VERSION "$Format:%h$"

NS_ :

BS_:

BU_: APB APP APS BCCEN BDY DAS DBG EAS EPAS EPAS2 EPAS3S EPB EPBM ESP GTW GTWU IBST IC MCU OCS PARK PARK3 RADAR RCM RT3000 SCCM SDM SEC TAS TAS2 TAS2DBG TOOL TPMS VCSEATD VCSEATP
VAL_TABLE_ APP_ussSequenceEnum 12 "APP_USS_SEQUENCE_FMS_FAST" 2 "APP_USS_SEQUENCE_UPA" 0 "APP_USS_SEQUENCE_FMS_SLOW" ;
VAL_TABLE_ BC_firstRollRecallIndex 1 "BC_FIRST_ROW_RECALL_PASSENGER" 0 "BC_FIRST_ROW_RECALL_DRIVER" ;
VAL_TABLE_ BC_indicatorLStatus 3 "default" 2 "Failed" 1 "On" 0 "Off" ;
VAL_TABLE_ BC_indicatorRStatus 3 "default" 2 "Failed" 1 "On" 0 "Off" ;
VAL_TABLE_ CAN_error 9 "CAN_ERROR_TWO_SLAVES" 8 "CAN_ERROR_TWO_MASTERS" 7 "CAN_ERROR_RESET_CMD" 6 "CAN_ERROR_OVERRUN" 5 "CAN_ERROR_TX" 4 "CAN_ERROR_RX" 3 "CAN_ERROR_NODEBUG" 2 "CAN_ERROR_DATA" 1 "CAN_ERROR_CHECKSUM" 0 "CAN_ERROR_LENGTH" ;
VAL_TABLE_ CHG_inputRelayState 3 "CHG_INPUT_RELAY_SNA" 2 "CHG_INPUT_RELAY_OPEN" 1 "CHG_INPUT_RELAY_L1_CLOSED" 0 "CHG_INPUT_RELAY_L2_CLOSED" ;
VAL_TABLE_ CHG_phaseConfig 4 "PHASE_CONFIG_SNA" 3 "TWO_PHASE_DELTA_THREE_CHGPH" 2 "TWO_PHASE_DELTA_TWO_CHGPH" 1 "THREE_PHASE" 0 "SINGLE_PHASE" ;
VAL_TABLE_ CH_NM_wakeUpReason 3 "CH_WAKEUP_REASON_RESET" 2 "CH_WAKEUP_REASON_SWITCH_INPUT" 1 "CH_WAKEUP_REASON_ECU_SPECIFIC" 0 "CH_WAKEUP_REASON_NONE" ;
VAL_TABLE_ ChassisType 3 "CHASSIS_MODEL3" 2 "CHASSIS_MODELX" 1 "CHASSIS_MODELS" 0 "CHASSIS_UNKNOWN" ;
VAL_TABLE_ DAS_DepartureWarning 3 "SNA" 2 "RIGHT_WARNING" 1 "LEFT_WARNING" 0 "NONE" ;
VAL_TABLE_ DAS_LaneDepartureWarningStatus 3 "DEGRADED" 2 "FAILED" 1 "INACTIVE" 0 "ACTIVE" ;
VAL_TABLE_ DAS_LaneTypeColor 15 "SNA" 14 "INVALID_YELLOW" 13 "BOTTS_DOTS_YELLOW" 12 "DOUBLE_LANE_YELLOW" 11 "ROAD_EDGE_YELLOW" 10 "UNDECIDED_YELLOW" 9 "SOLID_YELLOW" 8 "DASHED_YELLOW" 6 "INVALID" 5 "BOTTS_DOTS" 4 "DOUBLE_LANE" 3 "ROAD_EDGE" 2 "UNDECIDED" 1 "SOLID" 0 "DASHED" ;
VAL_TABLE_ DAS_NM_keepAwakeReason 2 "DAS_KEEPAWAKE_REASON_TELEMETRY" 1 "DAS_KEEPAWAKE_REASON_PRECONDITIONING" 0 "DAS_KEEPAWAKE_REASON_NONE_SNA" ;
VAL_TABLE_ DAS_SignType 255 "E_INVALID_SIGN" 254 "NO_SIGN_DETECTED" 221 "STANDARD_ELECTR_END_OF_NO_PASSING" 220 "STANDARD_ELECTR_NO_PASSING_START" 201 "REGULAR_END_OF_NO_PASSING" 200 "REGULAR_NO_PASSING_START" 176 "REGULAR_END_OF_PLAYGROUND_AREA" 175 "REGULAR_PLAYGROUND_AREA_BEGIN" 174 "STANDARD_REGULAR_END_OF_EXPRESSWAY" 173 "STANDARD_REGULAR_EXPRESSWAY_BEGIN" 172 "STANDARD_REGULAR_END_OF_MOTORWAY" 171 "STANDARD_REGULAR_MOTORWAY_BEGIN" 129 "STANDARD_ELECTRONIC_145" 128 "STANDARD_ELECTRONIC_135" 127 "STANDARD_ELECTRONIC_125" 126 "STANDARD_ELECTRONIC_115" 125 "STANDARD_ELECTRONIC_105" 124 "STANDARD_ELECTRONIC_95" 123 "STANDARD_ELECTRONIC_85" 122 "STANDARD_ELECTRONIC_75" 121 "STANDARD_ELECTRONIC_65" 120 "STANDARD_ELECTRONIC_55" 119 "STANDARD_ELECTRONIC_45" 118 "STANDARD_ELECTRONIC_35" 117 "STANDARD_ELECTRONIC_25" 116 "STANDARD_ELECTRONIC_15" 115 "STANDARD_ELECTRONIC_5" 114 "STANDARD_REGULAR_145" 113 "STANDARD_REGULAR_135" 112 "STANDARD_REGULAR_125" 111 "STANDARD_REGULAR_115" 110 "STANDARD_REGULAR_105" 109 "STANDARD_REGULAR_95" 108 "STANDARD_REGULAR_85" 107 "STANDARD_REGULAR_75" 106 "STANDARD_REGULAR_65" 105 "STANDARD_REGULAR_55" 104 "STANDARD_REGULAR_45" 103 "STANDARD_REGULAR_35" 102 "STANDARD_REGULAR_25" 101 "STANDARD_REGULAR_15" 100 "STANDARD_REGULAR_5" 65 "ELECTRIC_GEN_END_ALL_RESTRICTION" 64 "REGULAR_GEN_END_ALL_RESTRICT" 50 "ELECTRONIC_END_OF_NUM_RESTRICT" 41 "STANDARD_ELECTRONIC_140" 40 "STANDARD_ELECTRONIC_130" 39 "STANDARD_ELECTRONIC_120" 38 "STANDARD_ELECTRONIC_110" 37 "STANDARD_ELECTRONIC_100" 36 "STANDARD_ELECTRONIC_90" 35 "STANDARD_ELECTRONIC_80" 34 "STANDARD_ELECTRONIC_70" 33 "STANDARD_ELECTRONIC_60" 32 "STANDARD_ELECTRONIC_50" 31 "STANDARD_ELECTRONIC_40" 30 "STANDARD_ELECTRONIC_30" 29 "STANDARD_ELECTRONIC_20" 28 "STANDARD_ELECTRONIC_10" 20 "STANDARD_END_OF_NUM_RESTRICTION" 13 "STANDARD_REGULAR_140" 12 "STANDARD_REGULAR_130" 11 "STANDARD_REGULAR_120" 10 "STANDARD_REGULAR_110" 9 "STANDARD_REGULAR_100" 8 "STANDARD_REGULAR_90" 7 "STANDARD_REGULAR_80" 6 "STANDARD_REGULAR_70" 5 "STANDARD_REGULAR_60" 4 "STANDARD_REGULAR_50" 3 "STANDARD_REGULAR_40" 2 "STANDARD_REGULAR_30" 1 "STANDARD_REGULAR_20" 0 "STANDARD_REGULAR_10" ;
VAL_TABLE_ DAS_SteeringAngleRequest 16384 "ZERO_ANGLE" ;
VAL_TABLE_ DAS_aebEvent 3 "AEB_SNA" 2 "AEB_FAULT" 1 "AEB_ACTIVE" 0 "AEB_NOT_ACTIVE" ;
VAL_TABLE_ DAS_csa_internal_state 4 "CSA_INTERNAL_STATE_ENABLE_HOLD" 3 "CSA_INTERNAL_STATE_ENABLE_ACCELEROMETER" 2 "CSA_INTERNAL_STATE_ENABLE_PREDICTED" 1 "CSA_INTERNAL_STATE_AVAILABLE" 0 "CSA_INTERNAL_STATE_UNAVAILABLE" ;
VAL_TABLE_ DAS_eyeqAlert 3 "a003_eyeq_watchdog_reset" 2 "a002_eyeq_communication_timeout" 1 "a001_eyeq_boot_failure" ;
VAL_TABLE_ DAS_fork 3 "FORK_UNAVAILABLE" 2 "FORK_SELECTED" 1 "FORK_AVAILABLE" 0 "FORK_NONE" ;
VAL_TABLE_ DAS_hazardLightRequest 3 "DAS_REQUEST_HAZARDS_SNA" 2 "DAS_REQUEST_HAZARDS_UNUSED" 1 "DAS_REQUEST_HAZARDS_ON" 0 "DAS_REQUEST_HAZARDS_OFF" ;
VAL_TABLE_ DAS_headlightRequest 3 "DAS_HEADLIGHT_REQUEST_INVALID" 1 "DAS_HEADLIGHT_REQUEST_ON" 0 "DAS_HEADLIGHT_REQUEST_OFF" ;
VAL_TABLE_ DAS_highLowBeamDecision 3 "DAS_HIGH_BEAM_SNA" 2 "DAS_HIGH_BEAM_ON" 1 "DAS_HIGH_BEAM_OFF" 0 "DAS_HIGH_BEAM_UNDECIDED" ;
VAL_TABLE_ DAS_highLowBeamOffReason 5 "HIGH_BEAM_OFF_REASON_SNA" 4 "HIGH_BEAM_OFF_REASON_HEAD_LIGHT" 3 "HIGH_BEAM_OFF_REASON_AMBIENT_LIGHT" 2 "HIGH_BEAM_OFF_REASON_MOVING_RADAR_TARGET" 1 "HIGH_BEAM_OFF_REASON_MOVING_VISION_TARGET" 0 "HIGH_BEAM_ON" ;
VAL_TABLE_ DAS_infoIndex 255 "DAS_INFO_END" 24 "DAS_INFO_EYEQ_FFS" 23 "DAS_INFO_EYEQ_APP" 20 "DAS_INFO_UDS_PROTOCOL_BOOTCRC" 19 "DAS_INFO_VERSION_DEPRECATED" 18 "DAS_INFO_BOOTLOADER_GITHASH" 17 "DAS_INFO_APP_GITHASH" 16 "DAS_INFO_EYEQ_BOOT" 15 "DAS_INFO_BOOTLOADER_CRC" 14 "DAS_INFO_BOOTLOADER_SVN" 13 "DAS_INFO_APP_CRC" 11 "DAS_INFO_PCBAID_ASSYID_USAGEID" 10 "DAS_INFO_BUILD_HWID_COMPONENTID" 9 "DAS_INFO_DEPRECATED_9" 8 "DAS_INFO_DEPRECATED_8" 7 "DAS_INFO_DEPRECATED_7" 6 "DAS_INFO_DEPRECATED_6" 5 "DAS_INFO_DEPRECATED_5" 4 "DAS_INFO_DEPRECATED_4" 3 "DAS_INFO_DEPRECATED_3" 2 "DAS_INFO_DEPRECATED_2" 1 "DAS_INFO_DEPRECATED_1" 0 "DAS_INFO_DEPRECATED_0" ;
VAL_TABLE_ DAS_locMode 3 "DAS_LOC_DRIVERLESS" 2 "DAS_LOC_RESTRICTED" 1 "DAS_LOC_NORMAL" 0 "DAS_LOC_OFF" ;
VAL_TABLE_ DAS_locRequest 4 "DAS_RQ_PARK" 3 "DAS_RQ_HOLD" 2 "DAS_RQ_BACKWARD" 1 "DAS_RQ_FORWARD" 0 "DAS_RQ_IDLE" ;
VAL_TABLE_ DAS_locState 7 "DAS_LOC_FAULT_SNA" 6 "DAS_LOC_AEB_ACTIVE" 2 "DAS_LOC_CANCEL_SILENT" 1 "DAS_LOC_CANCEL_GENERIC" 0 "DAS_LOC_HEALTHY" ;
VAL_TABLE_ DAS_steeringLKAOperatingStatus 3 "Not_available" 2 "Not_used" 1 "Operating" 0 "Inhibited" ;
VAL_TABLE_ DAS_sw019_020_taskID 33 "MAX_TASK_ID" 32 "TASKS_ISOTERM_A72" 31 "TASKS_ISOTERM_SMS" 30 "TASKS_APP_1HZ" 29 "TASKS_APP_1KHZ" 28 "TASKS_SMS_SERIAL" 27 "TASKS_CAN_AP_RX" 26 "TASKS_CAN_AP_TX" 25 "TASKS_TMU" 24 "TASKS_WDG_TASK" 23 "TASKS_MBX_RELAY" 22 "TASKS_MBX_SCS_RX_HIGH" 21 "TASKS_MBX_SCS_RX_LOW" 20 "TASKS_MBX_SCS_TX_HIGH" 19 "TASKS_MBX_SCS_TX_LOW" 18 "TASKS_MBX_AP_RX_HIGH" 17 "TASKS_MBX_AP_RX_LOW" 16 "TASKS_MBX_AP_TX_HIGH" 15 "TASKS_MBX_AP_TX_LOW" 14 "TASKS_VEH_CAN" 13 "TASKS_RADAR_CAN" 12 "TASKS_CH_CAN" 11 "TASKS_PARTY_CAN" 10 "TASK_DEBUG_SMS_SERIAL_RX" 9 "TASK_DEBUG_SERIAL_TX" 8 "TASKS_SMS_SMS_UART_RX" 7 "TASKS_SMS_SMS_UART_TX" 6 "TASK_SMS_SMS_UART_TX" 5 "TASKS_VEHICLE" 4 "TASKS_MOBILEYE" 3 "TASKS_UDS" 2 "TASKS_CAN" 1 "TASKS_INIT" 0 "TASKS_RESERVED" ;
VAL_TABLE_ DAS_sw021_tempSensorId 4 "DDR_TEMP_SENSOR" 3 "CAMERA_TEMP_SENSOR" 2 "EYE_Q_TEMP_SENSOR_1" 1 "EYE_Q_TEMP_SENSOR_0" 0 "EXTERNAL_TEMP_SENSOR" ;
VAL_TABLE_ DAS_sw022_operation 4 "Erase All" 3 "Delete" 2 "Read" 1 "Write" 0 "Initialize" ;
VAL_TABLE_ DAS_sw024_heaterState 2 "SHORT" 1 "OPEN" 0 "NORMAL" ;
VAL_TABLE_ DAS_sw037_issue 1 "Invalid parameters" 0 "Failed to read" ;
VAL_TABLE_ DAS_sw043_mesp_health_main_state 172 "EYEQ_MESP_MAIN_STATE_TAC2" 170 "EYEQ_MESP_MAIN_STATE_DV" 146 "EYEQ_MESP_MAIN_STATE_VISION_INIT_PENDING" 133 "EYEQ_MESP_MAIN_STATE_TAC2_INIT_PENDING" 130 "EYEQ_MESP_MAIN_STATE_SPC_INIT_PENDING" 129 "EYEQ_MESP_MAIN_STATE_SPTAC_INIT_PENDING" 34 "EYEQ_MESP_MAIN_STATE_SPC" 33 "EYEQ_MESP_MAIN_STATE_SPTAC" 2 "EYEQ_MESP_MAIN_STATE_VISION" ;
VAL_TABLE_ DAS_sw043_mobileye_status 24 "MOBILEYE_STATUS_UNDEFINED" 23 "MOBILEYE_STATUS_TEARDOWN_FLASH_ACCESS_MODE" 22 "MOBILEYE_STATUS_FLASH_READ_MODE" 21 "MOBILEYE_STATUS_SETUP_FLASH_ACCESS_MODE" 20 "MOBILEYE_STATUS_RUNNING_SPTAC_MODE" 19 "MOBILEYE_STATUS_SPTAC_INIT_SENT" 18 "MOBILEYE_STATUS_WAITING_FOR_SPTAC_INIT" 17 "MOBILEYE_STATUS_BURN_EDR_MODE" 16 "MOBILEYE_STATUS_SPC_INIT_SENT" 15 "MOBILEYE_STATUS_WAITING_FOR_SPC_INIT" 14 "MOBILEYE_STATUS_ERROR" 13 "MOBILEYE_STATUS_LATCHING_FAILURE" 12 "MOBILEYE_STATUS_UPDATING" 11 "MOBILEYE_STATUS_RUNNING_DV_MODE" 10 "MOBILEYE_STATUS_WAITING_FOR_DV" 9 "MOBILEYE_STATUS_RUNNING_TAC_MODE" 8 "MOBILEYE_STATUS_RUNNING_SPC_MODE" 7 "MOBILEYE_STATUS_RUNNING_VISION_MODE" 6 "MOBILEYE_STATUS_TAC_INIT_SENT" 5 "MOBILEYE_STATUS_WAITING_FOR_TAC_INIT" 4 "MOBILEYE_STATUS_VISION_INIT_SENT" 3 "MOBILEYE_STATUS_WAITING_FOR_VISION_INIT" 2 "MOBILEYE_STATUS_WAITING_FOR_BOOT" 1 "MOBILEYE_STATUS_POWER_OFF" 0 "MOBILEYE_STATUS_POWER_CYCLE" ;
VAL_TABLE_ DAS_turnIndicatorRequest 3 "DAS_TURN_INDICATOR_CANCEL" 2 "DAS_TURN_INDICATOR_RIGHT" 1 "DAS_TURN_INDICATOR_LEFT" 0 "DAS_TURN_INDICATOR_NONE" ;
VAL_TABLE_ DAS_turnIndicatorRequestReason 12 "DAS_CANCEL_SUMMMON" 11 "DAS_ACTIVE_SUMMMON" 10 "DAS_CANCEL_INTERSECTION" 9 "DAS_ACTIVE_INTERSECTION" 8 "DAS_ACTIVE_COMMANDED_LANE_CHANGE" 7 "DAS_CANCEL_MERGE" 6 "DAS_ACTIVE_MERGE" 5 "DAS_CANCEL_FORK" 4 "DAS_CANCEL_LANE_CHANGE" 3 "DAS_ACTIVE_FORK" 2 "DAS_ACTIVE_SPEED_LANE_CHANGE" 1 "DAS_ACTIVE_NAV_LANE_CHANGE" 0 "DAS_NONE" ;
VAL_TABLE_ DAS_wiperSpeed 15 "DAS_WIPER_SPEED_INVALID" 14 "DAS_WIPER_SPEED_14" 13 "DAS_WIPER_SPEED_13" 12 "DAS_WIPER_SPEED_12" 11 "DAS_WIPER_SPEED_11" 10 "DAS_WIPER_SPEED_10" 9 "DAS_WIPER_SPEED_9" 8 "DAS_WIPER_SPEED_8" 7 "DAS_WIPER_SPEED_7" 6 "DAS_WIPER_SPEED_6" 5 "DAS_WIPER_SPEED_5" 4 "DAS_WIPER_SPEED_4" 3 "DAS_WIPER_SPEED_3" 2 "DAS_WIPER_SPEED_2" 1 "DAS_WIPER_SPEED_1" 0 "DAS_WIPER_SPEED_OFF" ;
VAL_TABLE_ DI_aebState 7 "AEB_CAN_STATE_SNA" 4 "AEB_CAN_STATE_FAULT" 3 "AEB_CAN_STATE_STANDSTILL" 2 "AEB_CAN_STATE_ENABLED" 1 "AEB_CAN_STATE_STANDBY" 0 "AEB_CAN_STATE_UNAVAILABLE" ;
VAL_TABLE_ DI_crsState 7 "DI_CRS_FAULT" 3 "DI_CRS_SLOWDOWN" 2 "DI_CRS_ACTIVE" 1 "DI_CRS_STANDBY" 0 "DI_CRS_UNAVAILABLE" ;
VAL_TABLE_ DI_immobilizerState 6 "DI_IMM_STATE_FAULT" 5 "DI_IMM_STATE_RESET" 4 "DI_IMM_STATE_IDLE" 3 "DI_IMM_STATE_DISARMED" 2 "DI_IMM_STATE_AUTHENTICATING" 1 "DI_IMM_STATE_REQUEST" 0 "DI_IMM_STATE_INIT_SNA" ;
VAL_TABLE_ DI_locState 7 "DI_LOC_FAULT" 6 "DI_LOC_ABORTING" 5 "DI_LOC_PAUSED" 4 "DI_LOC_STANDSTILL" 3 "DI_LOC_OVERRIDE" 2 "DI_LOC_ACTIVE" 1 "DI_LOC_STANDBY" 0 "DI_LOC_UNAVAILABLE" ;
VAL_TABLE_ DI_onePedalDrivingState 8 "DI_OPD_NUM_STATES" 7 "DI_OPD_MOTOR_BLEND_IN" 6 "DI_OPD_NO_MOTOR" 5 "DI_OPD_MOTOR_BLEND_OUT_ACTIVE" 4 "DI_OPD_MOTOR_BLEND_OUT_PENDING" 3 "DI_OPD_NOMINAL" 2 "DI_OPD_STANDBY" 1 "DI_OPD_QUICK_BRAKE_RAMP" 0 "DI_OPD_UNAVAILABLE" ;
VAL_TABLE_ DI_parkBrakeState 15 "DI_PBRK_SNA" 7 "DI_PBRK_RELEASING" 6 "DI_PBRK_PANIC_SKID" 5 "DI_PBRK_PANIC_EPB" 4 "DI_PBRK_FAULTED" 3 "DI_PBRK_APPLIED" 2 "DI_PBRK_REQUESTED" 1 "DI_PBRK_RELEASED" 0 "DI_PBRK_UNAVAILABLE" ;
VAL_TABLE_ DI_pmmStatus 3 "DI_PMM_SNA" 1 "DI_PMM_ACTIVE" 0 "DI_PMM_INACTIVE" ;
VAL_TABLE_ DI_state 4 "DI_STATE_ENABLE" 3 "DI_STATE_ABORT" 2 "DI_STATE_FAULT" 1 "DI_STATE_STANDBY" 0 "DI_STATE_UNAVAILABLE" ;
VAL_TABLE_ DI_systemState 4 "DI_SYS_ENABLE" 3 "DI_SYS_ABORT" 2 "DI_SYS_FAULT" 1 "DI_SYS_STANDBY" 0 "DI_SYS_UNAVAILABLE" ;
VAL_TABLE_ DI_tractionControlMode 5 "TC_DYNO_MODE" 4 "TC_ROLLS_MODE" 3 "TC_DEV_MODE_2" 2 "TC_DEV_MODE_1" 1 "TC_SLIP_START" 0 "TC_NORMAL" ;
VAL_TABLE_ DI_vdcCommandABS 4 "MODIFY_BY_ABS_NO_GMA_NO_EBD" 3 "MODIFY_BY_ABS_NO_GMA" 2 "MODIFY_BY_ABS_ALL" 1 "FEED_THROUGH" 0 "NO_COMMAND" ;
VAL_TABLE_ DI_vdcCommandType 3 "VDC_SLIP_COMMAND" 2 "VDC_TORQUE_COMMAND" 1 "BTC_TORQUE_COMMAND" 0 "NO_TORQUE_COMMAND" ;
VAL_TABLE_ DTC_VALUES 3 "UNABLE_TO_TEST_DTC" 2 "FAILED_DTC" 1 "PASSED_DTC" 0 "NOT_TESTED_DTC" ;
VAL_TABLE_ EFUSE_airCompressorStatus 7 "EFUSE_AIR_COMPRESSOR_STATUS_SNA" 5 "EFUSE_AIR_COMPRESSOR_STATUS_RETRY_AVAILABLE" 4 "EFUSE_AIR_COMPRESSOR_STATUS_FAULT" 3 "EFUSE_AIR_COMPRESSOR_STATUS_TURNING_ON" 2 "EFUSE_AIR_COMPRESSOR_STATUS_TURNING_OFF" 1 "EFUSE_AIR_COMPRESSOR_STATUS_ON" 0 "EFUSE_AIR_COMPRESSOR_STATUS_OFF" ;
VAL_TABLE_ EFUSE_loadshedLevel 3 "EFUSE_LOADSHED_LEVEL_3" 2 "EFUSE_LOADSHED_LEVEL_2" 1 "EFUSE_LOADSHED_LEVEL_1" 0 "EFUSE_LOADSHED_LEVEL_NONE_SNA" ;
VAL_TABLE_ EPBM_alerts 128 "EPBM_a128_unused" 127 "EPBM_a127_unused" 126 "EPBM_a126_unused" 125 "EPBM_a125_unused" 124 "EPBM_a124_unused" 123 "EPBM_a123_unused" 122 "EPBM_a122_unused" 121 "EPBM_a121_unused" 120 "EPBM_a120_unused" 119 "EPBM_a119_unused" 118 "EPBM_a118_unused" 117 "EPBM_a117_usedFallbackValues" 116 "EPBM_a116_rightPVoltageHigh" 115 "EPBM_a115_rightNVoltageLow" 114 "EPBM_a114_unparkNotAllowed" 113 "EPBM_a113_calFaultRight" 112 "EPBM_a112_calFaultLeft" 111 "EPBM_a111_calWarningRight" 110 "EPBM_a110_calWarningLeft" 109 "EPBM_a109_unused" 108 "EPBM_a108_unused" 107 "EPBM_a107_currentWarning" 106 "EPBM_a106_voltageWarning" 105 "EPBM_a105_epbWentToSleep" 104 "EPBM_a104_epbStillAsleep" 103 "EPBM_a103_targetNotReachedR" 102 "EPBM_a102_targetNotReachedL" 101 "EPBM_a101_calibrationFault" 100 "EPBM_a100_calibrationWarning" 99 "EPBM_a099_unused" 98 "EPBM_a098_pmMia" 97 "EPBM_a097_parkMia" 96 "EPBM_a096_selfParkAborted" 95 "EPBM_a095_invalidConfig" 94 "EPBM_a094_unused" 93 "EPBM_a093_dasMIA" 92 "EPBM_a092_noCurrentCalR" 91 "EPBM_a091_spuriousEncIntR" 90 "EPBM_a090_rightUnderRelease" 89 "EPBM_a089_rightOverRelease" 88 "EPBM_a088_rightUnderApply" 87 "EPBM_a087_rightOverApply" 86 "EPBM_a086_rightSubstateErr" 85 "EPBM_a085_rightPvUv" 84 "EPBM_a084_rightPvOv" 83 "EPBM_a083_rightNvUv" 82 "EPBM_a082_rightNvOv" 81 "EPBM_a081_rightNHalfBridge" 80 "EPBM_a080_rightPHalfBridge" 79 "EPBM_a079_rightDriveDuration" 78 "EPBM_a078_rightEnaStuckLow" 77 "EPBM_a077_rightEnaStuckHigh" 76 "EPBM_a076_rightPOpen" 75 "EPBM_a075_rightNOpen" 74 "EPBM_a074_rightPShort" 73 "EPBM_a073_rightNShort" 72 "EPBM_a072_rightShortApply" 71 "EPBM_a071_rightEndStop" 70 "EPBM_a070_rightUc" 69 "EPBM_a069_rightOc" 68 "EPBM_a068_rightEncoderSna" 67 "EPBM_a067_rightEncIrrational" 66 "EPBM_a066_rightIdleOc" 65 "EPBM_a065_rightEncIntrpt" 64 "EPBM_a064_unused" 63 "EPBM_a063_unused" 62 "EPBM_a062_diGearInvld" 61 "EPBM_a061_maxCycles2" 60 "EPBM_a060_maxCycles1" 59 "EPBM_a059_battMismatch" 58 "EPBM_a058_5vLost" 57 "EPBM_a057_12vUv" 56 "EPBM_a056_12vOv" 55 "EPBM_a055_stackOverflow" 54 "EPBM_a054_unused" 53 "EPBM_a053_unused" 52 "EPBM_a052_leftPVoltageHigh" 51 "EPBM_a051_leftNVoltageLow" 50 "EPBM_a050_mcuMIA" 49 "EPBM_a049_espMIA" 48 "EPBM_a048_chgMIA" 47 "EPBM_a047_epbMIA" 46 "EPBM_a046_sccmMIA" 45 "EPBM_a045_gtwMIA" 44 "EPBM_a044_diMIA" 43 "EPBM_a043_absMIA" 42 "EPBM_a042_spiRead" 41 "EPBM_a041_spiOpen" 40 "EPBM_a040_memoryError" 39 "EPBM_a039_watchdogReset" 38 "EPBM_a038_eeprom" 37 "EPBM_a037_firmware" 36 "EPBM_a036_canOverrun" 35 "EPBM_a035_canErr" 34 "EPBM_a034_canData" 33 "EPBM_a033_canHardware" 32 "EPBM_a032_reqStateErr" 31 "EPBM_a031_stateErr" 30 "EPBM_a030_interProcSpi" 29 "EPBM_a029_canDisabled" 28 "EPBM_a028_noCurrentCalL" 27 "EPBM_a027_spuriousEncIntL" 26 "EPBM_a026_leftUnderRelease" 25 "EPBM_a025_leftOverRelease" 24 "EPBM_a024_leftUnderApply" 23 "EPBM_a023_leftOverApply" 22 "EPBM_a022_leftSubstateErr" 21 "EPBM_a021_leftPvUv" 20 "EPBM_a020_leftPvOv" 19 "EPBM_a019_leftNvUv" 18 "EPBM_a018_leftNvOv" 17 "EPBM_a017_leftNHalfBridge" 16 "EPBM_a016_leftPHalfBridge" 15 "EPBM_a015_leftDriveDuration" 14 "EPBM_a014_leftEnaStuckLow" 13 "EPBM_a013_leftEnaStuckHigh" 12 "EPBM_a012_leftPOpen" 11 "EPBM_a011_leftNOpen" 10 "EPBM_a010_leftPShort" 9 "EPBM_a009_leftNShort" 8 "EPBM_a008_leftShortApply" 7 "EPBM_a007_leftEndStop" 6 "EPBM_a006_leftUc" 5 "EPBM_a005_leftOc" 4 "EPBM_a004_leftEncoderSna" 3 "EPBM_a003_leftEncIrrational" 2 "EPBM_a002_leftIdleOc" 1 "EPBM_a001_leftEncIntrpt" ;
VAL_TABLE_ EPBM_clampCurrentMonitor 3 "CURRENT_TARGET_NOT_REACHED" 2 "CURRENT_TARGET_REACHED" 0 "CURRENT_MONITOR_IDLE" ;
VAL_TABLE_ EPBM_substate 4 "EPBM_SUBSTATE_CTRL_FAULT" 3 "EPBM_SUBSTATE_FAULT" 2 "EPBM_SUBSTATE_RELEASING" 1 "EPBM_SUBSTATE_APPLYING" 0 "EPBM_SUBSTATE_STATIONARY" ;
VAL_TABLE_ EPB_CAN_error 8 "DENIED" 7 "BUSY" 6 "NODEBUG" 5 "INVALID" 4 "SEQUENCE" 3 "CHECKSUM" 2 "LENGTH_LONG" 1 "LENGTH_SHORT" 0 "NO_ERROR" ;
VAL_TABLE_ EPB_EEP_datatype 5 "EEP_CHASSIS_TYPE_DATATYPE" 4 "EEP_EPAS_TYPE_DATATYPE" 3 "EEP_STATISTICS_DATATYPE" 2 "EEP_BRAKE_HW_TYPE_DATATYPE" 1 "EEP_STATE_DATATYPE" 0 "EEP_NONE_DATATYPE" ;
VAL_TABLE_ EPB_alerts 8204 "EPB_u012_mcuParkUnavailable" 8203 "EPB_u011_parkSlope" 8202 "EPB_u010_serviceModeEnabled" 8201 "EPB_u009_towModeEnabled" 8200 "EPB_u008_turnOnCarToPark" 8199 "EPB_u007_dynNotApplied" 8198 "EPB_u006_epbNotReleased" 8197 "EPB_u005_epbProblem" 8196 "EPB_u004_pressFootBrake" 8195 "EPB_u003_dynamicBrakeApplied" 8194 "EPB_u002_carMayRoll" 8193 "EPB_u001_calibrationRequired" 192 "EPB_a192_unused" 191 "EPB_a191_unused" 190 "EPB_a190_unused" 189 "EPB_a189_unused" 188 "EPB_a188_unused" 187 "EPB_a187_unused" 186 "EPB_a186_unused" 185 "EPB_a185_unused" 184 "EPB_a184_unused" 183 "EPB_a183_unused" 182 "EPB_a182_unused" 181 "EPB_a181_unused" 180 "EPB_a180_unused" 179 "EPB_a179_unused" 178 "EPB_a178_unused" 177 "EPB_a177_unused" 176 "EPB_a176_unused" 175 "EPB_a175_unused" 174 "EPB_a174_unused" 173 "EPB_a173_unused" 172 "EPB_a172_unused" 171 "EPB_a171_unused" 170 "EPB_a170_unused" 169 "EPB_a169_unused" 168 "EPB_a168_unused" 167 "EPB_a167_unused" 166 "EPB_a166_unused" 165 "EPB_a165_unused" 164 "EPB_a164_unused" 163 "EPB_a163_unused" 162 "EPB_a162_unused" 161 "EPB_a161_unused" 160 "EPB_a160_unused" 159 "EPB_a159_unused" 158 "EPB_a158_unused" 157 "EPB_a157_unused" 156 "EPB_a156_unused" 155 "EPB_a155_unused" 154 "EPB_a154_unused" 153 "EPB_a153_unused" 152 "EPB_a152_unused" 151 "EPB_a151_unused" 150 "EPB_a150_unused" 149 "EPB_a149_unused" 148 "EPB_a148_unused" 147 "EPB_a147_unused" 146 "EPB_a146_unused" 145 "EPB_a145_unused" 144 "EPB_a144_unused" 143 "EPB_a143_unused" 142 "EPB_a142_unused" 141 "EPB_a141_unused" 140 "EPB_a140_unused" 139 "EPB_a139_unused" 138 "EPB_a138_unused" 137 "EPB_a137_unused" 136 "EPB_a136_unused" 135 "EPB_a135_unused" 134 "EPB_a134_unused" 133 "EPB_a133_unused" 132 "EPB_a132_unused" 131 "EPB_a131_unused" 130 "EPB_a130_unused" 129 "EPB_a129_unparkNotAllowed" 128 "EPB_a128_followedDiToPark" 127 "EPB_a127_oocSpeedViolation" 126 "EPB_a126_ShortApplyUF" 125 "EPB_a125_gradeTooSteep" 124 "EPB_a124_releaseDistanceR" 123 "EPB_a123_releaseDistanceL" 122 "EPB_a122_freeRollMdEpbmMismatch" 121 "EPB_a121_releaseLogR" 120 "EPB_a120_releaseLogL" 119 "EPB_a119_freeRollingModeAborted" 118 "EPB_a118_freeRollingModeActive" 117 "EPB_a117_usedFallbackValues" 116 "EPB_a116_unableToCalcGrade" 115 "EPB_a115_currentWarning" 114 "EPB_a114_voltageWarning" 113 "EPB_a113_calFaultRight" 112 "EPB_a112_calFaultLeft" 111 "EPB_a111_calWarningRight" 110 "EPB_a110_calWarningLeft" 109 "EPB_a109_rightPVoltageHigh" 108 "EPB_a108_rightNVoltageLow" 107 "EPB_a107_leftPVoltageHigh" 106 "EPB_a106_leftNVoltageLow" 105 "EPB_a105_epbmWentToSleep" 104 "EPB_a104_epbmStillAsleep" 103 "EPB_a103_eepromUpdated" 102 "EPB_a102_eepromCorrupt" 101 "EPB_a101_calibrationFault" 100 "EPB_a100_calibrationWarning" 99 "EPB_a099_pmMia" 98 "EPB_a098_parkMia" 97 "EPB_a097_selfParkAborted" 96 "EPB_a096_epasMia" 95 "EPB_a095_invalidConfig" 94 "EPB_a094_inhibitEac" 93 "EPB_a093_dasMIA" 92 "EPB_a092_obsolete" 91 "EPB_a091_spuriousEncIntR" 90 "EPB_a090_noCurrentCalR" 89 "EPB_a089_motorShortedApplyR" 88 "EPB_a088_motorShortedReleaseR" 87 "EPB_a087_rightFirstShortApply" 86 "EPB_a086_rightSubstateErr" 85 "EPB_a085_rightPvUv" 84 "EPB_a084_rightPvOv" 83 "EPB_a083_rightNvUv" 82 "EPB_a082_rightNvOv" 81 "EPB_a081_rightNHalfBridge" 80 "EPB_a080_rightPHalfBridge" 79 "EPB_a079_rightDriveDuration" 78 "EPB_a078_rightEnaStuckLow" 77 "EPB_a077_rightEnaStuckHigh" 76 "EPB_a076_rightPOpen" 75 "EPB_a075_rightNOpen" 74 "EPB_a074_rightPShort" 73 "EPB_a073_rightNShort" 72 "EPB_a072_rightShortApply" 71 "EPB_a071_rightEndStop" 70 "EPB_a070_rightUc" 69 "EPB_a069_rightOc" 68 "EPB_a068_rightEncoderSna" 67 "EPB_a067_rightEncIrrational" 66 "EPB_a066_rightIdleOc" 65 "EPB_a065_rightEncIntrpt" 64 "EPB_a064_EPBMTimeout" 63 "EPB_a063_parkWhlSpeed" 62 "EPB_a062_diGearInvld" 61 "EPB_a061_maxCycles2" 60 "EPB_a060_maxCycles1" 59 "EPB_a059_battMismatch" 58 "EPB_a058_5vLost" 57 "EPB_a057_12vUv" 56 "EPB_a056_12vOv" 55 "EPB_a055_stackOverflow" 54 "EPB_a054_severeShortApply" 53 "EPB_a053_epbNotReleased" 52 "EPB_a052_epbProblem" 51 "EPB_a051_epbNotApplied" 50 "EPB_a050_resetRequired" 49 "EPB_a049_espMIA" 48 "EPB_a048_mcuMIA" 47 "EPB_a047_epbmMIA" 46 "EPB_a046_sccmMIA" 45 "EPB_a045_gtwMIA" 44 "EPB_a044_diMIA" 43 "EPB_a043_absMIA" 42 "EPB_a042_spiRead" 41 "EPB_a041_spiOpen" 40 "EPB_a040_memoryError" 39 "EPB_a039_watchdogReset" 38 "EPB_a038_eeprom" 37 "EPB_a037_firmware" 36 "EPB_a036_canOverrun" 35 "EPB_a035_canErr" 34 "EPB_a034_canData" 33 "EPB_a033_canHardware" 32 "EPB_a032_canDisabled" 31 "EPB_a031_chgMIA" 30 "EPB_a030_interProcSpi" 29 "EPB_a029_stateErr" 28 "EPB_a028_reqStateErr" 27 "EPB_a027_spuriousEncIntL" 26 "EPB_a026_noCurrentCalL" 25 "EPB_a025_motorShortedApplyL" 24 "EPB_a024_motorShortedReleaseL" 23 "EPB_a023_leftFirstShortApply" 22 "EPB_a022_leftSubstateErr" 21 "EPB_a021_leftPvUv" 20 "EPB_a020_leftPvOv" 19 "EPB_a019_leftNvUv" 18 "EPB_a018_leftNvOv" 17 "EPB_a017_leftNHalfBridge" 16 "EPB_a016_leftPHalfBridge" 15 "EPB_a015_leftDriveDuration" 14 "EPB_a014_leftEnaStuckLow" 13 "EPB_a013_leftEnaStuckHigh" 12 "EPB_a012_leftPOpen" 11 "EPB_a011_leftNOpen" 10 "EPB_a010_leftPShort" 9 "EPB_a009_leftNShort" 8 "EPB_a008_leftShortApply" 7 "EPB_a007_leftEndStop" 6 "EPB_a006_leftUc" 5 "EPB_a005_leftOc" 4 "EPB_a004_leftEncoderSna" 3 "EPB_a003_leftEncIrrational" 2 "EPB_a002_leftIdleOc" 1 "EPB_a001_leftEncIntrpt" ;
VAL_TABLE_ EPB_calibrationState 4 "CAL_BUSY" 3 "CAL_FAULT" 2 "CAL_WARN" 1 "CAL_NORMAL" 0 "CAL_UNAVAILABLE" ;
VAL_TABLE_ EPB_chassisType 3 "EPB_CHASSIS_TYPE_NONE" 1 "EPB_CHASSIS_TYPE_X" 0 "EPB_CHASSIS_TYPE_S" ;
VAL_TABLE_ EPB_debugDataSelect 9 "EPB_DEBUG_9" 8 "EPB_DEBUG_8" 7 "EPB_DEBUG_7" 6 "EPB_DEBUG_6" 5 "EPB_DEBUG_5" 4 "EPB_DEBUG_4" 3 "EPB_DEBUG_3" 2 "EPB_DEBUG_2" 1 "EPB_DEBUG_1" 0 "EPB_DEBUG_0" ;
VAL_TABLE_ EPB_eacState 4 "EAC_LATERAL_CTRL_INHIBIT" 3 "EAC_LATERAL_CTRL_AUTOPARK" 2 "EAC_LATERAL_CTRL_CONTINUOUS" 1 "EAC_LATERAL_CTRL_MOMENTARY" 0 "EAC_LATERAL_CTRL_INIT" ;
VAL_TABLE_ EPB_freeRollingModeStatus 2 "EPB_FREE_ROLLING_MODE_ENABLED" 1 "EPB_FREE_ROLLING_MODE_AVAILABLE" 0 "EPB_FREE_ROLLING_MODE_UNAVAILABLE" ;
VAL_TABLE_ EPB_ignoreCan 3 "IGNORE_CAN_SNA" 2 "IGNORE_CAN_UPDATE" 1 "LISTEN_TO_CAN" 0 "IGNORE_CAN_BOOT" ;
VAL_TABLE_ EPB_inhibitEacReason 15 "EPB_EAC_FAULT_ELK_LKA_SEQ" 14 "EPB_EAC_FAULT_SCT_EAC_MISMATCH" 13 "EPB_EAC_FAULT_AC_MISMATCH" 12 "EPB_EAC_FAULT_LSS_MISMATCH" 11 "EPB_EAC_FAULT_DURATION_ELK" 10 "EPB_EAC_FAULT_HYSTERESIS_ELK" 9 "EPB_EAC_CONFIG_MISMATCH" 8 "EPB_EAC_FAULT_EPAS" 7 "EPB_EAC_ANGLE_BOUNDS" 6 "EPB_EAC_FAULT_HYSTERESIS_LKA" 5 "EPB_EAC_FAULT_DURATION_LKA" 4 "EPB_EAC_FAULT_DI_FAULT" 3 "EPB_EAC_FAULT_DI_MIA" 2 "EPB_EAC_FAULT_EPAS_MIA" 1 "EPB_EAC_FAULT_DAS_MIA" 0 "EPB_EAC_FAULT_NONE" ;
VAL_TABLE_ EPB_motorSel 1 "RIGHT" 0 "LEFT" ;
VAL_TABLE_ EPB_offsetApplied 2 "EPB_OFFSET_RELEASE" 1 "EPB_OFFSET_DYNAMIC" 0 "EPB_OFFSET_STATIC" ;
VAL_TABLE_ EPB_selfParkFaultReason 23 "EPB_SELFPARKFAULT_PM_MISMATCH" 22 "EPB_SELFPARKFAULT_EPAS_NOT_LEARNED" 21 "EPB_SELFPARKFAULT_CALIBRATION" 20 "EPB_SELFPARKFAULT_DI_STATE_INVALID" 19 "EPB_SELFPARKFAULT_EPB_FAULT" 18 "EPB_SELFPARKFAULT_MISMATCH" 17 "EPB_SELFPARKFAULT_OOC" 16 "EPB_SELFPARKFAULT_PM_REQUEST" 15 "EPB_SELFPARKFAULT_PM_MIA" 14 "EPB_SELFPARKFAULT_PARK_MIA" 13 "EPB_SELFPARKFAULT_EXTERNAL" 12 "EPB_SELFPARKFAULT_SPEED" 11 "EPB_SELFPARKFAULT_EPBM_REQUEST" 10 "EPB_SELFPARKFAULT_EAC_NOT_ALLOWED" 9 "EPB_SELFPARKFAULT_CH_CAN_FAULT" 8 "EPB_SELFPARKFAULT_ESP_FAULT" 7 "EPB_SELFPARKFAULT_DAS_FAULT" 6 "EPB_SELFPARKFAULT_DI_APC_FAULT" 5 "EPB_SELFPARKFAULT_DI_FAULT" 4 "EPB_SELFPARKFAULT_EPBM_MIA" 3 "EPB_SELFPARKFAULT_ESP_MIA" 2 "EPB_SELFPARKFAULT_DAS_MIA" 1 "EPB_SELFPARKFAULT_DI_MIA" 0 "EPB_SELFPARKFAULT_NONE" ;
VAL_TABLE_ EPB_selfParkState 5 "SELFPARK_FAULT" 4 "SELFPARK_COMPLETE" 3 "SELFPARK_ACTIVE" 2 "SELFPARK_ARMED" 1 "SELFPARK_IDLE" 0 "SELFPARK_INIT" ;
VAL_TABLE_ EPB_state 7 "EPB_STATE_SNA" 6 "EPB_STATE_SELFPARK" 5 "EPB_STATE_SERVICE" 4 "EPB_STATE_START" 3 "EPB_STATE_HANDBRAKE" 2 "EPB_STATE_PARK" 1 "EPB_STATE_DYNAMIC" 0 "EPB_STATE_OPEN" ;
VAL_TABLE_ EPB_statsDataSelect 9 "EPB_STATS_9" 8 "EPB_STATS_8" 7 "EPB_STATS_7" 6 "EPB_STATS_6" 5 "EPB_STATS_5" 4 "EPB_STATS_4" 3 "EPB_STATS_3" 2 "EPB_STATS_2" 1 "EPB_STATS_1" 0 "EPB_STATS_0" ;
VAL_TABLE_ EPB_statsSelect 5 "EPB_MAX_DATA" 4 "EPB_DYNAMIC_DATA" 3 "EPB_STATIC3_DATA" 2 "EPB_STATIC2_DATA" 1 "EPB_STATIC1_DATA" 0 "EPB_STATIC0_DATA" ;
VAL_TABLE_ EPB_substate 4 "EPB_SUBSTATE_CLR_FAULT" 3 "EPB_SUBSTATE_FAULT" 2 "EPB_SUBSTATE_RELEASING" 1 "EPB_SUBSTATE_APPLYING" 0 "EPB_SUBSTATE_STATIONARY" ;
VAL_TABLE_ EPB_syncState 3 "EPB_SYNCSTATE_READY" 2 "EPB_SYNCSTATE_SYNCING" 1 "EPB_SYNCSTATE_LOSTSYNC" 0 "EPB_SYNCSTATE_INIT" ;
VAL_TABLE_ EPB_telltale 7 "EPB_TELLTALE_SNA" 3 "LAMP_RED_FLASH_AMBER_ON" 2 "LAMP_AMBER_ON" 1 "LAMP_RED_ON" 0 "LAMP_OFF" ;
VAL_TABLE_ ESP_WheelRotation 3 "WR_NOT_DEFINABLE" 2 "WR_STANDSTILL" 1 "WR_BACKWARD" 0 "WR_FORWARD" ;
VAL_TABLE_ ESP_vdcActuatorState 3 "VDC_COMMAND_INVALID" 2 "VDC_ACTUATOR_AVAILABLE" 1 "VDC_ACTUATOR_DEGRADED" 0 "VDC_ACTUATOR_UNAVAILABLE" ;
VAL_TABLE_ ESP_wheelSaturation 2 "OTHER_LIMIT" 1 "BSC_SLIP_LIMIT" 0 "NOT_SATURATED" ;
VAL_TABLE_ GTW_airSuspensionInstalled 5 "TESLA_ADAPTIVE" 4 "TESLA_PLUS" 3 "TESLA_STANDARD" 2 "PLUS" 1 "STANDARD" 0 "NONE" ;
VAL_TABLE_ GTW_autopilot 4 "BASIC" 3 "SELF_DRIVING" 2 "ENHANCED" 1 "HIGHWAY" 0 "NONE" ;
VAL_TABLE_ GTW_autopilotCameraType 2 "RCCB_CAMERAS" 1 "RCCC_CAMERAS" 0 "UNKNOWN" ;
VAL_TABLE_ GTW_bodyControlsType 1 "TESLA" 0 "PEKTRON" ;
VAL_TABLE_ GTW_brakeHwType 2 "BREMBO_P44_MANDO_43MOC" 1 "BREMBO_P40_MANDO_43MOC" 0 "BREMBO_P40_BREMBO_P28_BREMBO_EPB" ;
VAL_TABLE_ GTW_chassisType 2 "MODEL_3_CHASSIS" 1 "MODEL_X_CHASSIS" 0 "MODEL_S_CHASSIS" ;
VAL_TABLE_ GTW_dasHw 4 "TESLA_AP3" 3 "PARKER_PASCAL_2_5" 2 "PARKER_PASCAL" 1 "MONOCAM" 0 "NONE" ;
VAL_TABLE_ GTW_diagDriveState 4 "DIAG_DRIVE_KEYPAIRING" 3 "DIAG_DRIVE_ENGINEERING" 2 "DIAG_DRIVE_SERVICE" 1 "DIAG_DRIVE_FACTORY" 0 "DIAG_DRIVE_OFF_SNA" ;
VAL_TABLE_ GTW_efuseType 1 "TESLA_REV1" 0 "NONE" ;
VAL_TABLE_ GTW_epasType 4 "MANDO_VGR66_GEN3" 3 "MANDO_VGR66" 2 "MANDO_FGR64" 1 "BOSCH_L405" 0 "BOSCH_L538" ;
VAL_TABLE_ GTW_forwardRadarHw 2 "CONTI_ARS410" 1 "BOSCH_MRR14" 0 "NONE" ;
VAL_TABLE_ GTW_fourWheelDrive 3 "SNA" 2 "UNUSED" 1 "4WD" 0 "2WD" ;
VAL_TABLE_ GTW_parkAssistInstalled 3 "VALEO_5" 2 "BOSCH_5" 1 "BOSCH_4_5" 0 "NONE" ;
VAL_TABLE_ GTW_parkSensorGeometryType 2 "MODELX" 1 "MODELS_2" 0 "MODELS" ;
VAL_TABLE_ GTW_pedalCalRxEnable 1 "ENABLED" 0 "DISABLED" ;
VAL_TABLE_ GTW_pedalCalTargetCurve 6 "SNA" 5 "PEDAL_CURVE_5" 4 "PEDAL_CURVE_4" 3 "PEDAL_CURVE_3" 2 "PEDAL_CURVE_2" 1 "PEDAL_CURVE_1" 0 "PEDAL_CURVE_0" ;
VAL_TABLE_ GTW_performanceConfig 7 "P7" 6 "P6" 5 "P5" 4 "P4" 3 "P3" 2 "P2" 1 "P1" 0 "CONFIG_SNA" ;
VAL_TABLE_ GTW_radarPosition 2 "MODELX" 1 "MODELS_2" 0 "MODELS" ;
VAL_TABLE_ GTW_rearDriveUnitType 1 "SMALL_REAR" 0 "LARGE_REAR" ;
VAL_TABLE_ GTW_restraintControlsType 1 "BOSCH_RCM" 0 "SDM" ;
VAL_TABLE_ GTW_updateInProgress 3 "UPDATE_IN_PROGRESS_SNA" 2 "UPDATE_IN_PROGRESS_NOT_USED" 1 "UPDATE_IN_PROGRESS" 0 "UPDATE_NOT_IN_PROGRESS" ;
VAL_TABLE_ GTW_wheelType 31 "CONFIG_SNA" 26 "TEMPEST_19_SONICSILVER" 25 "TWINTURBINE_21_CARBON" 24 "TWINTURBINE_21_SILVER" 23 "SLIPSTREAM_19_CARBON" 22 "SLIPSTREAM_20_SLVRBLK" 21 "SLIPSTREAM_20_CARBON" 20 "ARACHNID_21_GREY" 19 "ARACHNID_21_BLACK" 18 "ARACHNID_21_SILVER" 17 "TURBINE_22_BLACK" 16 "AERO_TURBINE_20_SLVRBLK" 15 "CYCLONE_19_GREY" 14 "TURBINE_22_SILVER" 13 "AERO_TURBINE_20_SILVER" 12 "HELIX_20_SILVER" 11 "AERO_TURBINE_19_BLACK" 10 "AERO_TURBINE_19_METAL" 9 "TURBINE_19_CHARCOAL" 8 "TURBINE_19" 7 "SUPER_21_SILVER" 6 "SUPER_21_GRAY" 5 "CHARCOAL_21_EURO" 4 "AERO_19" 3 "SILVER_21_EURO" 2 "CHARCOAL_21" 1 "SILVER_21" 0 "BASE_19" ;
VAL_TABLE_ IBST_brakeInputStroke 1023 "INPUT_STROKE_SNA" 1022 "INPUT_STROKE_NOT_VALID" ;
VAL_TABLE_ IC_LEDBrightnessRank 3 "LED_RANK_PA9" 2 "LED_RANK_PA8" 1 "LED_RANK_PA7" 0 "UNKNOWN" ;
VAL_TABLE_ IC_alerts 16 "IC_a016_unused" 15 "IC_a015_unused" 14 "IC_a014_unused" 13 "IC_a013_OVERTEMP_OFF" 12 "IC_a012_CAN_TX_ERRCNT" 11 "IC_a011_CAN_RX_ERRCNT" 10 "IC_a010_SPI_READ" 9 "IC_a009_SPI_OPEN" 8 "IC_a008_MEMORY_ERROR" 7 "IC_a007_WATCHDOG_RESET" 6 "IC_a006_FPGA_ERROR" 5 "IC_a005_FIRMWARE" 4 "IC_a004_CAN_OVERRUN" 3 "IC_a003_CAN_ERR" 2 "IC_a002_CAN_TX" 1 "IC_a001_CAN_RX" 0 "IC_DO_NOT_USE" ;
VAL_TABLE_ IC_componentHardwareRevision 252 "CONFIGURABLE_HWID_PLACEHOLDER" ;
VAL_TABLE_ IC_state 3 "IC_STATE_SOFTWARE_FAULT" 2 "IC_STATE_IDLE" 1 "IC_STATE_CLEAR_TEGRA_RESET" 0 "IC_STATE_WAIT_FOR_TEGRA_PWRGOOD" ;
VAL_TABLE_ LVPowerState 3 "LV_FAULT" 2 "LV_GOING_DOWN" 1 "LV_ON" 0 "LV_OFF" ;
VAL_TABLE_ LogConditions 0 "parkOocValid CH_DAS_pmmLoggingRequest 1" ;
VAL_TABLE_ MCU_clusterInstantOn 0 "ALLOW_CLUSTER_OFF_SNA" ;
VAL_TABLE_ MCU_enableCreepTorqueCH 1 "CREEP_MODE_ON" 0 "CREEP_MODE_OFF" ;
VAL_TABLE_ MCU_factoryMode 1 "FACTORY_MODE" 0 "NORMAL_MODE" ;
VAL_TABLE_ MCU_gatewaySleepReq 7 "SNA" 3 "LOW_POWER_SLEEP" 2 "SLEEP_NOW" 1 "OK_TO_START" 0 "DONT_SLEEP" ;
VAL_TABLE_ MCU_requestBusWake 3 "SNA" 2 "BUS_MAY_SLEEP_NOW" 1 "BUS_AWAKE_NOW" ;
VAL_TABLE_ MCU_setRcpFront 255 "SNA" ;
VAL_TABLE_ MCU_setRcpRear 255 "SNA" ;
VAL_TABLE_ MCU_trailerMode 1 "TRAILER_MODE_ON" 0 "TRAILER_MODE_OFF" ;
VAL_TABLE_ MCU_zeroSpeedConfirmed 3 "SNA" 2 "UNUSED" 1 "CONFIRMED" 0 "CANCELED" ;
VAL_TABLE_ PARK_version 255 "SNA" ;
VAL_TABLE_ PM_ebrCmdState 8 "EBR_CMD_INVALID" 6 "EBR_CMD_VALID" 0 "EBR_CMD_SNA" ;
VAL_TABLE_ PM_vdcCmdState 8 "VDC_CMD_INVALID" 6 "VDC_CMD_VALID" 0 "VDC_CMD_SNA" ;
VAL_TABLE_ P_VtSig_WakeupRsn_SCCM 255 "SNA" 73 "STW_SW" 72 "TX_LVR_P" 71 "STW_LVR" 0 "NETWORK" ;
VAL_TABLE_ SEAT_heaterRequestLevel 3 "HEATER_REQUEST_LEVEL3" 2 "HEATER_REQUEST_LEVEL2" 1 "HEATER_REQUEST_LEVEL1" 0 "HEATER_REQUEST_OFF" ;
VAL_TABLE_ SEAT_occupantClassification 7 "SEAT_OCCUPANT_CLASSIFICATON_SNA" 5 "SEAT_OCCUPANT_CLASSIFICATON_NOT_CONFIGURED" 4 "SEAT_OCCUPANT_CLASSIFICATON_INIT" 3 "SEAT_OCCUPANT_CLASSIFICATON_LARGE" 2 "SEAT_OCCUPANT_CLASSIFICATON_SMALL" 1 "SEAT_OCCUPANT_CLASSIFICATON_INHIBIT" 0 "SEAT_OCCUPANT_CLASSIFICATON_EMPTY" ;
VAL_TABLE_ SEAT_occupantClassificationQF 1 "SEAT_OCCUPANT_CLASSIFICATON_NOT_FAULTED" 0 "SEAT_OCCUPANT_CLASSIFICATON_FAULTED" ;
VAL_TABLE_ SEAT_ocsSensorStatus2Index 3 "OCS_SENSOR_STATUS2_INDEX_COUNT" 2 "OCS_SENSOR_STATUS2_INDEX_CALIB2" 1 "OCS_SENSOR_STATUS2_INDEX_CALIB1" 0 "OCS_SENSOR_STATUS2_INDEX_CALIB0" ;
VAL_TABLE_ SEAT_ocsSensorStatusIndex 6 "OCS_SENSOR_STATUS_INDEX_COUNT" 5 "OCS_SENSOR_STATUS_INDEX_DSS1" 4 "OCS_SENSOR_STATUS_INDEX_DSS0" 3 "OCS_SENSOR_STATUS_INDEX_TOS2" 2 "OCS_SENSOR_STATUS_INDEX_TOS1" 1 "OCS_SENSOR_STATUS_INDEX_TEMP" 0 "OCS_SENSOR_STATUS_INDEX_TOS0" ;
VAL_TABLE_ SEAT_seatState 5 "SEAT_STATE_UNDEFINED" 4 "SEAT_STATE_CALIBRATING" 3 "SEAT_STATE_RECALLING" 2 "SEAT_STATE_MOVING_DOWN" 1 "SEAT_STATE_MOVING_UP" 0 "SEAT_STATE_STOPPED" ;
VAL_TABLE_ SEAT_seatStatusIndex 5 "SEAT_STATUS_INDEX_POSITION" 4 "SEAT_STATUS_INDEX_LUMBAR" 3 "SEAT_STATUS_INDEX_TILT" 2 "SEAT_STATUS_INDEX_LIFT" 1 "SEAT_STATUS_INDEX_BACK" 0 "SEAT_STATUS_INDEX_TRACK" ;
VAL_TABLE_ SEAT_seatTrackPosition 7 "SEAT_TRACK_POSITION_SNA" 3 "SEAT_TRACK_POSITION_FAULTED" 2 "SEAT_TRACK_POSITION_NOT_CONFIGURED" 1 "SEAT_TRACK_POSITION_REARWARD" 0 "SEAT_TRACK_POSITION_FORWARD" ;
VAL_TABLE_ SNA_S11 -1024 "SNA" ;
VAL_TABLE_ SNA_S12 -2048 "SNA" ;
VAL_TABLE_ SNA_S13 -4096 "SNA" ;
VAL_TABLE_ SNA_S15 -16384 "SNA" ;
VAL_TABLE_ SNA_S16 -32768 "SNA" ;
VAL_TABLE_ SNA_S8 -128 "SNA" ;
VAL_TABLE_ SNA_S9 -256 "SNA" ;
VAL_TABLE_ SNA_U10 1023 "SNA" ;
VAL_TABLE_ SNA_U11 2047 "SNA" ;
VAL_TABLE_ SNA_U12 4095 "SNA" ;
VAL_TABLE_ SNA_U13 8191 "SNA" ;
VAL_TABLE_ SNA_U14 16383 "SNA" ;
VAL_TABLE_ SNA_U16 65535 "SNA" ;
VAL_TABLE_ SNA_U2 3 "SNA" ;
VAL_TABLE_ SNA_U3 7 "SNA" ;
VAL_TABLE_ SNA_U4 15 "SNA" ;
VAL_TABLE_ SNA_U5 31 "SNA" ;
VAL_TABLE_ SNA_U6 63 "SNA" ;
VAL_TABLE_ SNA_U7 127 "SNA" ;
VAL_TABLE_ SNA_U8 255 "SNA" ;
VAL_TABLE_ SNA_U9 511 "SNA" ;
VAL_TABLE_ SNA_u8 255 "SNA" ;
VAL_TABLE_ SOPT_States 7 "SOPT_SNA" 6 "SOPT_TEST_FAILED" 5 "SOPT_TEST_SKIPPED" 4 "SOPT_TEST_PASSED" 3 "SOPT_CURRENT_TEST" 2 "SOPT_ASC_TEST" 1 "SOPT_PSTG_BRING_UP" 0 "SOPT_INIT" ;
VAL_TABLE_ SPOT_dtcPresent 3 "SNA" 2 "UNUSED" 1 "TRUE" 0 "FALSE" ;
VAL_TABLE_ SPOT_frontLeftService 3 "SNA" 2 "TEMPORARY_FAILURE" 1 "PERMANENT_FAILURE" 0 "NO_FAILURE" ;
VAL_TABLE_ SPOT_frontRightService 3 "SNA" 2 "TEMPORARY_FAILURE" 1 "PERMANENT_FAILURE" 0 "NO_FAILURE" ;
VAL_TABLE_ SPOT_rearLeftService 3 "SNA" 2 "TEMPORARY_FAILURE" 1 "PERMANENT_FAILURE" 0 "NO_FAILURE" ;
VAL_TABLE_ SPOT_rearRightService 3 "SNA" 2 "TEMPORARY_FAILURE" 1 "PERMANENT_FAILURE" 0 "NO_FAILURE" ;
VAL_TABLE_ SPOT_serviceRequest 3 "SNA" 2 "UNUSED" 1 "FAILURE" 0 "NO_FAILURE" ;
VAL_TABLE_ SPOT_status 3 "SNA" 2 "UNUSED" 1 "ENABLE" 0 "DISABLE" ;
VAL_TABLE_ SPOT_warningLeft 7 "SNA" 2 "WARNING_LEVEL_2" 1 "WARNING_LEVEL_1" 0 "NO_WARNING" ;
VAL_TABLE_ SPOT_warningRight 7 "SNA" 2 "WARNING_LEVEL_2" 1 "WARNING_LEVEL_1" 0 "NO_WARNING" ;
VAL_TABLE_ STW_BUTTON_PRESSED 1 "PRESSED" 0 "NOT_PRESSED" ;
VAL_TABLE_ StW_AnglHP_Spd 16383 "SNA" ;
VAL_TABLE_ SuspensionCorner 3 "REAR_RIGHT" 2 "REAR_LEFT" 1 "FRONT_RIGHT" 0 "FRONT_LEFT" ;
VAL_TABLE_ SuspensionDirection 1 "COMPRESSION" 0 "REBOUND" ;
VAL_TABLE_ TAS2_AlertMatrixIndex 5 "TAS2_AlertMatrix5" 4 "TAS2_AlertMatrix4" 3 "TAS2_AlertMatrix3" 2 "TAS2_AlertMatrix2" 1 "TAS2_AlertMatrix1" 0 "TAS2_AlertMatrix0" ;
VAL_TABLE_ TAS2_FDUTorqueCorruptionScale 15 "SNA" ;
VAL_TABLE_ TAS2_alerts 317 "TAS2_a317_offsetsRotationalRates" 316 "TAS2_a316_offsetsAccels" 315 "TAS2_a315_pcbaHighTemp" 314 "TAS2_a314_dampingReduced" 313 "TAS2_a313_dampingCntrlDisabled" 312 "TAS2_a312_rotationalRatesMIA" 311 "TAS2_a311_accelsMIA" 310 "TAS2_a310_controlFrozenData" 309 "TAS2_a309_controlFrozen" 308 "TAS2_a308_endstopBoundaryRbnd" 307 "TAS2_a307_endstopBoundaryComp" 306 "TAS2_a306_endstopProtectFrozen" 305 "TAS2_a305_newEndstopPosition" 304 "TAS2_a304_massEstimateFrozenData" 303 "TAS2_a303_massEstimateFrozen" 301 "TAS2_a301_offsetEstimateData2" 300 "TAS2_a300_offsetEstimateData1" 299 "TAS2_a299_offsetEstimateTooLarge" 298 "TAS2_a298_vinNotLearned" 297 "TAS2_a297_vinMismatch" 296 "TAS2_a296_chassisTypeMismatch" 295 "TAS2_a295_targetHeightNotMet" 294 "TAS2_a294_rearAxleTooLow" 293 "TAS2_a293_frontAxleTooLow" 292 "TAS2_a292_rearAxleTooHigh" 291 "TAS2_a291_frontAxleTooHigh" 290 "TAS2_a290_twistSustainedAtSpeed" 289 "TAS2_a289_driveCycleStats4" 288 "TAS2_a288_driveCycleStats3" 287 "TAS2_a287_driveCycleStats2" 286 "TAS2_a286_driveCycleStats1" 230 "TAS2_a230_geofenceNotification" 229 "TAS2_a229_PWMfastDetectRR" 228 "TAS2_a228_PWMfastDetectRL" 227 "TAS2_a227_PWMfastDetectFR" 226 "TAS2_a226_PWMfastDetectFL" 225 "TAS2_a225_galleryPressureTooHigh" 224 "TAS2_a224_openAirline" 223 "TAS2_a223_blockedAirline" 222 "TAS2_a222_compressorPrefillFault" 221 "TAS2_a221_valveLeakDetected" 220 "TAS2_a220_exhaustGalleryFault" 218 "TAS2_a218_limpHomeMode40" 217 "TAS2_a217_limpHomeMode30" 216 "TAS2_a216_limpHomeMode20" 215 "TAS2_a215_limpHomeMode10" 214 "TAS2_a214_redWarningLamp" 213 "TAS2_a213_yellowWarningLamp" 211 "TAS2_a211_noRideHeightCalib" 210 "TAS2_a210_outOfRangeCalibration" 201 "TAS2_a201_lowHVBattery" 200 "TAS2_a200_jackModeActive" 176 "TAS2_a176_staticLeakDetectRR" 175 "TAS2_a175_staticLeakDetectRL" 174 "TAS2_a174_staticLeakDetectFR" 173 "TAS2_a173_staticLeakDetectFL" 172 "TAS2_a172_damperValveRbndRR" 171 "TAS2_a171_damperValveCompRR" 170 "TAS2_a170_damperValveRbndRL" 169 "TAS2_a169_damperValveCompRL" 168 "TAS2_a168_damperValveRbndFR" 167 "TAS2_a167_damperValveCompFR" 166 "TAS2_a166_damperValveRbndFL" 165 "TAS2_a165_damperValveCompFL" 163 "TAS2_a163_reservoirFillDisabled" 162 "TAS2_a162_compressorValveOpenGND" 161 "TAS2_a161_valveBlockOpenGND" 160 "TAS2_a160_otherCircuitCompressor" 159 "TAS2_a159_otherCircuitBoost" 158 "TAS2_a158_otherCircuitExhaust" 157 "TAS2_a157_otherCircuitReservoir" 156 "TAS2_a156_otherCircuitRR" 155 "TAS2_a155_otherCircuitRL" 154 "TAS2_a154_otherCircuitFR" 153 "TAS2_a153_otherCircuitFL" 152 "TAS2_a152_boardFaultCompressor" 151 "TAS2_a151_boardFaultBoost" 150 "TAS2_a150_boardFaultExhaust" 149 "TAS2_a149_boardFaultReservoir" 148 "TAS2_a148_boardFaultRR" 147 "TAS2_a147_boardFaultRL" 146 "TAS2_a146_boardFaultFR" 145 "TAS2_a145_boardFaultFL" 144 "TAS2_a144_shortCircuitCompressor" 143 "TAS2_a143_shortCircuitBoost" 142 "TAS2_a142_shortCircuitExhaust" 141 "TAS2_a141_shortCircuitReservoir" 140 "TAS2_a140_shortCircuitRR" 139 "TAS2_a139_shortCircuitRL" 138 "TAS2_a138_shortCircuitFR" 137 "TAS2_a137_shortCircuitFL" 136 "TAS2_a136_openCircuitCompressor" 135 "TAS2_a135_openCircuitBoost" 134 "TAS2_a134_openCircuitExhaust" 133 "TAS2_a133_openCircuitReservoir" 132 "TAS2_a132_openCircuitRR" 131 "TAS2_a131_openCircuitRL" 130 "TAS2_a130_openCircuitFR" 129 "TAS2_a129_openCircuitFL" 128 "TAS2_a128_maxDutyCompressor" 127 "TAS2_a127_maxDutyBoost" 126 "TAS2_a126_maxDutyExhaust" 125 "TAS2_a125_maxDutyReservoir" 124 "TAS2_a124_maxDutyRR" 123 "TAS2_a123_maxDutyRL" 122 "TAS2_a122_maxDutyFR" 121 "TAS2_a121_maxDutyFL" 107 "TAS2_a107_HighStackUsage" 106 "TAS2_a106_HighCPULoad" 103 "TAS2_a103_GTW_MIA" 102 "TAS2_a102_DI_MIA" 101 "TAS2_a101_ESP_MIA" 100 "TAS2_a100_SCCM_MIA" 99 "TAS2_a099_EFUSE_MIA" 98 "TAS2_a098_MCU_MIA" 97 "TAS2_a097_RCM_MIA" 96 "TAS2_a096_IMU_MIA" 95 "TAS2_a095_DIS_MIA" 94 "TAS2_a094_DAS_MIA" 93 "TAS2_a093_OTPError" 87 "TAS2_a087_overVoltage12VSwtchd" 86 "TAS2_a086_underVoltage12VSwtchd" 85 "TAS2_a085_overVoltage5VAnalog" 84 "TAS2_a084_underVoltage5VAnalog" 83 "TAS2_a083_shortCircuit5VAnalog" 82 "TAS2_a082_overVoltage5VHeight" 81 "TAS2_a081_underVoltage5VHeight" 80 "TAS2_a080_shortCircuit5VHeight" 78 "TAS2_a078_pressureSigVTooHigh" 77 "TAS2_a077_pressureSigVTooLow" 73 "TAS2_a073_underVoltage5VOnBoard" 72 "TAS2_a072_shortCircuit5VOnBoard" 71 "TAS2_a071_overVoltage12V" 70 "TAS2_a070_underVoltage12V" 62 "TAS2_a062_XCPWasConnected" 61 "TAS2_a061_XCPConnected" 46 "TAS2_a046_Task1000msError" 45 "TAS2_a045_Task100msError" 44 "TAS2_a044_Task10msError" 43 "TAS2_a043_Task1msError" 41 "TAS2_a041_PWMopenRR" 40 "TAS2_a040_PWMopenRL" 39 "TAS2_a039_PWMopenFR" 38 "TAS2_a038_PWMopenFL" 37 "TAS2_a037_PWMshortRR" 36 "TAS2_a036_PWMshortRL" 35 "TAS2_a035_PWMshortFR" 34 "TAS2_a034_PWMshortFL" 33 "TAS2_a033_PWMerrorRR" 32 "TAS2_a032_PWMerrorRL" 31 "TAS2_a031_PWMerrorFR" 30 "TAS2_a030_PWMerrorFL" 25 "TAS2_a025_CrashEvent" 22 "TAS2_a022_TaskInitError" 21 "TAS2_a021_TaskSchedulerError" 15 "TAS2_a015_NVMMAlert" 12 "TAS2_a012_CPUReset" 3 "TAS2_a003_SWAssertion" 2 "TAS2_a002_PowerLossReset" 1 "TAS2_a001_WatchdogReset" 0 "TAS2_ALERT_DO_NOT_USE_ZERO" ;
VAL_TABLE_ TAS2_current_FL_C 255 "SNA" ;
VAL_TABLE_ TAS2_current_FL_R 255 "SNA" ;
VAL_TABLE_ TAS2_current_FR_C 255 "SNA" ;
VAL_TABLE_ TAS2_current_FR_R 255 "SNA" ;
VAL_TABLE_ TAS2_current_RL_C 255 "SNA" ;
VAL_TABLE_ TAS2_current_RL_R 255 "SNA" ;
VAL_TABLE_ TAS2_current_RR_C 255 "SNA" ;
VAL_TABLE_ TAS2_current_RR_R 255 "SNA" ;
VAL_TABLE_ TAS2_roadCondition 255 "SNA" ;
VAL_TABLE_ TAS_NM_keepAwakeReason 15 "TAS_KEEPAWAKE_REASON_MULTIPLE" 1 "TAS_KEEPAWAKE_REASON_LEVELING_IN_PROGRESS" 0 "TAS_KEEPAWAKE_REASON_NONE_SNA" ;
VAL_TABLE_ TAS_adaptiveActivityFL_C 31 "SNA" ;
VAL_TABLE_ TAS_adaptiveActivityFL_R 31 "SNA" ;
VAL_TABLE_ TAS_adaptiveActivityFR_C 31 "SNA" ;
VAL_TABLE_ TAS_adaptiveActivityFR_R 31 "SNA" ;
VAL_TABLE_ TAS_adaptiveActivityRL_C 31 "SNA" ;
VAL_TABLE_ TAS_adaptiveActivityRL_R 31 "SNA" ;
VAL_TABLE_ TAS_adaptiveActivityRR_C 31 "SNA" ;
VAL_TABLE_ TAS_adaptiveActivityRR_R 31 "SNA" ;
VAL_TABLE_ TAS_adaptiveRideMode 3 "TAS_ADAPTIVE_RIDE_MODE_SNA" 2 "TAS_ADAPTIVE_RIDE_MODE_SPORT" 1 "TAS_ADAPTIVE_RIDE_MODE_AUTO" 0 "TAS_ADAPTIVE_RIDE_MODE_COMFORT" ;
VAL_TABLE_ TAS_alerts 295 "TAS_a295_targetHeightNotMet" 294 "TAS_a294_rearAxleTooLow" 293 "TAS_a293_frontAxleTooLow" 292 "TAS_a292_rearAxleTooHigh" 291 "TAS_a291_frontAxleTooHigh" 290 "TAS_a290_twistSustainedAtSpeed" 289 "TAS_a289_driveCycleStats4" 288 "TAS_a288_driveCycleStats3" 287 "TAS_a287_driveCycleStats2" 286 "TAS_a286_driveCycleStats1" 230 "TAS_a230_geofenceNotification" 229 "TAS_a229_PWMfastDetectRR" 228 "TAS_a228_PWMfastDetectRL" 227 "TAS_a227_PWMfastDetectFR" 226 "TAS_a226_PWMfastDetectFL" 225 "TAS_a225_galleryPressureTooHigh" 224 "TAS_a224_openAirline" 223 "TAS_a223_blockedAirline" 222 "TAS_a222_compressorPrefillFault" 221 "TAS_a221_valveLeakDetected" 220 "TAS_a220_exhaustGalleryFault" 218 "TAS_a218_limpHomeMode40" 217 "TAS_a217_limpHomeMode30" 216 "TAS_a216_limpHomeMode20" 215 "TAS_a215_limpHomeMode10" 214 "TAS_a214_redWarningLamp" 213 "TAS_a213_yellowWarningLamp" 211 "TAS_a211_noRideHeightCalib" 210 "TAS_a210_outOfRangeCalibration" 201 "TAS_a201_lowHVBattery" 200 "TAS_a200_jackModeActive" 176 "TAS_a176_staticLeakDetectRR" 175 "TAS_a175_staticLeakDetectRL" 174 "TAS_a174_staticLeakDetectFR" 173 "TAS_a173_staticLeakDetectFL" 163 "TAS_a163_reservoirFillDisabled" 162 "TAS_a162_compressorValveOpenGND" 161 "TAS_a161_valveBlockOpenGND" 160 "TAS_a160_otherCircuitCompressor" 159 "TAS_a159_otherCircuitBoost" 158 "TAS_a158_otherCircuitExhaust" 157 "TAS_a157_otherCircuitReservoir" 156 "TAS_a156_otherCircuitRR" 155 "TAS_a155_otherCircuitRL" 154 "TAS_a154_otherCircuitFR" 153 "TAS_a153_otherCircuitFL" 152 "TAS_a152_boardFaultCompressor" 151 "TAS_a151_boardFaultBoost" 150 "TAS_a150_boardFaultExhaust" 149 "TAS_a149_boardFaultReservoir" 148 "TAS_a148_boardFaultRR" 147 "TAS_a147_boardFaultRL" 146 "TAS_a146_boardFaultFR" 145 "TAS_a145_boardFaultFL" 144 "TAS_a144_shortCircuitCompressor" 143 "TAS_a143_shortCircuitBoost" 142 "TAS_a142_shortCircuitExhaust" 141 "TAS_a141_shortCircuitReservoir" 140 "TAS_a140_shortCircuitRR" 139 "TAS_a139_shortCircuitRL" 138 "TAS_a138_shortCircuitFR" 137 "TAS_a137_shortCircuitFL" 136 "TAS_a136_openCircuitCompressor" 135 "TAS_a135_openCircuitBoost" 134 "TAS_a134_openCircuitExhaust" 133 "TAS_a133_openCircuitReservoir" 132 "TAS_a132_openCircuitRR" 131 "TAS_a131_openCircuitRL" 130 "TAS_a130_openCircuitFR" 129 "TAS_a129_openCircuitFL" 128 "TAS_a128_maxDutyCompressor" 127 "TAS_a127_maxDutyBoost" 126 "TAS_a126_maxDutyExhaust" 125 "TAS_a125_maxDutyReservoir" 124 "TAS_a124_maxDutyRR" 123 "TAS_a123_maxDutyRL" 122 "TAS_a122_maxDutyFR" 121 "TAS_a121_maxDutyFL" 107 "TAS_a107_HighStackUsage" 106 "TAS_a106_HighCPULoad" 105 "TAS_a105_ECUDebugMode" 103 "TAS_a103_GTW_MIA" 102 "TAS_a102_DI_MIA" 101 "TAS_a101_ESP_MIA" 100 "TAS_a100_SCCM_MIA" 99 "TAS_a099_EFUSE_MIA" 98 "TAS_a098_MCU_MIA" 93 "TAS_a093_OTPError" 78 "TAS_a078_pressureSigVTooHigh" 77 "TAS_a077_pressureSigVTooLow" 76 "TAS_a076_overVoltage5VOffBoard" 75 "TAS_a075_underVoltage5VOffBoard" 74 "TAS_a074_shortCircuit5VOffBoard" 73 "TAS_a073_underVoltage5VOnBoard" 72 "TAS_a072_shortCircuit5VOnBoard" 71 "TAS_a071_overVoltage12V" 70 "TAS_a070_underVoltage12V" 62 "TAS_a062_XCPWasConnected" 61 "TAS_a061_XCPConnected" 46 "TAS_a046_Task1000msError" 45 "TAS_a045_Task100msError" 44 "TAS_a044_Task10msError" 43 "TAS_a043_Task1msError" 41 "TAS_a041_PWMopenRR" 40 "TAS_a040_PWMopenRL" 39 "TAS_a039_PWMopenFR" 38 "TAS_a038_PWMopenFL" 37 "TAS_a037_PWMshortRR" 36 "TAS_a036_PWMshortRL" 35 "TAS_a035_PWMshortFR" 34 "TAS_a034_PWMshortFL" 33 "TAS_a033_PWMerrorRR" 32 "TAS_a032_PWMerrorRL" 31 "TAS_a031_PWMerrorFR" 30 "TAS_a030_PWMerrorFL" 25 "TAS_a025_CrashEvent" 22 "TAS_a022_TaskInitError" 21 "TAS_a021_TaskSchedulerError" 15 "TAS_a015_NVMMAlert" 12 "TAS_a012_CPUReset" 3 "TAS_a003_SWAssertion" 2 "TAS_a002_PowerLossReset" 1 "TAS_a001_WatchdogReset" 0 "TAS_ALERT_DO_NOT_USE_ZERO" ;
VAL_TABLE_ TAS_axle 10 "TAS_axleRear" 5 "TAS_axleFront" ;
VAL_TABLE_ TAS_bodyAccelFL 255 "SNA" ;
VAL_TABLE_ TAS_bodyAccelFR 255 "SNA" ;
VAL_TABLE_ TAS_bodyAccelRL 255 "SNA" ;
VAL_TABLE_ TAS_bodyAccelRR 255 "SNA" ;
VAL_TABLE_ TAS_compTempModel 255 "SNA" ;
VAL_TABLE_ TAS_compTempSensor 255 "SNA" ;
VAL_TABLE_ TAS_componentPressureFL 255 "SNA" ;
VAL_TABLE_ TAS_componentPressureFR 255 "SNA" ;
VAL_TABLE_ TAS_componentPressureRL 255 "SNA" ;
VAL_TABLE_ TAS_componentPressureRR 255 "SNA" ;
VAL_TABLE_ TAS_damperValveFaults 10 "LOW_SIDE_STATUS_IMPLAUSIBLE" 9 "CURRENT_MISMATCH" 8 "CURRENT_IMPLAUSIBLE" 7 "HIGH_RESISTANCE" 6 "LOW_RESISTANCE" 5 "CROSS_CONNECTION_SHORT" 4 "OPEN_CIRCUIT" 3 "VOLTAGE_ON_CIRCUIT" 2 "SHORT_TO_GND" 1 "SHORT_TO_VBAT" 0 "NONE_UNUSED" ;
VAL_TABLE_ TAS_dampingState 1 "TAS_DAMPING_STATE_ACTIVE" 0 "TAS_DAMPING_STATE_STANDBY" ;
VAL_TABLE_ TAS_estimateType 1 "STEADY_STATE" 0 "DYNAMIC" ;
VAL_TABLE_ TAS_fastFilteredHeightFL 255 "SNA" ;
VAL_TABLE_ TAS_fastFilteredHeightFR 255 "SNA" ;
VAL_TABLE_ TAS_fastFilteredHeightRL 255 "SNA" ;
VAL_TABLE_ TAS_fastFilteredHeightRR 255 "SNA" ;
VAL_TABLE_ TAS_filterMode 7 "MODE_STOPPING" 6 "MODE_DRIVE" 5 "MODE_LOADING" 4 "MODE_READY" 3 "MODE_TEST" 2 "MODE_CALIBRATE" 1 "MODE_INIT" 0 "MODE_NONE" ;
VAL_TABLE_ TAS_launchModeState 4 "TAS_LAUNCH_MODE_STATE_RAISE_SUSPENSION" 3 "TAS_LAUNCH_MODE_STATE_READY" 2 "TAS_LAUNCH_MODE_STATE_LOWER_SUSPENSION" 1 "TAS_LAUNCH_MODE_STATE_IDLE" 0 "TAS_LAUNCH_MODE_STATE_BLOCKED" ;
VAL_TABLE_ TAS_level 4 "TAS_VERY_LOW" 3 "TAS_LOW" 2 "TAS_STANDARD" 1 "TAS_HIGH" 0 "TAS_VERY_HIGH" ;
VAL_TABLE_ TAS_levelingItem 7 "TAS_LEVELING_ITEM_ALL" 6 "TAS_LEVELING_ITEM_REAR_AXLE" 5 "TAS_LEVELING_ITEM_FRONT_AXLE" 4 "TAS_LEVELING_ITEM_RR" 3 "TAS_LEVELING_ITEM_RL" 2 "TAS_LEVELING_ITEM_FR" 1 "TAS_LEVELING_ITEM_FL" 0 "TAS_LEVELING_ITEM_NONE" ;
VAL_TABLE_ TAS_levelingState 12 "LEVELING_STATE_EMPTY_RESERVOIR" 11 "LEVELING_STATE_LOWER_SPRING" 10 "LEVELING_STATE_FILL_SPRING_RESERVOIR_FROM_COMPRESSOR" 9 "LEVELING_STATE_FILL_SPRING_FROM_RESERVOIR" 8 "LEVELING_STATE_FILL_SPRING_FROM_BOOST" 7 "LEVELING_STATE_FILL_SPRING_FROM_COMPRESSOR" 6 "LEVELING_STATE_FILL_RESERVOIR_FROM_COMPRESSOR" 5 "LEVELING_STATE_COMPRESSOR_PREFILL_GALLERY" 4 "LEVELING_STATE_COMPRESSOR_RAMPUP" 3 "LEVELING_STATE_EXHAUST_GALLERY" 2 "LEVELING_STATE_MANUAL_SPRING_CONTROL" 1 "LEVELING_STATE_READ_P_RESERVOIR" 0 "LEVELING_STATE_IDLE" ;
VAL_TABLE_ TAS_limpHomeMode 4 "LIMP_HOME_MODE_40" 3 "LIMP_HOME_MODE_30" 2 "LIMP_HOME_MODE_20" 1 "LIMP_HOME_MODE_10" 0 "LIMP_HOME_MODE_0" ;
VAL_TABLE_ TAS_modeFilteredHeightFL 255 "SNA" ;
VAL_TABLE_ TAS_modeFilteredHeightFR 255 "SNA" ;
VAL_TABLE_ TAS_modeFilteredHeightRL 255 "SNA" ;
VAL_TABLE_ TAS_modeFilteredHeightRR 255 "SNA" ;
VAL_TABLE_ TAS_pressureGallery 255 "SNA" ;
VAL_TABLE_ TAS_pressureReservoir 255 "SNA" ;
VAL_TABLE_ TAS_rawHeightFL 255 "SNA" ;
VAL_TABLE_ TAS_rawHeightFR 255 "SNA" ;
VAL_TABLE_ TAS_rawHeightRL 255 "SNA" ;
VAL_TABLE_ TAS_rawHeightRR 255 "SNA" ;
VAL_TABLE_ TAS_runMode 6 "RUN_MODE_LOW_POWER" 5 "RUN_MODE_NORMAL" 4 "RUN_MODE_DAN" 3 "RUN_MODE_ASSEMBLY" 2 "RUN_MODE_SERVICE" 1 "RUN_MODE_SYSTEM_CHECK" 0 "RUN_MODE_INIT" ;
VAL_TABLE_ TAS_specialAction 3 "TAS_ACTION_ACTIVE" 2 "TAS_ACTION_ARMED" 1 "TAS_ACTION_STANDBY" 0 "TAS_ACTION_DISABLED" ;
VAL_TABLE_ TAS_uiHeightFL 63 "SNA" ;
VAL_TABLE_ TAS_uiHeightFR 63 "SNA" ;
VAL_TABLE_ TAS_uiHeightRL 63 "SNA" ;
VAL_TABLE_ TAS_uiHeightRR 63 "SNA" ;
VAL_TABLE_ TAS_valveFaultTypes 7 "VALVE_OTHER_CIRCUIT" 6 "VALVE_SENSOR_ERROR" 5 "VALVE_HS_DRIVE_STUCK_OFF" 4 "VALVE_HS_DRIVE_STUCK_ON" 3 "VALVE_SHORT_CIRCUIT_12V" 2 "VALVE_SHORT_CIRCUIT_GND" 1 "VALVE_OPEN_CIRCUIT" 0 "VALVE_OVER_DUTY_CYCLE_LIMIT" ;
VAL_TABLE_ TPMS_status 3 "PASSED" 2 "STOPPED" 1 "ONGOING" 0 "FAILED" ;
VAL_TABLE_ UI_adaptiveRideRequest 3 "ADAPTIVE_RIDE_REQUEST_ADVANCED" 2 "ADAPTIVE_RIDE_REQUEST_SPORT" 1 "ADAPTIVE_RIDE_REQUEST_AUTO" 0 "ADAPTIVE_RIDE_REQUEST_COMFORT" ;
VAL_TABLE_ UI_autopilotPowerStateRequest 2 "AUTOPILOT_SUSPEND" 1 "AUTOPILOT_SENTRY" 0 "AUTOPILOT_NOMINAL" ;
VAL_TABLE_ UI_driverRecallIndex 5 "UI_DRIVER_RECALL_5" 4 "UI_DRIVER_RECALL_4" 3 "UI_DRIVER_RECALL_3" 2 "UI_DRIVER_RECALL_2" 1 "UI_DRIVER_RECALL_1" 0 "UI_DRIVER_RECALL_SNA" ;
VAL_TABLE_ UI_geofenceLevelingRequest 5 "GEOFENCE_LEVELING_REQUEST_SNA" 4 "GEOFENCE_LEVELING_REQUEST_VERY_HIGH_PERSIST" 3 "GEOFENCE_LEVELING_REQUEST_HIGH_PERSIST" 2 "GEOFENCE_LEVELING_REQUEST_VERY_HIGH_TEMPORARY" 1 "GEOFENCE_LEVELING_REQUEST_HIGH_TEMPORARY" 0 "GEOFENCE_LEVELING_REQUEST_NONE" ;
VAL_TABLE_ UI_jackModeToggleRequest 1 "JACK_MODE_TOGGLE_REQUEST_ACTIVE" 0 "JACK_MODE_TOGGLE_REQUEST_NONE" ;
VAL_TABLE_ UI_linkState 2 "LINK_STATE_WIFI" 1 "LINK_STATE_CELL" 0 "LINK_STATE_NONE" ;
VAL_TABLE_ UI_suspensionLevelRequest 7 "LEVEL_REQUEST_VERY_HIGH_LEVEL_PERSIST" 6 "LEVEL_REQUEST_HIGH_LEVEL_PERSIST" 5 "LEVEL_REQUEST_VERY_HIGH_LEVEL_TEMPORARY" 4 "LEVEL_REQUEST_HIGH_LEVEL_TEMPORARY" 3 "LEVEL_REQUEST_STANDARD_LEVEL" 2 "LEVEL_REQUEST_LOW_LEVEL" 1 "LEVEL_REQUEST_VERY_LOW_LEVEL" 0 "LEVEL_REQUEST_NONE" ;
VAL_TABLE_ UI_suspensionLoweringRequest 3 "SUSPENSION_LOWERING_REQUEST_SNA" 2 "SUSPENSION_LOWERING_REQUEST_AUTO" 1 "SUSPENSION_LOWERING_REQUEST_ALWAYS" 0 "SUSPENSION_LOWERING_REQUEST_NEVER" ;
VAL_TABLE_ VCSEAT1_absSeatTrackPosition 255 "ABS_SEAT_TRACK_POSITION_SNA" 254 "ABS_SEAT_TRACK_POSITION_NOT_CONFIGURED" ;
VAL_TABLE_ VCSEAT1_buckleStatus 3 "VCSEAT_BELT_BUCKLE_STATUS_SNA" 2 "VCSEAT_BELT_BUCKLE_STATUS_FAULTED" 1 "VCSEAT_BELT_BUCKLE_STATUS_LATCHED" 0 "VCSEAT_BELT_BUCKLE_STATUS_UNLATCHED" ;
VAL_TABLE_ VCSEAT1_nmKeepAwakeReason 15 "VCSEAT1_KEEPAWAKE_REASON_MULTIPLE" 14 "VCSEAT1_KEEPAWAKE_REASON_OTHER" 9 "VCSEAT1_KEEPAWAKE_REASON_INTRUSION_SENSOR_TRIGGERED" 8 "VCSEAT1_KEEPAWAKE_REASON_UDS_ACTIVE" 7 "VCSEAT1_KEEPAWAKE_REASON_SEAT" 6 "VCSEAT1_KEEPAWAKE_REASON_HANDLE_PULLED" 5 "VCSEAT1_KEEPAWAKE_REASON_EPB_SUMMON_ACTIVE" 4 "VCSEAT1_KEEPAWAKE_REASON_CLOSURE_LATCH" 3 "VCSEAT1_KEEPAWAKE_REASON_BRAKE_SWITCH" 2 "VCSEAT1_KEEPAWAKE_REASON_EPB_NOT_SECURE" 1 "VCSEAT1_KEEPAWAKE_REASON_EPB_STATE_NOT_SAVED" 0 "VCSEAT1_KEEPAWAKE_REASON_NONE_SNA" ;
VAL_TABLE_ VCSEAT1_nmWakeUpReason 15 "VCSEAT1_WAKEUP_REASON_UNKNOWN" 8 "VCSEAT1_WAKEUP_REASON_LIN_RX" 7 "VCSEAT1_WAKEUP_REASON_BRAKE_SWITCH" 6 "VCSEAT1_WAKEUP_REASON_EXTERIOR_HANDLE" 5 "VCSEAT1_WAKEUP_REASON_INTERIOR_HANDLE" 4 "VCSEAT1_WAKEUP_REASON_DOOR_LATCH" 3 "VCSEAT1_WAKEUP_REASON_RESET" 2 "VCSEAT1_WAKEUP_REASON_SWITCH_INPUT" 1 "VCSEAT1_WAKEUP_REASON_ECU_SPECIFIC" 0 "VCSEAT1_WAKEUP_REASON_NONE" ;
VAL_TABLE_ VCSEAT1_occupancyStatus 7 "VCSEAT_OCCUPANCY_SNA" 3 "VCSEAT_NOT_CONFIGURED" 2 "VCSEAT_OCCUPANCY_FAULTED" 1 "VCSEAT_OCCUPIED" 0 "VCSEAT_UNOCCUPIED" ;
VAL_TABLE_ VCSEAT1_seatStatus2Index 3 "VCSEAT1_SEAT_STATUS_2_INDEX_COUNT" 2 "VCSEAT1_OCCUPANCY" 1 "VCSEAT1_SEAT_VOLTAGES" 0 "VCSEAT1_SEAT_HEAT_FRONT" ;
VAL_TABLE_ VCSEAT1_statusIndex 1 "MUX1" 0 "MUX0" ;
VAL_TABLE_ VCSEAT1_switchStatusIndex 2 "VCSEAT1_SWITCH_STATUS_INDEX_INVALID" 1 "VCSEAT1_SWITCH_STATUS_INDEX_1" 0 "VCSEAT1_SWITCH_STATUS_INDEX_0" ;
VAL_TABLE_ VCSEATD_AlertMatrixIndex 7 "VCSEATD_AlertMatrix7" 6 "VCSEATD_AlertMatrix6" 4 "VCSEATD_AlertMatrix4" 3 "VCSEATD_AlertMatrix3" 1 "VCSEATD_AlertMatrix1" 0 "VCSEATD_AlertMatrix0" ;
VAL_TABLE_ VCSEATD_a415_occupancyTimeMins 65535 "SNA" ;
VAL_TABLE_ VCSEATD_alerts 445 "VCSEATD_a445_drv8703SpiFaultDBG" 444 "VCSEATD_a444_drv8703Fault" 415 "VCSEATD_a415_ocsRebaseEgressDBG" 414 "VCSEATD_a414_ocsMissedIngressDBG" 413 "VCSEATD_a413_ocsSBRFaulted" 412 "VCSEATD_a412_ocsRebaselineDBG" 411 "VCSEATD_a411_ocsDataTimeout" 410 "VCSEATD_a410_ocsSlowDrift" 409 "VCSEATD_a409_ocsHeatPadNoConnect" 408 "VCSEATD_a408_ocsSensorDroop" 407 "VCSEATD_a407_ocsManufactureInvld" 406 "VCSEATD_a406_ocsCalibMismatch" 405 "VCSEATD_a405_ocsSensorDisconnect" 404 "VCSEATD_a404_ocsBackDisconnect" 403 "VCSEATD_a403_ocsSensorHigh" 402 "VCSEATD_a402_ocsSensorLow" 401 "VCSEATD_a401_ocsDiagContext" 400 "VCSEATD_a400_ocsCushionMismatch" 399 "VCSEATD_a399_ocsTHMIA" 398 "VCSEATD_a398_ocsTOSMIA" 397 "VCSEATD_a397_ocsTHInvalCalib" 396 "VCSEATD_a396_ocsSpareInvalCalib" 394 "VCSEATD_a394_ocsCushionInvlCalib" 393 "VCSEATD_a393_ocsTHNoCalib" 392 "VCSEATD_a392_ocsSpareNoCalib" 390 "VCSEATD_a390_ocsCushionNoCalib" 389 "VCSEATD_a389_ocsTHInvalid" 388 "VCSEATD_a388_ocsSpareShort" 387 "VCSEATD_a387_ocsSpareLow" 386 "VCSEATD_a386_ocsSpareHigh" 382 "VCSEATD_a382_ocsCushionShort" 381 "VCSEATD_a381_ocsCushionLow" 380 "VCSEATD_a380_ocsCushionHigh" 291 "VCSEATD_a291_buckleFaultedFront" 290 "VCSEATD_a290_occupancyFaultFront" 270 "VCSEATD_a270_seatLiftHCEncStlDbg" 269 "VCSEATD_a269_seatTiltHCEncStlDbg" 268 "VCSEATD_a268_seatBackHCEncStlDbg" 267 "VCSEATD_a267_seatTrackHCEncStl" 266 "VCSEATD_a266_seatLiftStallDebug" 265 "VCSEATD_a265_seatTiltStallDebug" 264 "VCSEATD_a264_seatBackStallDebug" 263 "VCSEATD_a263_seatTrackStallDebug" 254 "VCSEATD_a254_seatUncalLift" 253 "VCSEATD_a253_seatUncalTilt" 252 "VCSEATD_a252_seatUncalBack" 251 "VCSEATD_a251_seatUncalTrack" 242 "VCSEATD_a242_seatHeatTmpFront" 241 "VCSEATD_a241_seatHeatMIAFront" 240 "VCSEATD_a240_seatHeatShortFront" 239 "VCSEATD_a239_seatHeatIFront" 238 "VCSEATD_a238_lumbarValveMIA" 237 "VCSEATD_a237_lumbarOverPresB" 236 "VCSEATD_a236_lumbarOverPresA" 235 "VCSEATD_a235_seatCurrUnderLift" 234 "VCSEATD_a234_seatCurrUnderTilt" 233 "VCSEATD_a233_seatCurrUnderBack" 232 "VCSEATD_a232_seatCurrUnderTrack" 231 "VCSEATD_a231_seatEncOverLift" 230 "VCSEATD_a230_seatEncOverTilt" 229 "VCSEATD_a229_seatEncOverBack" 228 "VCSEATD_a228_seatEncOverTrack" 227 "VCSEATD_a227_seatEncStallLift" 226 "VCSEATD_a226_seatEncStallTilt" 225 "VCSEATD_a225_seatEncStallBack" 224 "VCSEATD_a224_seatEncStallTrack" 223 "VCSEATD_a223_seatCurrStallLift" 222 "VCSEATD_a222_seatCurrStallTilt" 221 "VCSEATD_a221_seatCurrStallBack" 220 "VCSEATD_a220_seatCurrStallTrack" 219 "VCSEATD_a219_motorCurrentDropout" 218 "VCSEATD_a218_motorDriverFault" 201 "VCSEATD_a201_motorDutyEncDisabl" 200 "VCSEATD_a200_motorPhantomEncoder" 64 "VCSEATD_a064_busSleepReqTimeout" 63 "VCSEATD_a063_SwitchFault" 62 "VCSEATD_a062_XCPWasConnected" 61 "VCSEATD_a061_XCPConnected" 60 "VCSEATD_a060_engineeringBuild" 59 "VCSEATD_a059_inputResistanceHigh" 58 "VCSEATD_a058_inputRHighSyncDebug" 46 "VCSEATD_a046_Task1000msError" 45 "VCSEATD_a045_Task100msError" 44 "VCSEATD_a044_Task10msError" 43 "VCSEATD_a043_Task1msError" 42 "VCSEATD_a042_HighStackUsage" 41 "VCSEATD_a041_HighCPULoad" 31 "VCSEATD_a031_UDSActive" 30 "VCSEATD_a030_ECULogUploadRequest" 22 "VCSEATD_a022_TaskInitError" 21 "VCSEATD_a021_TaskSchedulerError" 15 "VCSEATD_a015_NVMMAlert" 13 "VCSEATD_a013_AlertManagerFault" 12 "VCSEATD_a012_CPUReset" 10 "VCSEATD_a010_ExtSupplyVoltError" 5 "VCSEATD_a005_CANTXError" 3 "VCSEATD_a003_SWAssertion" 2 "VCSEATD_a002_PowerLossReset" 1 "VCSEATD_a001_WatchdogReset" 0 "VCSEATD_ALERT_DO_NOT_USE_ZERO" ;
VAL_TABLE_ VCSEATP_AlertMatrixIndex 7 "VCSEATP_AlertMatrix7" 6 "VCSEATP_AlertMatrix6" 4 "VCSEATP_AlertMatrix4" 3 "VCSEATP_AlertMatrix3" 1 "VCSEATP_AlertMatrix1" 0 "VCSEATP_AlertMatrix0" ;
VAL_TABLE_ VCSEATP_a415_occupancyTimeMins 65535 "SNA" ;
VAL_TABLE_ VCSEATP_alerts 445 "VCSEATP_a445_drv8703SpiFaultDBG" 444 "VCSEATP_a444_drv8703Fault" 415 "VCSEATP_a415_ocsRebaseEgressDBG" 414 "VCSEATP_a414_ocsMissedIngressDBG" 413 "VCSEATP_a413_ocsSBRFaulted" 412 "VCSEATP_a412_ocsRebaselineDBG" 411 "VCSEATP_a411_ocsDataTimeout" 410 "VCSEATP_a410_ocsSlowDrift" 409 "VCSEATP_a409_ocsHeatPadNoConnect" 408 "VCSEATP_a408_ocsSensorDroop" 407 "VCSEATP_a407_ocsManufactureInvld" 406 "VCSEATP_a406_ocsCalibMismatch" 405 "VCSEATP_a405_ocsSensorDisconnect" 404 "VCSEATP_a404_ocsBackDisconnect" 403 "VCSEATP_a403_ocsSensorHigh" 402 "VCSEATP_a402_ocsSensorLow" 401 "VCSEATP_a401_ocsDiagContext" 400 "VCSEATP_a400_ocsCushionMismatch" 399 "VCSEATP_a399_ocsTHMIA" 398 "VCSEATP_a398_ocsTOSMIA" 397 "VCSEATP_a397_ocsTHInvalCalib" 396 "VCSEATP_a396_ocsSpareInvalCalib" 394 "VCSEATP_a394_ocsCushionInvlCalib" 393 "VCSEATP_a393_ocsTHNoCalib" 392 "VCSEATP_a392_ocsSpareNoCalib" 390 "VCSEATP_a390_ocsCushionNoCalib" 389 "VCSEATP_a389_ocsTHInvalid" 388 "VCSEATP_a388_ocsSpareShort" 387 "VCSEATP_a387_ocsSpareLow" 386 "VCSEATP_a386_ocsSpareHigh" 382 "VCSEATP_a382_ocsCushionShort" 381 "VCSEATP_a381_ocsCushionLow" 380 "VCSEATP_a380_ocsCushionHigh" 291 "VCSEATP_a291_buckleFaultedFront" 290 "VCSEATP_a290_occupancyFaultFront" 270 "VCSEATP_a270_seatLiftHCEncStlDbg" 269 "VCSEATP_a269_seatTiltHCEncStlDbg" 268 "VCSEATP_a268_seatBackHCEncStlDbg" 267 "VCSEATP_a267_seatTrackHCEncStl" 266 "VCSEATP_a266_seatLiftStallDebug" 265 "VCSEATP_a265_seatTiltStallDebug" 264 "VCSEATP_a264_seatBackStallDebug" 263 "VCSEATP_a263_seatTrackStallDebug" 254 "VCSEATP_a254_seatUncalLift" 253 "VCSEATP_a253_seatUncalTilt" 252 "VCSEATP_a252_seatUncalBack" 251 "VCSEATP_a251_seatUncalTrack" 242 "VCSEATP_a242_seatHeatTmpFront" 241 "VCSEATP_a241_seatHeatMIAFront" 240 "VCSEATP_a240_seatHeatShortFront" 239 "VCSEATP_a239_seatHeatIFront" 238 "VCSEATP_a238_lumbarValveMIA" 237 "VCSEATP_a237_lumbarOverPresB" 236 "VCSEATP_a236_lumbarOverPresA" 235 "VCSEATP_a235_seatCurrUnderLift" 234 "VCSEATP_a234_seatCurrUnderTilt" 233 "VCSEATP_a233_seatCurrUnderBack" 232 "VCSEATP_a232_seatCurrUnderTrack" 231 "VCSEATP_a231_seatEncOverLift" 230 "VCSEATP_a230_seatEncOverTilt" 229 "VCSEATP_a229_seatEncOverBack" 228 "VCSEATP_a228_seatEncOverTrack" 227 "VCSEATP_a227_seatEncStallLift" 226 "VCSEATP_a226_seatEncStallTilt" 225 "VCSEATP_a225_seatEncStallBack" 224 "VCSEATP_a224_seatEncStallTrack" 223 "VCSEATP_a223_seatCurrStallLift" 222 "VCSEATP_a222_seatCurrStallTilt" 221 "VCSEATP_a221_seatCurrStallBack" 220 "VCSEATP_a220_seatCurrStallTrack" 219 "VCSEATP_a219_motorCurrentDropout" 218 "VCSEATP_a218_motorDriverFault" 201 "VCSEATP_a201_motorDutyEncDisabl" 200 "VCSEATP_a200_motorPhantomEncoder" 64 "VCSEATP_a064_busSleepReqTimeout" 63 "VCSEATP_a063_SwitchFault" 62 "VCSEATP_a062_XCPWasConnected" 61 "VCSEATP_a061_XCPConnected" 60 "VCSEATP_a060_engineeringBuild" 59 "VCSEATP_a059_inputResistanceHigh" 58 "VCSEATP_a058_inputRHighSyncDebug" 46 "VCSEATP_a046_Task1000msError" 45 "VCSEATP_a045_Task100msError" 44 "VCSEATP_a044_Task10msError" 43 "VCSEATP_a043_Task1msError" 42 "VCSEATP_a042_HighStackUsage" 41 "VCSEATP_a041_HighCPULoad" 31 "VCSEATP_a031_UDSActive" 30 "VCSEATP_a030_ECULogUploadRequest" 22 "VCSEATP_a022_TaskInitError" 21 "VCSEATP_a021_TaskSchedulerError" 15 "VCSEATP_a015_NVMMAlert" 13 "VCSEATP_a013_AlertManagerFault" 12 "VCSEATP_a012_CPUReset" 10 "VCSEATP_a010_ExtSupplyVoltError" 5 "VCSEATP_a005_CANTXError" 3 "VCSEATP_a003_SWAssertion" 2 "VCSEATP_a002_PowerLossReset" 1 "VCSEATP_a001_WatchdogReset" 0 "VCSEATP_ALERT_DO_NOT_USE_ZERO" ;
VAL_TABLE_ WheelPulse 255 "Fail_Present" ;
VAL_TABLE_ alertState 1 "ALERT_SET" 0 "ALERT_CLEARED" ;
VAL_TABLE_ bcInfoIndex 255 "BC_INFO_END" 33 "BC_INFO_SUBCOMPONENT6" 32 "BC_INFO_SUBCOMPONENT5" 31 "BC_INFO_SUBCOMPONENT4" 24 "BC_INFO_SUBCOMPONENT3" 23 "BC_INFO_SUBCOMPONENT2" 20 "BC_INFO_UDS_PROTOCOL_BOOTCRC" 19 "BC_INFO_VERSION_DEPRECATED" 18 "BC_INFO_BOOTLOADER_GITHASH" 17 "BC_INFO_APP_GITHASH" 16 "BC_INFO_SUBCOMPONENT1" 15 "BC_INFO_BOOTLOADER_CRC" 14 "BC_INFO_BOOTLOADER_SVN" 13 "BC_INFO_APP_CRC" 11 "BC_INFO_PCBAID_ASSYID_USAGEID" 10 "BC_INFO_BUILD_HWID_COMPONENTID" 9 "BC_INFO_DEPRECATED_9" 8 "BC_INFO_DEPRECATED_8" 7 "BC_INFO_DEPRECATED_7" 6 "BC_INFO_DEPRECATED_6" 5 "BC_INFO_DEPRECATED_5" 4 "BC_INFO_DEPRECATED_4" 3 "BC_INFO_DEPRECATED_3" 2 "BC_INFO_DEPRECATED_2" 1 "BC_INFO_DEPRECATED_1" 0 "BC_INFO_DEPRECATED_0" ;
VAL_TABLE_ brakeLamp 1 "LAMP_ON" 0 "LAMP_OFF" ;
VAL_TABLE_ buildType 4 "INFO_MFG_BUILD" 3 "INFO_TRACEABLE_CI_BUILD" 2 "INFO_LOCAL_BUILD" 1 "INFO_PLATFORM_BUILD" 0 "INFO_UNKNOWN_BUILD" ;
VAL_TABLE_ crashDetectedType 3 "CRASH_DETECTED_TYPE_SEVERE" 2 "CRASH_DETECTED_TYPE_MINOR_2" 1 "CRASH_DETECTED_TYPE_MINOR_1" 0 "CRASH_DETECTED_TYPE_NONE" ;
VAL_TABLE_ crashState 3 "CRASH_STATE_SEVERE" 2 "CRASH_STATE_MINOR_2" 1 "CRASH_STATE_MINOR_1" 0 "CRASH_STATE_IDLE" ;
VAL_TABLE_ debugStatesType 1 "TAS_DEBUG_STATES_LAUNCH_MODE" 0 "TAS_DEBUG_STATES_NONE" ;
VAL_TABLE_ firmwareType 2 "BOOTLOADER_UPDATER" 1 "BOOTLOADER" 0 "APPLICATION" ;
VAL_TABLE_ hazardLightRequest 8 "HAZARD_REQUEST_UDS" 7 "HAZARD_REQUEST_DAS" 6 "HAZARD_REQUEST_CAR_ALARM" 5 "HAZARD_REQUEST_CRASH" 4 "HAZARD_REQUEST_MISLOCK" 3 "HAZARD_REQUEST_UNLOCK" 2 "HAZARD_REQUEST_LOCK" 1 "HAZARD_REQUEST_BUTTON" 0 "HAZARD_REQUEST_NONE" ;
VAL_TABLE_ infoAssemblyID 255 "ASSEMBLY_SNA" 1 "ASSEMBLY1" ;
VAL_TABLE_ infoIndex 255 "INFO_END" 20 "INFO_UDS_PROTOCOL_BOOTCRC" 19 "INFO_VERSION_DEPRECATED" 18 "INFO_BOOTLOADER_GITHASH" 17 "INFO_APP_GITHASH" 16 "INFO_SUBCOMPONENT" 15 "INFO_BOOTLOADER_CRC" 14 "INFO_BOOTLOADER_SVN" 13 "INFO_APP_CRC" 11 "INFO_PCBAID_ASSYID_USAGEID" 10 "INFO_BUILD_HWID_COMPONENTID" 9 "INFO_DEPRECATED_9" 8 "INFO_DEPRECATED_8" 7 "INFO_DEPRECATED_7" 6 "INFO_DEPRECATED_6" 5 "INFO_DEPRECATED_5" 4 "INFO_DEPRECATED_4" 3 "INFO_DEPRECATED_3" 2 "INFO_DEPRECATED_2" 1 "INFO_DEPRECATED_1" 0 "INFO_DEPRECATED_0" ;
VAL_TABLE_ infoVersion 255 "VERSION_SNA" 254 "VERSION_LOCAL_BUILD" ;
VAL_TABLE_ inputPowerSyncFaultReason 1 "INPUT_POWER_SYNC_FAULT_REASON_DELTA_THRESHOLD" 0 "INPUT_POWER_SYNC_FAULT_REASON_THRESHOLD" ;
VAL_TABLE_ levelPWMFaultTypes 6 "PWM_OPEN_CIRCUIT" 5 "PWM_SHORT_CIRCUIT" 4 "PWM_OVER_MAX_DELTA_DUTY" 3 "PWM_UNDER_MIN_PERIOD" 2 "PWM_OVER_MAX_PERIOD" 1 "PWM_UNDER_MIN_DUTY" 0 "PWM_OVER_MAX_DUTY" ;
VAL_TABLE_ lightStatus 3 "LIGHT_SNA" 2 "LIGHT_FAULT" 1 "LIGHT_ON" 0 "LIGHT_OFF" ;
VAL_TABLE_ lightingRequest 1 "LIGHT_REQUEST" 0 "LIGHT_NO_REQUEST" ;
VAL_TABLE_ memorySeatsInstalled 3 "TESLA_GEN1" 2 "BITRON_GEN2" 1 "BITRON_GEN1" 0 "SEAT_NONE" ;
VAL_TABLE_ recallStatus 3 "RECALL_INTERRUPTED" 2 "RECALL_COMPLETE" 1 "RECALL_IN_PROGRESS" 0 "RECALL_SNA" ;
VAL_TABLE_ switchStatus 3 "SWITCH_SNA" 2 "SWITCH_FAULT" 1 "SWITCH_ON" 0 "SWITCH_OFF" ;
VAL_TABLE_ timeSinceIgnitionOff 65535 "SNA" 65534 "INIT" ;
VAL_TABLE_ vehiclePowerState 3 "VEHICLE_POWER_STATE_DRIVE" 2 "VEHICLE_POWER_STATE_ACCESSORY" 1 "VEHICLE_POWER_STATE_CONDITIONING" 0 "VEHICLE_POWER_STATE_OFF" ;

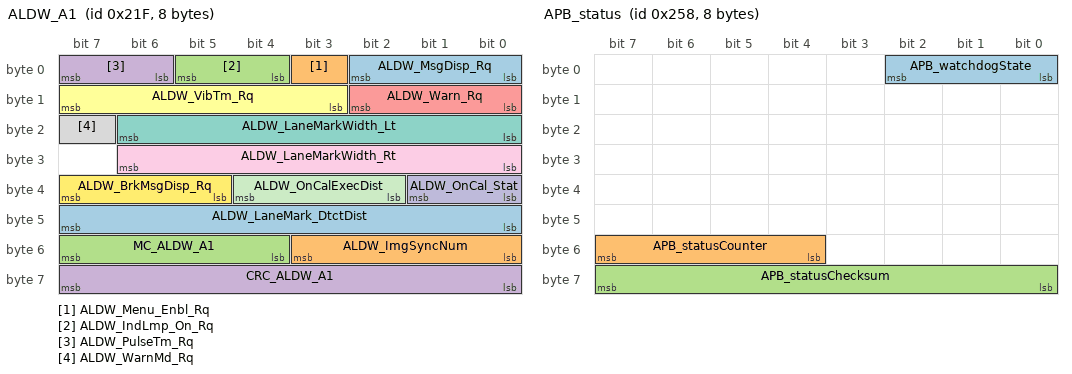
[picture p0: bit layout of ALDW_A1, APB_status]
BO_ 543 ALDW_A1: 8 GTW
 SG_ ALDW_MsgDisp_Rq : 0|3@1+ (1,0) [0|0] "" Vector__XXX
 SG_ ALDW_Menu_Enbl_Rq : 3|1@1+ (1,0) [0|0] "" Vector__XXX
 SG_ ALDW_IndLmp_On_Rq : 4|2@1+ (1,0) [0|0] "" Vector__XXX
 SG_ ALDW_PulseTm_Rq : 6|2@1+ (1,0) [0|0] "" Vector__XXX
 SG_ ALDW_Warn_Rq : 8|3@1+ (1,0) [0|0] "" Vector__XXX
 SG_ ALDW_VibTm_Rq : 11|5@1+ (4,12) [16|132] "ms" SCCM
 SG_ ALDW_LaneMarkWidth_Lt : 16|7@1+ (0.01,0) [0|1.26] "m" Vector__XXX
 SG_ ALDW_WarnMd_Rq : 23|1@1+ (1,0) [0|0] "" Vector__XXX
 SG_ ALDW_LaneMarkWidth_Rt : 24|7@1+ (0.01,0) [0|1.26] "m" Vector__XXX
 SG_ ALDW_OnCal_Stat : 32|2@1+ (1,0) [0|0] "" Vector__XXX
 SG_ ALDW_OnCalExecDist : 34|3@1+ (1,0) [0|0] "" GTW
 SG_ ALDW_BrkMsgDisp_Rq : 37|3@1+ (1,0) [0|0] "" Vector__XXX
 SG_ ALDW_LaneMark_DtctDist : 40|8@1+ (1,0) [0|254] "m" Vector__XXX
 SG_ ALDW_ImgSyncNum : 48|4@1+ (1,0) [0|14] "" Vector__XXX
 SG_ MC_ALDW_A1 : 52|4@1+ (1,0) [0|15] "" Vector__XXX
 SG_ CRC_ALDW_A1 : 56|8@1+ (1,0) [0|0] "" Vector__XXX

BO_ 1352 APB_info: 8 APB
 SG_ APB_infoIndex M : 0|8@1+ (1,0) [0|0] "" GTW,APS
 SG_ APB_buildType m0 : 8|8@1+ (1,0) [0|0] "" GTW,APS
 SG_ APB_infoApbFwGitHashBytes m1 : 8|56@1+ (1,0) [0|0] "" GTW,APS
 SG_ APB_infoApbApGitHashBytes m2 : 8|56@1+ (1,0) [0|0] "" GTW,APS

BO_ 600 APB_status: 8 APB
 SG_ APB_watchdogState : 0|3@1+ (1,0) [0|7] "" GTW,APS,APP
 SG_ APB_statusCounter : 52|4@1+ (1,0) [0|15] "" APS,APP
 SG_ APB_statusChecksum : 56|8@1+ (1,0) [0|255] "" APS,APP

BO_ 1572 APPL_SG_SCCM: 8 GTW
 SG_ APPL_SG_SCCM : 7|64@0+ (1,0) [0|0] "" SCCM

BO_ 1513 APP_alertLog: 8 APP
 SG_ APP_alertID M : 0|14@1+ (1,0) [0|0] "" GTW
 SG_ APP_alertType : 15|1@1+ (1,0) [0|0] "" GTW
 SG_ APP_alertDataW0 m0 : 16|16@1+ (1,0) [0|0] "" GTW
 SG_ APP_alertDataW1 m0 : 32|16@1+ (1,0) [0|0] "" GTW
 SG_ APP_alertDataW2 m0 : 48|16@1+ (1,0) [0|0] "" GTW
 SG_ APP_sw004_radIssue m4 : 16|1@1+ (1,0) [0|0] "" GTW
 SG_ APP_sw004_radHWFailure m4 : 17|1@1+ (1,0) [0|0] "" GTW
 SG_ APP_sw004_radSensorBlind m4 : 18|1@1+ (1,0) [0|0] "" GTW
 SG_ APP_sw004_radSGUFailure m4 : 19|1@1+ (1,0) [0|0] "" GTW
 SG_ APP_sw004_radMia m4 : 20|1@1+ (1,0) [0|0] "" GTW
 SG_ APP_sw004_radDynamicsError m4 : 21|1@1+ (1,0) [0|0] "" GTW
 SG_ APP_sw004_espMIA m4 : 23|1@1+ (1,0) [0|0] "" GTW
 SG_ APP_sw004_accState m4 : 24|4@1+ (1,0) [0|0] "" GTW
 SG_ APP_sw004_appMobileyeStatus m4 : 28|5@1+ (1,0) [0|0] "" GTW
 SG_ APP_sw004_diCruiseStateFault m4 : 33|1@1+ (1,0) [0|0] "" GTW
 SG_ APP_sw004_diMIA m4 : 34|1@1+ (1,0) [0|0] "" GTW
 SG_ APP_sw004_accelPedalInvalid m4 : 35|1@1+ (1,0) [0|0] "" GTW
 SG_ APP_sw004_stwAngleInvalid m4 : 36|1@1+ (1,0) [0|0] "" GTW
 SG_ APP_sw004_accelerationInvalid m4 : 37|1@1+ (1,0) [0|0] "" GTW
 SG_ APP_sw004_diSpeedInvalid m4 : 38|1@1+ (1,0) [0|0] "" GTW
 SG_ APP_sw004_APPFeaturesDisabled m4 : 40|1@1+ (1,0) [0|0] "" GTW
 SG_ APP_sw004_appMobileyeNotInVision m4 : 41|1@1+ (1,0) [0|0] "" GTW
 SG_ APP_sw004_CamCommonMIA m4 : 42|1@1+ (1,0) [0|0] "" GTW
 SG_ APP_sw004_CamObjectsMIA m4 : 43|1@1+ (1,0) [0|0] "" GTW
 SG_ APP_sw004_CamWatchdog m4 : 44|1@1+ (1,0) [0|0] "" GTW
 SG_ APP_sw004_RadarLowVisibility m4 : 45|1@1+ (1,0) [0|0] "" GTW
 SG_ APP_sw004_RadarMisalignment m4 : 46|1@1+ (1,0) [0|0] "" GTW
 SG_ APP_sw004_OutOfFocusImage m4 : 47|1@1+ (1,0) [0|0] "" GTW
 SG_ APP_sw004_ImpairedVD m4 : 48|1@1+ (1,0) [0|0] "" GTW
 SG_ APP_sw004_SunRay m4 : 49|1@1+ (1,0) [0|0] "" GTW
 SG_ APP_sw004_Splashes m4 : 50|1@1+ (1,0) [0|0] "" GTW
 SG_ APP_sw004_BlurredImage m4 : 51|1@1+ (1,0) [0|0] "" GTW
 SG_ APP_sw004_LowSun m4 : 52|1@1+ (1,0) [0|0] "" GTW
 SG_ APP_sw004_SmearedSpots m4 : 53|1@1+ (1,0) [0|0] "" GTW
 SG_ APP_sw004_PartialBlockage m4 : 54|1@1+ (1,0) [0|0] "" GTW
 SG_ APP_sw004_AutofixOutOfCalib m4 : 55|1@1+ (1,0) [0|0] "" GTW
 SG_ APP_sw004_AutofixOutOfCalibHorzn m4 : 56|1@1+ (1,0) [0|0] "" GTW
 SG_ APP_sw004_AutofixOutOfCalibYaw m4 : 57|1@1+ (1,0) [0|0] "" GTW
 SG_ APP_sw004_FullBlockage m4 : 58|1@1+ (1,0) [0|0] "" GTW
 SG_ APP_sw004_SmearedHalos m4 : 59|1@1+ (1,0) [0|0] "" GTW
 SG_ APP_sw004_FoggyLights m4 : 60|1@1+ (1,0) [0|0] "" GTW
 SG_ APP_sw004_SelfGlare m4 : 61|1@1+ (1,0) [0|0] "" GTW
 SG_ APP_sw004_visionNotRunning m4 : 62|1@1+ (1,0) [0|1] "" GTW
 SG_ APP_sw005_AutofixOutOfCalib m5 : 16|1@1+ (1,0) [0|0] "" GTW
 SG_ APP_sw005_AutofixOutOfCalibYaw m5 : 17|1@1+ (1,0) [0|0] "" GTW
 SG_ APP_sw005_RadarMisalignment m5 : 18|1@1+ (1,0) [0|0] "" GTW
 SG_ APP_sw005_partialBlockage m5 : 20|1@1+ (1,0) [0|0] "" GTW
 SG_ APP_sw005_fullBlockage m5 : 21|1@1+ (1,0) [0|0] "" GTW
 SG_ APP_sw005_camObjHeader m5 : 22|1@1+ (1,0) [0|0] "" GTW
 SG_ APP_sw005_camCommonMsg m5 : 23|1@1+ (1,0) [0|0] "" GTW
 SG_ APP_sw005_camFcwPcwMsg m5 : 24|1@1+ (1,0) [0|0] "" GTW
 SG_ APP_sw005_radHWFailure m5 : 25|1@1+ (1,0) [0|0] "" GTW
 SG_ APP_sw005_radSensorBlind m5 : 26|1@1+ (1,0) [0|0] "" GTW
 SG_ APP_sw005_radSGUFailure m5 : 27|1@1+ (1,0) [0|0] "" GTW
 SG_ APP_sw005_radMia m5 : 28|1@1+ (1,0) [0|0] "" GTW
 SG_ APP_sw005_brakePedal m5 : 29|1@1+ (1,0) [0|0] "" GTW
 SG_ APP_sw005_steeringAngle m5 : 30|1@1+ (1,0) [0|0] "" GTW
 SG_ APP_sw005_steeringAngleRate m5 : 31|1@1+ (1,0) [0|0] "" GTW
 SG_ APP_sw005_speed m5 : 32|1@1+ (1,0) [0|0] "" GTW
 SG_ APP_sw005_gear m5 : 33|1@1+ (1,0) [0|0] "" GTW
 SG_ APP_sw005_stabilityControl m5 : 34|1@1+ (1,0) [0|0] "" GTW
 SG_ APP_sw005_blinkers m5 : 35|1@1+ (1,0) [0|0] "" GTW
 SG_ APP_sw005_yaw m5 : 36|1@1+ (1,0) [0|0] "" GTW
 SG_ APP_sw005_longAccel m5 : 37|1@1+ (1,0) [0|0] "" GTW
 SG_ APP_sw005_accelPedal m5 : 38|1@1+ (1,0) [0|0] "" GTW
 SG_ APP_sw005_fcmSensitivity m5 : 41|1@1+ (1,0) [0|0] "" GTW
 SG_ APP_sw005_dasDisabled m5 : 42|1@1+ (1,0) [0|0] "" GTW
 SG_ APP_sw005_speedDerivative m5 : 43|1@1+ (1,0) [0|0] "" GTW
 SG_ APP_sw005_camWatchdog m5 : 44|1@1+ (1,0) [0|0] "" GTW
 SG_ APP_sw005_AutofixOutOfCalibHorzn m5 : 45|1@1+ (1,0) [0|0] "" GTW
 SG_ APP_sw005_RadarLowVisibility m5 : 46|1@1+ (1,0) [0|0] "" GTW
 SG_ APP_sw005_radCalibration m5 : 47|1@1+ (1,0) [0|0] "" GTW
 SG_ APP_sw006_RadarLowVisibility m6 : 16|1@1+ (1,0) [0|0] "" GTW
 SG_ APP_sw006_RadarMisaligned m6 : 17|1@1+ (1,0) [0|0] "" GTW
 SG_ APP_sw006_OutOfFocusImage m6 : 18|1@1+ (1,0) [0|0] "" GTW
 SG_ APP_sw006_SunRay m6 : 19|1@1+ (1,0) [0|0] "" GTW
 SG_ APP_sw006_Splashes m6 : 20|1@1+ (1,0) [0|0] "" GTW
 SG_ APP_sw006_BlurredImage m6 : 21|1@1+ (1,0) [0|0] "" GTW
 SG_ APP_sw006_LowSun m6 : 22|1@1+ (1,0) [0|0] "" GTW
 SG_ APP_sw006_SmearedSpots m6 : 23|1@1+ (1,0) [0|0] "" GTW
 SG_ APP_sw006_PartialBlockage m6 : 24|1@1+ (1,0) [0|0] "" GTW
 SG_ APP_sw006_AutofixOutOfCalib m6 : 25|1@1+ (1,0) [0|0] "" GTW
 SG_ APP_sw006_AutofixOutOfCalibHorzn m6 : 26|1@1+ (1,0) [0|0] "" GTW
 SG_ APP_sw006_AutofixOutOfCalibYaw m6 : 27|1@1+ (1,0) [0|0] "" GTW
 SG_ APP_sw006_FullBlockage m6 : 28|1@1+ (1,0) [0|0] "" GTW
 SG_ APP_sw006_SmearedHalos m6 : 29|1@1+ (1,0) [0|0] "" GTW
 SG_ APP_sw006_FoggyLights m6 : 30|1@1+ (1,0) [0|0] "" GTW
 SG_ APP_sw006_SelfGlare m6 : 31|1@1+ (1,0) [0|0] "" GTW
 SG_ APP_sw006_blinkers m6 : 32|1@1+ (1,0) [0|0] "" GTW
 SG_ APP_sw006_seatbelt m6 : 33|1@1+ (1,0) [0|0] "" GTW
 SG_ APP_sw006_accelPedal m6 : 34|1@1+ (1,0) [0|0] "" GTW
 SG_ APP_sw006_radMia m6 : 35|1@1+ (1,0) [0|0] "" GTW
 SG_ APP_sw006_radHWFailure m6 : 37|1@1+ (1,0) [0|0] "" GTW
 SG_ APP_sw006_radSensorBlind m6 : 38|1@1+ (1,0) [0|0] "" GTW
 SG_ APP_sw006_radSGUFailure m6 : 39|1@1+ (1,0) [0|0] "" GTW
 SG_ APP_sw006_brakePedal m6 : 40|1@1+ (1,0) [0|0] "" GTW
 SG_ APP_sw006_steeringAngle m6 : 41|1@1+ (1,0) [0|0] "" GTW
 SG_ APP_sw006_steeringAngleRate m6 : 42|1@1+ (1,0) [0|0] "" GTW
 SG_ APP_sw006_speed m6 : 43|1@1+ (1,0) [0|0] "" GTW
 SG_ APP_sw006_gear m6 : 44|1@1+ (1,0) [0|0] "" GTW
 SG_ APP_sw006_stabilityControl m6 : 45|1@1+ (1,0) [0|0] "" GTW
 SG_ APP_sw006_dasDisabled m6 : 47|1@1+ (1,0) [0|0] "" GTW
 SG_ APP_sw006_speedDerivative m6 : 48|1@1+ (1,0) [0|0] "" GTW
 SG_ APP_sw006_camWatchdog m6 : 49|1@1+ (1,0) [0|0] "" GTW
 SG_ APP_sw006_camObjHeader m6 : 50|1@1+ (1,0) [0|0] "" GTW
 SG_ APP_sw006_camCommonMsg m6 : 51|1@1+ (1,0) [0|0] "" GTW
 SG_ APP_sw006_camFcwPcwMsg m6 : 52|1@1+ (1,0) [0|0] "" GTW
 SG_ APP_sw006_longAccel m6 : 53|1@1+ (1,0) [0|0] "" GTW
 SG_ APP_sw006_yawRate m6 : 54|1@1+ (1,0) [0|0] "" GTW
 SG_ APP_sw006_DIaebState_SNA m6 : 55|1@1+ (1,0) [0|0] "" GTW
 SG_ APP_sw006_DIaebStateUnavailable m6 : 56|1@1+ (1,0) [0|0] "" GTW
 SG_ APP_sw006_brakeLights m6 : 57|1@1+ (1,0) [0|0] "" GTW
 SG_ APP_sw006_trailerMode m6 : 58|1@1+ (1,0) [0|0] "" GTW
 SG_ APP_sw006_timeOfDay m6 : 59|2@1+ (1,0) [0|0] "" GTW
 SG_ APP_sw006_radCalibration m6 : 61|1@1+ (1,0) [0|0] "" GTW
 SG_ APP_sw009_DIaebState_fault m9 : 16|1@1+ (1,0) [0|0] "" GTW
 SG_ APP_sw009_DI_aeb_unresponsive m9 : 17|1@1+ (1,0) [0|0] "" GTW
 SG_ APP_sw009_DI_MIA m9 : 18|1@1+ (1,0) [0|0] "" GTW
 SG_ APP_sw010_a04calibNotDone m10 : 16|1@1+ (1,0) [0|0] "" GTW
 SG_ APP_sw010_a05calibReqd m10 : 17|1@1+ (1,0) [0|0] "" GTW
 SG_ APP_sw010_a06calibNotOK m10 : 18|1@1+ (1,0) [0|0] "" GTW
 SG_ APP_sw010_a08PlantMode m10 : 19|1@1+ (1,0) [0|0] "" GTW
 SG_ APP_sw010_HorizontalMisalignment m10 : 20|16@1+ (0.00137332,-45) [-45|45.0005262] "deg" GTW
 SG_ APP_sw010_VerticalMisalignment m10 : 36|10@1+ (0.087977,-45) [-45|45.000471] "deg" GTW
 SG_ APP_sw010_unusedBits m10 : 46|2@1+ (1,0) [0|0] "" GTW
 SG_ APP_sw010_VmaPlausibility m10 : 48|16@1+ (1.52587890625005E-05,0) [0|0.99998474121097] "" GTW
 SG_ APP_sw011_scaState m11 : 16|3@1+ (1,0) [0|7] "" GTW
 SG_ APP_sw011_scaLeft m11 : 19|1@1+ (1,0) [0|1] "" GTW
 SG_ APP_sw011_scaRight m11 : 20|1@1+ (1,0) [0|1] "" GTW
 SG_ APP_sw011_scaBlinker m11 : 21|2@1+ (1,0) [0|3] "" GTW
 SG_ APP_sw011_scaThreshold m11 : 23|1@1+ (1,0) [0|1] "" GTW
 SG_ APP_sw011_scaSpeed m11 : 24|7@1+ (1,0) [0|127] "MPH" GTW
 SG_ APP_sw011_scaSonicDist m11 : 31|5@1+ (0.05,0) [0|1.5] "m" GTW
 SG_ APP_sw011_scaSteerAngle m11 : 38|10@1+ (0.1,-51.2) [-51.2|51.1] "deg" GTW
 SG_ APP_sw011_egoRightOfCenter m11 : 48|1@1+ (1,0) [0|1] "" GTW
 SG_ APP_sw011_egoMovingRight m11 : 49|1@1+ (1,0) [0|1] "" GTW
 SG_ APP_sw011_egoLeftOfCenter m11 : 50|1@1+ (1,0) [0|1] "" GTW
 SG_ APP_sw011_egoMovingLeft m11 : 51|1@1+ (1,0) [0|1] "" GTW
 SG_ APP_sw011_polyValid m11 : 52|1@1+ (1,0) [0|1] "" GTW
 SG_ APP_sw011_egoCentered m11 : 53|1@1+ (1,0) [0|1] "" GTW
 SG_ APP_sw011_scaReasonEldw m11 : 54|1@1+ (1,0) [0|1] "" GTW
 SG_ APP_sw011_laneWidth m11 : 56|8@1+ (0.025,0) [0|6.375] "m" GTW
 SG_ APP_sw012_bootTestResults m12 : 16|16@1+ (1,0) [0|65535] "" GTW
 SG_ APP_sw012_bootDDRTempStatus m12 : 32|2@1+ (1,0) [0|3] "" GTW
 SG_ APP_sw012_mespFatalErrCode m12 : 34|8@1+ (1,0) [0|255] "" GTW
 SG_ APP_sw012_mespFatalErrDetails m12 : 42|8@1+ (1,0) [0|255] "" GTW
 SG_ APP_sw012_mespDDRTempStatus m12 : 50|3@1+ (1,0) [0|7] "" GTW
 SG_ APP_sw012_freescaleTemp m12 : 56|8@1- (1,0) [-128|127] "degC" GTW
 SG_ APP_sw013_stateBeforeWatchdog m13 : 16|5@1+ (1,0) [0|0] "" GTW
 SG_ APP_sw013_numEyeqResets m13 : 21|3@1+ (1,0) [0|0] "" GTW
 SG_ APP_sw013_numCrcErrors m13 : 24|8@1+ (1,0) [0|0] "" GTW
 SG_ APP_sw013_numSeqErrors m13 : 32|8@1+ (1,0) [0|0] "" GTW
 SG_ APP_sw013_numNaksReceived m13 : 40|8@1+ (1,0) [0|0] "" GTW
 SG_ APP_sw013_highestSeqRecd m13 : 48|12@1+ (1,0) [0|0] "" GTW
 SG_ APP_sw013_numTransportErrors m13 : 60|4@1+ (1,0) [0|0] "" GTW
 SG_ APP_sw014_fileNameHash m14 : 16|16@1+ (1,0) [0|0] "" GTW
 SG_ APP_sw014_lineNumberInCode m14 : 32|16@1+ (1,0) [0|0] "" GTW
 SG_ APP_sw014_assertData m14 : 48|16@1+ (1,0) [0|0] "" GTW
 SG_ APP_sw015_RadarLowVisibility m15 : 16|2@1+ (1,0) [0|1] "" GTW
 SG_ APP_sw015_RadarMisalignment m15 : 18|2@1+ (1,0) [0|1] "" GTW
 SG_ APP_sw015_LowSun m15 : 20|2@1+ (1,0) [0|1] "" GTW
 SG_ APP_sw015_BlurredImage m15 : 22|2@1+ (1,0) [0|1] "" GTW
 SG_ APP_sw015_FullBlockage m15 : 24|2@1+ (1,0) [0|1] "" GTW
 SG_ APP_sw015_PartialBlockage m15 : 26|2@1+ (1,0) [0|1] "" GTW
 SG_ APP_sw015_AutofixOutOfCalib m15 : 28|2@1+ (1,0) [0|1] "" GTW
 SG_ APP_sw015_AutofixOutOfCalibYaw m15 : 30|2@1+ (1,0) [0|1] "" GTW
 SG_ APP_sw015_AutofixOOfCalibHorizon m15 : 32|2@1+ (1,0) [0|1] "" GTW
 SG_ APP_sw015_Splashes m15 : 34|2@1+ (1,0) [0|1] "" GTW
 SG_ APP_sw015_SmearedSpots m15 : 36|2@1+ (1,0) [0|1] "" GTW
 SG_ APP_sw015_SmearedHalos m15 : 38|2@1+ (1,0) [0|1] "" GTW
 SG_ APP_sw015_FoggyLights m15 : 40|2@1+ (1,0) [0|1] "" GTW
 SG_ APP_sw015_SunRay m15 : 42|2@1+ (1,0) [0|1] "" GTW
 SG_ APP_sw015_ImpairedVD m15 : 44|2@1+ (1,0) [0|1] "" GTW
 SG_ APP_sw015_SelfGlare m15 : 46|2@1+ (1,0) [0|1] "" GTW
 SG_ APP_sw015_OutOfFocusImage m15 : 48|2@1+ (1,0) [0|1] "" GTW
 SG_ APP_sw016_targetDist m16 : 16|9@1+ (0.2,0) [0|102.2] "m" GTW
 SG_ APP_sw016_targetRelSpeed m16 : 25|9@1+ (0.0625,-31) [-31|0.9375] "m/s" GTW
 SG_ APP_sw016_targetOverlap m16 : 34|6@1+ (0.1,0) [0|6.3] "m" GTW
 SG_ APP_sw016_hostSpeed m16 : 40|8@1+ (1,0) [0|255] "kph" GTW
 SG_ APP_sw016_hostLongAccel m16 : 48|7@1+ (0.15625,-10) [-10|10] "m/s^2" GTW
 SG_ APP_sw016_driverPressedAccelPed m16 : 55|1@1+ (1,0) [0|1] "" GTW
 SG_ APP_sw016_driverPressedBrakePed m16 : 56|1@1+ (1,0) [0|1] "" GTW
 SG_ APP_sw016_aebEnable m16 : 57|1@1+ (1,0) [0|1] "" GTW
 SG_ APP_sw016_overrideBlinker m16 : 58|1@1+ (1,0) [0|1] "" GTW
 SG_ APP_sw016_overrideBrake m16 : 59|1@1+ (1,0) [0|1] "" GTW
 SG_ APP_sw016_overrideSteer m16 : 60|1@1+ (1,0) [0|1] "" GTW
 SG_ APP_sw016_fcmModeAtEvent m16 : 61|2@1+ (1,0) [0|3] "" GTW
 SG_ APP_sw016_accActive m16 : 63|1@1+ (1,0) [0|1] "" GTW
 SG_ APP_sw017_Camera_Msg_Lanes_MIA m17 : 16|1@1+ (1,0) [0|1] "" GTW
 SG_ APP_sw017_Camera_Msg_Objects_MIA m17 : 17|1@1+ (1,0) [0|1] "" GTW
 SG_ APP_sw017_Camera_Msg_Tsr_MIA m17 : 18|1@1+ (1,0) [0|1] "" GTW
 SG_ APP_sw017_Camera_Msg_Hlb_MIA m17 : 19|1@1+ (1,0) [0|1] "" GTW
 SG_ APP_sw017_Camera_Msg_Common_MIA m17 : 20|1@1+ (1,0) [0|1] "" GTW
 SG_ APP_sw017_Camera_Msg_FCW_PCW_MIA m17 : 21|1@1+ (1,0) [0|1] "" GTW
 SG_ APP_sw017_Camera_Msg_TFL_MIA m17 : 22|1@1+ (1,0) [0|1] "" GTW
 SG_ APP_sw017_Any_Lanes_Msg_Recd m17 : 23|1@1+ (1,0) [0|1] "" GTW
 SG_ APP_sw017_Any_Objects_Msg_Recd m17 : 24|1@1+ (1,0) [0|1] "" GTW
 SG_ APP_sw017_Any_TFL_Msg_Recd m17 : 25|1@1+ (1,0) [0|1] "" GTW
 SG_ APP_sw017_numCrcErrors m17 : 26|6@1+ (1,0) [0|63] "" GTW
 SG_ APP_sw017_numSeqErrors m17 : 32|8@1+ (1,0) [0|255] "" GTW
 SG_ APP_sw017_numTransportErrors m17 : 40|8@1+ (1,0) [0|0] "" GTW
 SG_ APP_sw017_highestSeqRecd m17 : 48|12@1+ (1,0) [0|0] "" GTW
 SG_ APP_sw017_Any_Tsr_Msg_Recd m17 : 60|1@1+ (1,0) [0|1] "" GTW
 SG_ APP_sw017_Any_Hlb_Msg_Recd m17 : 61|1@1+ (1,0) [0|1] "" GTW
 SG_ APP_sw017_Any_Common_Msg_Recd m17 : 62|1@1+ (1,0) [0|1] "" GTW
 SG_ APP_sw017_Any_FCW_PCW_Msg_Recd m17 : 63|1@1+ (1,0) [0|1] "" GTW
 SG_ APP_sw018_minThreshold m18 : 16|13@1+ (1,0) [0|4500] "mV" GTW
 SG_ APP_sw018_railID m18 : 29|2@1+ (1,0) [0|3] "" GTW
 SG_ APP_sw018_powerSequnceError m18 : 31|1@1+ (1,0) [0|3] "" GTW
 SG_ APP_sw018_maxThreshold m18 : 32|15@1+ (1,0) [50|5500] "mV" GTW
 SG_ APP_sw018_railControl m18 : 47|1@1+ (1,0) [0|1] "" GTW
 SG_ APP_sw018_currentVoltage m18 : 48|16@1+ (1,0) [0|6600] "mV" GTW
 SG_ APP_sw019_taskId m19 : 16|8@1+ (1,0) [0|0] "" GTW
 SG_ APP_sw019_numFreeBytes m19 : 24|8@1+ (1,-191) [-191|64] "# of bytes" GTW
 SG_ APP_sw019_timeStamp m19 : 32|32@1+ (1,0) [0|4294967295] "ms" GTW
 SG_ APP_sw020_unusedW0 m20 : 16|16@1+ (1,0) [0|0] "" GTW
 SG_ APP_sw020_unusedW1 m20 : 32|16@1+ (1,0) [0|0] "" GTW
 SG_ APP_sw020_unusedW2 m20 : 48|16@1+ (1,0) [0|0] "" GTW
 SG_ APP_sw021_tempSensorId m21 : 16|8@1+ (1,0) [0|4] "" GTW
 SG_ APP_sw021_minThreshold m21 : 24|8@1- (1,0) [-128|127] "degC" GTW
 SG_ APP_sw021_maxThreshold m21 : 32|8@1- (1,0) [-128|127] "degC" GTW
 SG_ APP_sw021_currentTemperature m21 : 40|8@1- (1,0) [-128|127] "degC" GTW
 SG_ APP_sw021_unusedWord m21 : 48|16@1+ (1,0) [0|0] "" GTW
 SG_ APP_sw022_operation m22 : 16|4@1+ (1,0) [0|0] "" GTW
 SG_ APP_sw022_recordId m22 : 20|12@1+ (1,0) [0|0] "" GTW
 SG_ APP_sw022_errorCode m22 : 32|32@1+ (1,0) [0|0] "" GTW
 SG_ APP_sw024_Task_ID m24 : 16|4@1+ (1,0) [0|0] "" GTW
 SG_ APP_sw024_numVirtualLaneVeh m24 : 20|4@1+ (1,0) [0|0] "" GTW
 SG_ APP_sw024_currentVehicleApp m24 : 24|8@1+ (1,0) [0|0] "" GTW
 SG_ APP_sw024_taskProgramCounter m24 : 32|32@1+ (1,0) [0|0] "" GTW
 SG_ APP_sw025_state_before_override m25 : 16|4@1+ (1,0) [0|15] "" GTW
 SG_ APP_sw025_road_class m25 : 20|3@1+ (1,0) [0|0] "" GTW
 SG_ APP_sw025_road_match m25 : 23|1@1+ (1,0) [0|0] "" GTW
 SG_ APP_sw025_controlled_access m25 : 24|1@1+ (1,0) [0|0] "" GTW
 SG_ APP_sw025_leftLaneUsage m25 : 25|2@1+ (1,0) [0|3] "" GTW
 SG_ APP_sw025_rightLaneUsage m25 : 27|2@1+ (1,0) [0|3] "" GTW
 SG_ APP_sw025_vehiclesUsage m25 : 29|2@1+ (1,0) [0|3] "" GTW
 SG_ APP_sw025_hppUsage m25 : 31|2@1+ (1,0) [0|3] "" GTW
 SG_ APP_sw025_navigationUsage m25 : 33|2@1+ (1,0) [0|3] "" GTW
 SG_ APP_sw025_modelUsage m25 : 35|2@1+ (1,0) [0|3] "" GTW
 SG_ APP_sw025_bottsDotsUsage m25 : 37|2@1+ (1,0) [0|3] "" GTW
 SG_ APP_sw025_offsetSide m25 : 39|2@1+ (1,0) [0|3] "" GTW
 SG_ APP_sw025_torsionBarTorque m25 : 41|8@1+ (0.1,-12.8) [-12.8|12.7] "Nm" GTW
 SG_ APP_sw026_task_id m26 : 16|2@1+ (1,0) [0|3] "" GTW
 SG_ APP_sw026_tardiness m26 : 18|9@1+ (0.25,0) [0|127.75] "ms" GTW
 SG_ APP_sw026_execution_time m26 : 27|9@1+ (0.125,0) [0|65.411] "ms" GTW
 SG_ APP_sw026_can_mean_utilization m26 : 36|7@1+ (1,0) [0|127] "percent" GTW
 SG_ APP_sw026_uds_mean_utilization m26 : 43|7@1+ (1,0) [0|127] "percent" GTW
 SG_ APP_sw026_mob_mean_utilization m26 : 50|7@1+ (1,0) [0|127] "percent" GTW
 SG_ APP_sw026_veh_mean_utilization m26 : 57|7@1+ (1,0) [0|127] "percent" GTW
 SG_ APP_sw027_JTAG_Reset m27 : 16|1@1+ (1,0) [0|0] "" GTW
 SG_ APP_sw027_Core_Reset m27 : 17|1@1+ (1,0) [0|0] "" GTW
 SG_ APP_sw027_Unused_Bit_0 m27 : 18|1@1+ (1,0) [0|0] "" GTW
 SG_ APP_sw027_CPU_Checkstop_Error m27 : 19|1@1+ (1,0) [0|0] "" GTW
 SG_ APP_sw027_PLL_0_Failure m27 : 20|1@1+ (1,0) [0|0] "" GTW
 SG_ APP_sw027_Clock_Monitor_0_Low m27 : 21|1@1+ (1,0) [0|0] "" GTW
 SG_ APP_sw027_Clock_Monitor_0_Off m27 : 22|1@1+ (1,0) [0|0] "" GTW
 SG_ APP_sw027_LVD_4v5 m27 : 23|1@1+ (1,0) [0|0] "" GTW
 SG_ APP_sw027_Flash_Fatal_Error m27 : 24|1@1+ (1,0) [0|0] "" GTW
 SG_ APP_sw027_PLL_1_Failure m27 : 25|1@1+ (1,0) [0|0] "" GTW
 SG_ APP_sw027_Unused_Bit_1 m27 : 26|1@1+ (1,0) [0|0] "" GTW
 SG_ APP_sw027_f_PLL_1_Off m27 : 27|1@1+ (1,0) [0|0] "" GTW
 SG_ APP_sw027_Unused_Nibble m27 : 28|4@1+ (1,0) [0|0] "" GTW
 SG_ APP_sw027_LVD_1v2 m27 : 32|1@1+ (1,0) [0|0] "" GTW
 SG_ APP_sw027_Unused_Bit_2 m27 : 33|1@1+ (1,0) [0|0] "" GTW
 SG_ APP_sw027_Watchdog m27 : 34|1@1+ (1,0) [0|0] "" GTW
 SG_ APP_sw027_Unused_Bit_3 m27 : 35|1@1+ (1,0) [0|0] "" GTW
 SG_ APP_sw027_LVD_2v7_VREG m27 : 36|1@1+ (1,0) [0|0] "" GTW
 SG_ APP_sw027_LVD_2v7_Flash m27 : 37|1@1+ (1,0) [0|0] "" GTW
 SG_ APP_sw027_LVD_2v7_IO m27 : 38|1@1+ (1,0) [0|0] "" GTW
 SG_ APP_sw027_Unused_Bit_4 m27 : 39|1@1+ (1,0) [0|0] "" GTW
 SG_ APP_sw027_Unused_Byte m27 : 40|8@1+ (1,0) [0|0] "" GTW
 SG_ APP_sw027_ESR0 m27 : 48|1@1+ (1,0) [0|0] "" GTW
 SG_ APP_sw027_ESR1 m27 : 49|1@1+ (1,0) [0|0] "" GTW
 SG_ APP_sw027_SW m27 : 50|1@1+ (1,0) [0|0] "" GTW
 SG_ APP_sw027_STM0 m27 : 51|1@1+ (1,0) [0|0] "" GTW
 SG_ APP_sw027_STM1 m27 : 52|1@1+ (1,0) [0|0] "" GTW
 SG_ APP_sw027_STM2 m27 : 53|1@1+ (1,0) [0|0] "" GTW
 SG_ APP_sw027_CBS_SYSTEM m27 : 54|1@1+ (1,0) [0|0] "" GTW
 SG_ APP_sw027_CBS_DEBUG m27 : 55|1@1+ (1,0) [0|0] "" GTW
 SG_ APP_sw027_CBS_APP m27 : 56|1@1+ (1,0) [0|0] "" GTW
 SG_ APP_sw027_EVR13 m27 : 57|1@1+ (1,0) [0|0] "" GTW
 SG_ APP_sw027_EVR33 m27 : 58|1@1+ (1,0) [0|0] "" GTW
 SG_ APP_sw027_SWD m27 : 59|1@1+ (1,0) [0|0] "" GTW
 SG_ APP_sw027_STDBY_WDG m27 : 60|1@1+ (1,0) [0|0] "" GTW
 SG_ APP_sw027_PORST m27 : 61|1@1+ (1,0) [0|0] "" GTW
 SG_ APP_sw027_Unused_word m27 : 62|2@1+ (1,0) [0|0] "" GTW
 SG_ APP_sw028_rx_buffer_full m28 : 16|1@1+ (1,0) [0|0] "" GTW
 SG_ APP_sw028_rx_inv_len m28 : 17|1@1+ (1,0) [0|0] "" GTW
 SG_ APP_sw028_inv_multifrm_1st m28 : 18|1@1+ (1,0) [0|0] "" GTW
 SG_ APP_sw028_inv_multifrm_id m28 : 19|1@1+ (1,0) [0|0] "" GTW
 SG_ APP_sw028_inv_multifrm_next m28 : 20|1@1+ (1,0) [0|0] "" GTW
 SG_ APP_sw028_unusedBits m28 : 21|11@1+ (1,0) [0|0] "" GTW
 SG_ APP_sw028_highestSeqRcvd m28 : 32|16@1+ (1,0) [0|0] "" GTW
 SG_ APP_sw028_multifrm_rx_len m28 : 48|16@1+ (1,0) [0|0] "" GTW
 SG_ APP_sw029_tx_buffer_full m29 : 16|1@1+ (1,0) [0|0] "" GTW
 SG_ APP_sw029_unusedBits m29 : 17|15@1+ (1,0) [0|0] "" GTW
 SG_ APP_sw029_highestSeqRcvd m29 : 32|16@1+ (1,0) [0|0] "" GTW
 SG_ APP_sw029_unusedW1 m29 : 48|16@1+ (1,0) [0|0] "" GTW
 SG_ APP_sw030_heaterState m30 : 16|8@1+ (1,0) [0|0] "" GTW
 SG_ APP_sw030_unusedByte m30 : 24|8@1+ (1,0) [0|0] "" GTW
 SG_ APP_sw030_unusedW0 m30 : 32|16@1+ (1,0) [0|0] "" GTW
 SG_ APP_sw030_unusedW1 m30 : 48|16@1+ (1,0) [0|0] "" GTW
 SG_ APP_sw031_canBus m31 : 16|4@1+ (1,0) [0|0] "" GTW
 SG_ APP_sw031_errorType m31 : 24|8@1+ (1,0) [0|0] "" GTW
 SG_ APP_sw031_errorData1 m31 : 32|16@1+ (1,0) [0|0] "" GTW
 SG_ APP_sw031_errorData2 m31 : 48|16@1+ (1,0) [0|0] "" GTW
 SG_ APP_sw032_canBus m32 : 16|4@1+ (1,0) [0|0] "" GTW
 SG_ APP_sw032_errorType m32 : 24|8@1+ (1,0) [0|0] "" GTW
 SG_ APP_sw032_errorData1 m32 : 32|16@1+ (1,0) [0|0] "" GTW
 SG_ APP_sw032_errorData2 m32 : 48|16@1+ (1,0) [0|0] "" GTW
 SG_ APP_sw033_gtwMia m33 : 16|8@1+ (1,0) [0|0] "" GTW
 SG_ APP_sw033_unusedByte m33 : 24|8@1+ (1,0) [0|0] "" GTW
 SG_ APP_sw033_bcStatus m33 : 32|1@1+ (1,0) [0|0] "" GTW
 SG_ APP_sw033_carConfig m33 : 33|1@1+ (1,0) [0|0] "" GTW
 SG_ APP_sw033_carState m33 : 34|1@1+ (1,0) [0|0] "" GTW
 SG_ APP_sw033_chNm m33 : 35|1@1+ (1,0) [0|0] "" GTW
 SG_ APP_sw033_odo m33 : 36|1@1+ (1,0) [0|0] "" GTW
 SG_ APP_sw033_status m33 : 37|1@1+ (1,0) [0|0] "" GTW
 SG_ APP_sw033_vip m33 : 38|1@1+ (1,0) [0|0] "" GTW
 SG_ APP_sw034_sccmMia m34 : 16|8@1+ (1,0) [0|0] "" GTW
 SG_ APP_sw034_unusedByte m34 : 24|8@1+ (1,0) [0|0] "" GTW
 SG_ APP_sw034_sbwRq m34 : 32|1@1+ (1,0) [0|0] "" GTW
 SG_ APP_sw034_stwActnRq m34 : 33|1@1+ (1,0) [0|0] "" GTW
 SG_ APP_sw034_stwAnglHpStat m34 : 34|1@1+ (1,0) [0|0] "" GTW
 SG_ APP_sw035_espMia m35 : 16|8@1+ (1,0) [0|0] "" GTW
 SG_ APP_sw035_unusedByte m35 : 24|8@1+ (1,0) [0|0] "" GTW
 SG_ APP_sw035_115h m35 : 32|1@1+ (1,0) [0|0] "" GTW
 SG_ APP_sw035_125h m35 : 33|1@1+ (1,0) [0|0] "" GTW
 SG_ APP_sw035_135h m35 : 34|1@1+ (1,0) [0|0] "" GTW
 SG_ APP_sw035_145h m35 : 35|1@1+ (1,0) [0|0] "" GTW
 SG_ APP_sw035_B m35 : 36|1@1+ (1,0) [0|0] "" GTW
 SG_ APP_sw035_C m35 : 37|1@1+ (1,0) [0|0] "" GTW
 SG_ APP_sw035_wheelSpeeds m35 : 38|1@1+ (1,0) [0|0] "" GTW
 SG_ APP_sw036_bdyMia m36 : 16|8@1+ (1,0) [0|0] "" GTW
 SG_ APP_sw036_unusedByte m36 : 24|8@1+ (1,0) [0|0] "" GTW
 SG_ APP_sw036_status m36 : 32|1@1+ (1,0) [0|0] "" GTW
 SG_ APP_sw037_camera m37 : 16|8@1+ (1,0) [0|0] "" GTW
 SG_ APP_sw037_issue m37 : 24|8@1+ (1,0) [0|0] "" GTW
 SG_ APP_sw037_unusedW0 m37 : 32|16@1+ (1,0) [0|0] "" GTW
 SG_ APP_sw037_unusedW1 m37 : 48|16@1+ (1,0) [0|0] "" GTW
 SG_ APP_sw038_RadarMisalignment m38 : 17|1@1+ (1,0) [0|1] "" GTW
 SG_ APP_sw038_OutOfFocusImage m38 : 18|1@1+ (1,0) [0|1] "" GTW
 SG_ APP_sw038_AutofixOutOfCalib m38 : 19|1@1+ (1,0) [0|1] "" GTW
 SG_ APP_sw038_AutofixOutOfCalibHorzn m38 : 20|1@1+ (1,0) [0|1] "" GTW
 SG_ APP_sw038_AutofixOutOfCalibYaw m38 : 21|1@1+ (1,0) [0|1] "" GTW
 SG_ APP_sw038_FullBlockage m38 : 22|1@1+ (1,0) [0|1] "" GTW
 SG_ APP_sw038_TooManyResets m38 : 23|1@1+ (1,0) [0|1] "" GTW
 SG_ APP_sw039_sdm_rcm_Mia m39 : 16|8@1+ (1,0) [0|0] "" GTW
 SG_ APP_sw039_unusedByte m39 : 24|8@1+ (1,0) [0|0] "" GTW
 SG_ APP_sw039_status m39 : 32|1@1+ (1,0) [0|0] "" GTW
 SG_ APP_sw039_sdm1 m39 : 33|1@1+ (1,0) [0|0] "" GTW
 SG_ APP_sw040_accel_pedal_pos m40 : 16|8@1+ (0.5,0) [0|127.5] "%" GTW
 SG_ APP_sw040_ego_veh_speed m40 : 24|8@1+ (0.2,0) [0|51] "m/s" GTW
 SG_ APP_sw040_das_steering_req m40 : 32|8@1+ (1,-128) [-128|127] "deg" GTW
 SG_ APP_sw040_epas_internal_sas m40 : 40|8@1+ (1,-128) [-128|127] "deg" GTW
 SG_ APP_sw040_torsion_bar_torque m40 : 48|8@1+ (0.1,-12.8) [-12.8|12.7] "Nm" GTW
 SG_ APP_sw040_view_range m40 : 56|8@1+ (1,0) [0|255] "m" GTW
 SG_ APP_sw041_rate m41 : 16|10@1- (1,0) [-512|511] "deg/s" GTW
 SG_ APP_sw041_max_rate m41 : 26|10@1- (1,0) [-512|511] "deg/s" GTW
 SG_ APP_sw041_ego_speed m41 : 36|10@1+ (0.05,0) [0|51.15] "m/s" GTW
 SG_ APP_sw041_unusedW2 m41 : 46|18@1+ (1,0) [0|0] "" GTW
 SG_ APP_sw042_health_state m42 : 16|3@1+ (1,0) [0|0] "" GTW
 SG_ APP_sw042_abort_reason m42 : 19|5@1+ (1,0) [0|31] "" GTW
 SG_ APP_sw042_view_range m42 : 24|8@1+ (1,0) [0|0] "" GTW
 SG_ APP_sw042_state_before_abort m42 : 32|4@1+ (1,0) [0|15] "" GTW
 SG_ APP_sw042_epas_error_code m42 : 36|4@1+ (1,0) [0|15] "" GTW
 SG_ APP_sw042_cam_SunRay m42 : 40|1@1+ (1,0) [0|1] "" GTW
 SG_ APP_sw042_cam_RoadSpray m42 : 41|1@1+ (1,0) [0|1] "" GTW
 SG_ APP_sw042_cam_BlurredImage m42 : 42|1@1+ (1,0) [0|1] "" GTW
 SG_ APP_sw042_cam_LowSun m42 : 43|1@1+ (1,0) [0|1] "" GTW
 SG_ APP_sw042_cam_SmearedSpots m42 : 44|1@1+ (1,0) [0|1] "" GTW
 SG_ APP_sw042_cam_PartialBlock m42 : 45|1@1+ (1,0) [0|1] "" GTW
 SG_ APP_sw042_cam_Autofix m42 : 46|1@1+ (1,0) [0|1] "" GTW
 SG_ APP_sw042_cam_AutofixHorizon m42 : 47|1@1+ (1,0) [0|1] "" GTW
 SG_ APP_sw042_cam_AutofixYaw m42 : 48|1@1+ (1,0) [0|1] "" GTW
 SG_ APP_sw042_cam_FullBlock m42 : 49|1@1+ (1,0) [0|1] "" GTW
 SG_ APP_sw042_cam_SmearedHalos m42 : 50|1@1+ (1,0) [0|1] "" GTW
 SG_ APP_sw042_cam_FoggySpots m42 : 51|1@1+ (1,0) [0|1] "" GTW
 SG_ APP_sw042_cam_SelfGlare m42 : 52|1@1+ (1,0) [0|1] "" GTW
 SG_ APP_sw042_cam_OutofFocus m42 : 53|1@1+ (1,0) [0|1] "" GTW
 SG_ APP_sw042_road_match m42 : 54|1@1+ (1,0) [0|1] "" GTW
 SG_ APP_sw042_controlled_access m42 : 55|1@1+ (1,0) [0|1] "" GTW
 SG_ APP_sw042_road_class m42 : 56|3@1+ (1,0) [0|7] "" GTW
 SG_ APP_sw043_mobileye_status m43 : 16|16@1+ (1,0) [0|0] "" GTW
 SG_ APP_sw043_mesp_health_main_state m43 : 32|16@1+ (1,0) [0|0] "" GTW
 SG_ APP_sw043_camLongRunTime_unused m43 : 48|16@1+ (1,0) [0|0] "" GTW
 SG_ APP_sw044_countLSB m44 : 16|8@1+ (1,0) [0|0] "" GTW
 SG_ APP_sw044_meMainState m44 : 28|4@1+ (1,0) [0|15] "" GTW
 SG_ APP_sw044_timestampms m44 : 32|24@1+ (1,0) [0|16777215] "ms" GTW
 SG_ APP_sw044_appStatus m44 : 56|8@1+ (1,0) [0|63] "" GTW
 SG_ APP_sw045_radMia m45 : 16|8@1+ (1,0) [0|0] "" GTW
 SG_ APP_sw045_unusedByte m45 : 24|8@1+ (1,0) [0|0] "" GTW
 SG_ APP_sw045_radcAlertMatrix m45 : 32|1@1+ (1,0) [0|0] "" GTW
 SG_ APP_sw045_radcInfo m45 : 33|1@1+ (1,0) [0|0] "" GTW
 SG_ APP_sw045_radcAccTargObj1A m45 : 34|1@1+ (1,0) [0|0] "" GTW
 SG_ APP_sw045_lrrAlertMatrix0 m45 : 35|1@1+ (1,0) [0|0] "" GTW
 SG_ APP_sw045_lrrPacketEnder m45 : 36|1@1+ (1,0) [0|0] "" GTW
 SG_ APP_sw045_lrrRadarStatus m45 : 37|1@1+ (1,0) [0|0] "" GTW
 SG_ APP_sw045_lrrObj00A m45 : 38|1@1+ (1,0) [0|0] "" GTW
 SG_ APP_sw046_recordId m46 : 16|16@1+ (1,0) [0|0] "" GTW
 SG_ APP_sw046_errorCode m46 : 32|32@1+ (1,0) [0|0] "" GTW
 SG_ APP_sw047_edrStatus m47 : 16|4@1+ (1,0) [0|0] "" GTW
 SG_ APP_sw047_roadClass m47 : 20|3@1+ (1,0) [0|0] "" GTW
 SG_ APP_sw047_controlledAccess m47 : 23|1@1+ (1,0) [0|0] "" GTW
 SG_ APP_sw047_edrType m47 : 24|6@1+ (1,0) [0|0] "" GTW
 SG_ APP_sw047_edrBlackBox m47 : 30|2@1+ (1,0) [0|0] "" GTW
 SG_ APP_sw047_edrReturn m47 : 32|16@1+ (1,0) [0|0] "" GTW
 SG_ APP_sw047_edrStateMachine m47 : 48|8@1+ (1,0) [0|0] "" GTW
 SG_ APP_sw047_edrLoggerBuffer m47 : 56|2@1+ (1,0) [0|0] "" GTW
 SG_ APP_sw047_unused m47 : 58|6@1+ (1,0) [0|0] "" GTW
 SG_ APP_sw048_swAssert m48 : 16|1@1+ (1,0) [0|1] "" GTW
 SG_ APP_sw048_thermalIssue m48 : 17|1@1+ (1,0) [0|1] "" GTW
 SG_ APP_sw048_powerIssue m48 : 18|1@1+ (1,0) [0|1] "" GTW
 SG_ APP_sw048_stackOverflow m48 : 19|1@1+ (1,0) [0|1] "" GTW
 SG_ APP_sw048_checkStop m48 : 20|1@1+ (1,0) [0|1] "" GTW
 SG_ APP_sw048_ecuWatchdog m48 : 21|1@1+ (1,0) [0|1] "" GTW
 SG_ APP_sw048_ecuReset m48 : 22|1@1+ (1,0) [0|1] "" GTW
 SG_ APP_sw048_radcVersionMismatch m48 : 23|1@1+ (1,0) [0|1] "" GTW
 SG_ APP_sw048_radcCalibration m48 : 24|1@1+ (1,0) [0|1] "" GTW
 SG_ APP_sw048_radcMia m48 : 25|1@1+ (1,0) [0|1] "" GTW
 SG_ APP_sw048_eyeQVersionMismatch m48 : 26|1@1+ (1,0) [0|1] "" GTW
 SG_ APP_sw048_camIssue m48 : 27|1@1+ (1,0) [0|1] "" GTW
 SG_ APP_sw048_parkerIssue m48 : 28|1@1+ (1,0) [0|1] "" GTW
 SG_ APP_sw048_prolongedUiMia m48 : 29|1@1+ (1,0) [0|1] "" GTW
 SG_ APP_sw048_uiMiaAtBootup m48 : 30|1@1+ (1,0) [0|1] "" GTW
 SG_ APP_sw049_boot_version_msw m49 : 16|16@1+ (1,0) [0|0] "" GTW
 SG_ APP_sw049_app_version_msw m49 : 32|16@1+ (1,0) [0|0] "" GTW
 SG_ APP_sw049_ffs_version_msw m49 : 48|16@1+ (1,0) [0|0] "" GTW
 SG_ APP_sw050_targetDist m50 : 16|9@1+ (0.2,0) [0|102.2] "m" GTW
 SG_ APP_sw050_targetRelSpeed m50 : 25|9@1+ (0.0625,-31) [-31|0.9375] "m/s" GTW
 SG_ APP_sw050_targetOverlap m50 : 34|6@1+ (0.1,0) [0|6.3] "m" GTW
 SG_ APP_sw050_hostSpeed m50 : 40|8@1+ (1,0) [0|255] "kph" GTW
 SG_ APP_sw050_hostLongAccel m50 : 48|7@1+ (0.15625,-10) [-10|10] "m/s^2" GTW
 SG_ APP_sw050_driverPressedAccelPed m50 : 55|1@1+ (1,0) [0|1] "" GTW
 SG_ APP_sw050_driverPressedBrakePed m50 : 56|1@1+ (1,0) [0|1] "" GTW
 SG_ APP_sw050_aebEnable m50 : 57|1@1+ (1,0) [0|1] "" GTW
 SG_ APP_sw050_overrideBlinker m50 : 58|1@1+ (1,0) [0|1] "" GTW
 SG_ APP_sw050_overrideBrake m50 : 59|1@1+ (1,0) [0|1] "" GTW
 SG_ APP_sw050_overrideSteer m50 : 60|1@1+ (1,0) [0|1] "" GTW
 SG_ APP_sw050_fcmModeAtEvent m50 : 61|2@1+ (1,0) [0|3] "" GTW
 SG_ APP_sw050_accActive m50 : 63|1@1+ (1,0) [0|1] "" GTW
 SG_ APP_sw051_a01ecuInternalPerf m51 : 16|1@1+ (1,0) [0|1] "" GTW
 SG_ APP_sw051_a02flashPerformance m51 : 17|1@1+ (1,0) [0|1] "" GTW
 SG_ APP_sw051_a03vBatHigh m51 : 18|1@1+ (1,0) [0|1] "" GTW
 SG_ APP_sw051_a09configMismatch m51 : 19|1@1+ (1,0) [0|1] "" GTW
 SG_ APP_sw051_a52radomeHtrInop m51 : 20|1@1+ (1,0) [0|1] "" GTW
 SG_ APP_sw051_unused m51 : 21|3@1+ (1,0) [0|1] "" GTW
 SG_ APP_sw051_SCUTemperature m51 : 24|8@1- (1,0) [-128|127] "" GTW
 SG_ APP_sw051_HWFail m51 : 32|1@1+ (1,0) [0|1] "" GTW
 SG_ APP_sw051_SGUFail m51 : 33|1@1+ (1,0) [0|1] "" GTW
 SG_ APP_sw051_unusedBits m51 : 34|6@1+ (1,0) [0|1] "" GTW
 SG_ APP_sw051_unusedB0 m51 : 40|8@1+ (1,0) [0|1] "" GTW
 SG_ APP_sw051_unusedW1 m51 : 48|16@1+ (1,0) [0|1] "" GTW
 SG_ APP_sw052_a07sensorBlinded m52 : 16|1@1+ (1,0) [0|1] "" GTW
 SG_ APP_sw052_sensorDirty m52 : 17|1@1+ (1,0) [0|1] "" GTW
 SG_ APP_sw052_HWFail m52 : 18|1@1+ (1,0) [0|1] "" GTW
 SG_ APP_sw052_overTemperature m52 : 19|1@1+ (1,0) [0|1] "" GTW
 SG_ APP_sw052_underTemperature m52 : 20|1@1+ (1,0) [0|1] "" GTW
 SG_ APP_sw052_chirpError m52 : 21|1@1+ (1,0) [0|1] "" GTW
 SG_ APP_sw052_rspError m52 : 22|1@1+ (1,0) [0|1] "" GTW
 SG_ APP_sw052_sensorBlocked m52 : 23|1@1+ (1,0) [0|1] "" GTW
 SG_ APP_sw053_a10canBusOff m53 : 16|1@1+ (1,0) [0|1] "" GTW
 SG_ APP_sw053_a11bdyMIA m53 : 17|1@1+ (1,0) [0|1] "" GTW
 SG_ APP_sw053_a12espMIA m53 : 18|1@1+ (1,0) [0|1] "" GTW
 SG_ APP_sw053_a13gtwMIA m53 : 19|1@1+ (1,0) [0|1] "" GTW
 SG_ APP_sw053_a14sccmMIA m53 : 20|1@1+ (1,0) [0|1] "" GTW
 SG_ APP_sw053_a15adasMIA m53 : 21|1@1+ (1,0) [0|1] "" GTW
 SG_ APP_sw053_a16bdyInvalidCount m53 : 22|1@1+ (1,0) [0|1] "" GTW
 SG_ APP_sw053_a17adasInvalidCount m53 : 23|1@1+ (1,0) [0|1] "" GTW
 SG_ APP_sw053_a18espInvalidCount m53 : 24|1@1+ (1,0) [0|1] "" GTW
 SG_ APP_sw053_a19sccmInvalidCount m53 : 25|1@1+ (1,0) [0|1] "" GTW
 SG_ APP_sw053_a20bdyInvalidChkSm m53 : 26|1@1+ (1,0) [0|1] "" GTW
 SG_ APP_sw053_a21espInvalidChkSm m53 : 27|1@1+ (1,0) [0|1] "" GTW
 SG_ APP_sw053_a22sccmInvalidChkSm m53 : 28|1@1+ (1,0) [0|1] "" GTW
 SG_ APP_sw053_a23sccmInvalidChkSm m53 : 29|1@1+ (1,0) [0|1] "" GTW
 SG_ APP_sw053_a24absValidity m53 : 30|1@1+ (1,0) [0|1] "" GTW
 SG_ APP_sw053_a25ambTValidity m53 : 31|1@1+ (1,0) [0|1] "" GTW
 SG_ APP_sw053_a26brakeValidity m53 : 32|1@1+ (1,0) [0|1] "" GTW
 SG_ APP_sw053_a27CntryCdValidity m53 : 33|1@1+ (1,0) [0|1] "" GTW
 SG_ APP_sw053_a28espValidity m53 : 34|1@1+ (1,0) [0|0] "" GTW
 SG_ APP_sw053_a29longAccOffValidity m53 : 35|1@1+ (1,0) [0|1] "" GTW
 SG_ APP_sw053_a30longAccValidity m53 : 36|1@1+ (1,0) [0|1] "" GTW
 SG_ APP_sw053_a31odoValidity m53 : 37|1@1+ (1,0) [0|1] "" GTW
 SG_ APP_sw053_a32gearValidity m53 : 38|1@1+ (1,0) [0|1] "" GTW
 SG_ APP_sw053_a33steerAngValidity m53 : 39|1@1+ (1,0) [0|1] "" GTW
 SG_ APP_sw053_a34steerAngSpdValidity m53 : 40|1@1+ (1,0) [0|1] "" GTW
 SG_ APP_sw053_a35indctrValidity m53 : 41|1@1+ (1,0) [0|1] "" GTW
 SG_ APP_sw053_a36vehStndStllValidty m53 : 42|1@1+ (1,0) [0|1] "" GTW
 SG_ APP_sw053_a37vinValidity m53 : 43|1@1+ (1,0) [0|1] "" GTW
 SG_ APP_sw053_a38whlRotValidity m53 : 44|1@1+ (1,0) [0|1] "" GTW
 SG_ APP_sw053_a39whlSpdValidity m53 : 45|1@1+ (1,0) [0|1] "" GTW
 SG_ APP_sw053_a40whlStndStllValidty m53 : 46|1@1+ (1,0) [0|1] "" GTW
 SG_ APP_sw053_a41wiperValidity m53 : 47|1@1+ (1,0) [0|1] "" GTW
 SG_ APP_sw053_a42xwdValidity m53 : 48|1@1+ (1,0) [0|1] "" GTW
 SG_ APP_sw053_a43yawOffValidity m53 : 49|1@1+ (1,0) [0|1] "" GTW
 SG_ APP_sw053_a44yawValidity m53 : 50|1@1+ (1,0) [0|1] "" GTW
 SG_ APP_sw053_a48steerAngOffSanity m53 : 51|1@1+ (1,0) [0|1] "" GTW
 SG_ APP_sw053_a49tireSizeSanity m53 : 52|1@1+ (1,0) [0|1] "" GTW
 SG_ APP_sw053_a50velocitySanity m53 : 53|1@1+ (1,0) [0|1] "" GTW
 SG_ APP_sw053_a51yawSanity m53 : 54|1@1+ (1,0) [0|1] "" GTW
 SG_ APP_sw053_a53espmodValidity m53 : 55|1@1+ (1,0) [0|1] "" GTW
 SG_ APP_sw053_a54gtwmodValidity m53 : 56|1@1+ (1,0) [0|1] "" GTW
 SG_ APP_sw053_a55stwmodValidity m53 : 57|1@1+ (1,0) [0|1] "" GTW
 SG_ APP_sw053_a56bcmodValidity m53 : 58|1@1+ (1,0) [0|1] "" GTW
 SG_ APP_sw053_a57dimodValidity m53 : 59|1@1+ (1,0) [0|1] "" GTW
 SG_ APP_sw053_a59drmiInvalidChkSm m53 : 60|1@1+ (1,0) [0|1] "" GTW
 SG_ APP_sw053_a60drmiInvalidCount m53 : 61|1@1+ (1,0) [0|1] "" GTW
 SG_ APP_sw053_a61radPositionMismatch m53 : 62|1@1+ (1,0) [0|1] "" GTW
 SG_ APP_sw053_a62strRackMismatch m53 : 63|1@1+ (1,0) [0|1] "" GTW
 SG_ APP_sw054_Autofix_cnvrgnceStatus m54 : 16|8@1+ (1,0) [0|0] "" GTW
 SG_ APP_sw054_Autofix_horizon m54 : 24|8@1+ (1,0) [0|0] "" GTW
 SG_ APP_sw054_Autofix_yaw m54 : 32|8@1+ (1,0) [0|0] "" GTW
 SG_ APP_sw054_unusedByte m54 : 40|8@1+ (1,0) [0|0] "" GTW
 SG_ APP_sw054_unusedW0 m54 : 48|16@1+ (1,0) [0|0] "" GTW
 SG_ APP_sw055_detectedRadcVersion m55 : 16|32@1+ (1,0) [0|0] "" GTW
 SG_ APP_sw055_expectedCrcLsw m55 : 48|16@1+ (1,0) [0|0] "" GTW
 SG_ APP_sw056_diMia m56 : 16|8@1+ (1,0) [0|1] "" GTW
 SG_ APP_sw056_unusedByte m56 : 24|8@1+ (1,0) [0|0] "" GTW
 SG_ APP_sw056_espControl m56 : 32|1@1+ (1,0) [0|0] "" GTW
 SG_ APP_sw056_state2 m56 : 33|1@1+ (1,0) [0|0] "" GTW
 SG_ APP_sw056_state m56 : 34|1@1+ (1,0) [0|0] "" GTW
 SG_ APP_sw056_torque1 m56 : 35|1@1+ (1,0) [0|0] "" GTW
 SG_ APP_sw056_torque2 m56 : 36|1@1+ (1,0) [0|0] "" GTW
 SG_ APP_sw057_chCtrlMia m57 : 32|1@1+ (1,0) [0|1] "" GTW
 SG_ APP_sw057_csaOfframpCurvMia m57 : 33|1@1+ (1,0) [0|1] "" GTW
 SG_ APP_sw057_csaRoadCurvMia m57 : 34|1@1+ (1,0) [0|1] "" GTW
 SG_ APP_sw057_dasControlMia m57 : 35|1@1+ (1,0) [0|1] "" GTW
 SG_ APP_sw057_dasMapDataMia m57 : 36|1@1+ (1,0) [0|1] "" GTW
 SG_ APP_sw057_gpsVehSpeedMia m57 : 37|1@1+ (1,0) [0|1] "" GTW
 SG_ APP_sw057_locStatusMia m57 : 38|1@1+ (1,0) [0|1] "" GTW
 SG_ APP_sw057_radarMapDataMia m57 : 39|1@1+ (1,0) [0|1] "" GTW
 SG_ APP_sw057_roadCurvMia m57 : 40|1@1+ (1,0) [0|1] "" GTW
 SG_ APP_sw057_solarDataMia m57 : 41|1@1+ (1,0) [0|1] "" GTW
 SG_ APP_sw057_telemetryControlMia m57 : 42|1@1+ (1,0) [0|1] "" GTW
 SG_ APP_sw057_statusMia m57 : 43|1@1+ (1,0) [0|1] "" GTW
 SG_ APP_sw057_autopilotControlMia m57 : 44|1@1+ (1,0) [0|1] "" GTW
 SG_ APP_sw057_phoneLocStatusMia m57 : 45|1@1+ (1,0) [0|1] "" GTW
 SG_ APP_sw058_epbMia m58 : 16|8@1+ (1,0) [0|1] "" GTW
 SG_ APP_sw058_unusedByte m58 : 24|8@1+ (1,0) [0|0] "" GTW
 SG_ APP_sw058_status m58 : 32|1@1+ (1,0) [0|0] "" GTW
 SG_ APP_sw059_parkMia m59 : 16|8@1+ (1,0) [0|1] "" GTW
 SG_ APP_sw059_unusedByte m59 : 24|8@1+ (1,0) [0|0] "" GTW
 SG_ APP_sw059_oloDict m59 : 32|1@1+ (1,0) [0|0] "" GTW
 SG_ APP_sw059_oocStatus m59 : 33|1@1+ (1,0) [0|0] "" GTW
 SG_ APP_sw059_pasFrontMiddle m59 : 34|1@1+ (1,0) [0|0] "" GTW
 SG_ APP_sw059_pasRearMiddle m59 : 35|1@1+ (1,0) [0|0] "" GTW
 SG_ APP_sw059_pscStatus m59 : 36|1@1+ (1,0) [0|0] "" GTW
 SG_ APP_sw059_pscVehSlot m59 : 37|1@1+ (1,0) [0|0] "" GTW
 SG_ APP_sw059_sdiFront m59 : 38|1@1+ (1,0) [0|0] "" GTW
 SG_ APP_sw059_sdiRear m59 : 39|1@1+ (1,0) [0|0] "" GTW
 SG_ APP_sw059_sensorStatusFront m59 : 40|1@1+ (1,0) [0|0] "" GTW
 SG_ APP_sw059_sensorStatusRear m59 : 41|1@1+ (1,0) [0|0] "" GTW
 SG_ APP_sw059_status2 m59 : 42|1@1+ (1,0) [0|0] "" GTW
 SG_ APP_sw059_status m59 : 43|1@1+ (1,0) [0|0] "" GTW
 SG_ APP_sw060_targetDist m60 : 16|9@1+ (0.2,0) [0|102.2] "m" GTW
 SG_ APP_sw060_targetRelSpeed m60 : 25|9@1+ (0.0625,-31) [-31|0.9375] "m/s" GTW
 SG_ APP_sw060_targetOverlap m60 : 34|6@1+ (0.1,0) [0|6.3] "m" GTW
 SG_ APP_sw060_hostSpeed m60 : 40|7@1+ (2,0) [0|254] "kph" GTW
 SG_ APP_sw060_hostLongAccel m60 : 47|4@1+ (1,-7.5) [-7.5|7.5] "m/s^2" GTW
 SG_ APP_sw060_RadarAssociationAge m60 : 51|4@1+ (100,0) [0|1500] "ms" GTW
 SG_ APP_sw060_driverPressedBrakePed m60 : 55|1@1+ (1,0) [0|1] "" GTW
 SG_ APP_sw060_overrideAccelPed m60 : 56|1@1+ (1,0) [0|1] "" GTW
 SG_ APP_sw060_overrideBlinker m60 : 57|1@1+ (1,0) [0|1] "" GTW
 SG_ APP_sw060_overrideBrake m60 : 58|1@1+ (1,0) [0|1] "" GTW
 SG_ APP_sw060_overrideSteer m60 : 59|1@1+ (1,0) [0|1] "" GTW
 SG_ APP_sw060_collisionWarningSource m60 : 60|3@1+ (1,0) [0|7] "" GTW
 SG_ APP_sw060_accActive m60 : 63|1@1+ (1,0) [0|1] "" GTW
 SG_ APP_sw061_airSuspensionMia m61 : 16|8@1+ (1,0) [0|1] "" GTW
 SG_ APP_sw061_unusedByte m61 : 24|8@1+ (1,0) [0|0] "" GTW
 SG_ APP_sw061_asdA2 m61 : 32|1@1+ (1,0) [0|0] "" GTW
 SG_ APP_sw061_states m61 : 33|1@1+ (1,0) [0|0] "" GTW
 SG_ APP_sw062_HorizontalMisalignment m62 : 16|16@1+ (0.00137332,-45) [-45|45.0005262] "deg" GTW
 SG_ APP_sw062_VerticalMisalignment m62 : 32|10@1+ (0.087977,-45) [-45|45.000471] "deg" GTW
 SG_ APP_sw062_unusedBits m62 : 42|6@1+ (1,0) [0|1] "" GTW
 SG_ APP_sw062_VmaPlausibility m62 : 48|16@1+ (1.52587890625005E-05,0) [0|0.99998474121097] "" GTW
 SG_ APP_sw063_expectedMajorVer m63 : 16|8@1+ (1,0) [0|255] "" GTW
 SG_ APP_sw063_detectedMajorVer m63 : 24|8@1+ (1,0) [0|255] "" GTW
 SG_ APP_sw063_expectedMinorVer m63 : 32|8@1+ (1,0) [0|255] "" GTW
 SG_ APP_sw063_detectedMinorVer m63 : 40|8@1+ (1,0) [0|255] "" GTW
 SG_ APP_sw063_expectedSubMinorVer m63 : 48|8@1+ (1,0) [0|255] "" GTW
 SG_ APP_sw063_detectedSubMinorVer m63 : 56|8@1+ (1,0) [0|255] "" GTW
 SG_ APP_sw064_epasMia m64 : 16|8@1+ (1,0) [0|1] "" GTW
 SG_ APP_sw064_unusedByte m64 : 24|8@1+ (1,0) [0|0] "" GTW
 SG_ APP_sw064_sysStatus m64 : 32|1@1+ (1,0) [0|0] "" GTW
 SG_ APP_sw065_app_mobileye_status m65 : 16|8@1+ (1,0) [0|21] "" GTW
 SG_ APP_sw065_mobileye_main_state m65 : 24|8@1+ (1,0) [0|255] "" GTW
 SG_ APP_sw065_unusedW0 m65 : 32|16@1+ (1,0) [0|0] "" GTW
 SG_ APP_sw065_unusedW1 m65 : 48|16@1+ (1,0) [0|0] "" GTW
 SG_ APP_sw066_app_mobileye_status m66 : 16|8@1+ (1,0) [0|21] "" GTW
 SG_ APP_sw066_mobileye_main_state m66 : 24|8@1+ (1,0) [0|255] "" GTW
 SG_ APP_sw066_unusedW0 m66 : 32|16@1+ (1,0) [0|0] "" GTW
 SG_ APP_sw066_unusedW1 m66 : 48|16@1+ (1,0) [0|0] "" GTW
 SG_ APP_sw067_sccmSTW m67 : 16|14@1+ (0.1,-819.2) [-819.2|819] "deg" GTW
 SG_ APP_sw067_epasSTW m67 : 30|14@1+ (0.1,-819.2) [-819.2|819] "deg" GTW
 SG_ APP_sw067_vehSpeed m67 : 44|12@1+ (0.1,-50) [-50|359.6] "kph" GTW
 SG_ APP_sw067_offsetEstimator m67 : 56|8@1+ (0.1,-12.8) [-12.8|12.8] "deg" GTW
 SG_ APP_sw068_percentConsistency m68 : 16|10@1+ (0.1,0) [0|100] "%" GTW
 SG_ APP_sw068_virtualLaneSTW m68 : 32|14@1+ (0.1,-819.2) [-819.2|819.2] "deg" GTW
 SG_ APP_sw068_navigationSTW m68 : 48|14@1+ (0.1,-819.2) [-819.2|819.2] "deg" GTW
 SG_ APP_sw069_epasMia m69 : 16|1@1+ (1,0) [0|1] "" GTW
 SG_ APP_sw069_espMia m69 : 17|1@1+ (1,0) [0|1] "" GTW
 SG_ APP_sw069_parkMia m69 : 18|1@1+ (1,0) [0|1] "" GTW
 SG_ APP_sw069_sccmMia m69 : 19|1@1+ (1,0) [0|1] "" GTW
 SG_ APP_sw069_parkMismatch m69 : 20|1@1+ (1,0) [0|1] "" GTW
 SG_ APP_sw069_eacStatus m69 : 21|4@1+ (1,0) [0|1] "" GTW
 SG_ APP_sw069_diAPState m69 : 25|4@1+ (1,0) [0|1] "" GTW
 SG_ APP_sw069_parkCal m69 : 29|1@1+ (1,0) [0|1] "" GTW
 SG_ APP_sw069_torsionBar m69 : 32|12@1+ (0.01,-20.5) [-20.5|20.45] "Nm" GTW
 SG_ APP_sw069_roadClass m69 : 44|4@1+ (1,0) [0|15] "" GTW
 SG_ APP_sw069_drivingLaneLeft m69 : 48|8@1+ (1,0) [0|255] "" GTW
 SG_ APP_sw069_drivingLaneRight m69 : 56|8@1+ (1,0) [0|255] "" GTW
 SG_ APP_sw070_currTireFitment m70 : 16|3@1+ (1,0) [0|7] "" GTW
 SG_ APP_sw070_lastTireFitment m70 : 19|3@1+ (1,0) [0|7] "" GTW
 SG_ APP_sw070_diGear m70 : 22|3@1+ (1,0) [0|7] "" GTW
 SG_ APP_sw070_driveRail m70 : 25|1@1+ (1,0) [0|1] "" GTW
 SG_ APP_sw070_accRail m70 : 26|1@1+ (1,0) [0|1] "" GTW
 SG_ APP_sw070_temperature m70 : 32|8@1+ (0.5,-40) [-40|87.5] "C" GTW
 SG_ APP_sw070_currentSpeed m70 : 40|12@1+ (0.1,-204.7) [-204.7|204.8] "mph" GTW
 SG_ APP_sw071_selfParkType m71 : 16|4@1+ (1,0) [0|15] "" GTW
 SG_ APP_sw071_endPosX m71 : 20|10@1+ (0.05,-25.6) [-25.6|25.5] "m" GTW
 SG_ APP_sw071_endPosY m71 : 30|10@1+ (0.05,-25.6) [-25.6|25.5] "m" GTW
 SG_ APP_sw071_roadClass m71 : 40|3@1+ (1,0) [0|7] "" GTW
 SG_ APP_sw071_driverPresent m71 : 43|1@1+ (1,0) [0|1] "" GTW
 SG_ APP_sw071_airSuspension m71 : 44|3@1+ (1,0) [0|7] "" GTW
 SG_ APP_sw071_temperature m71 : 47|8@1+ (0.5,-40) [-40|87.5] "C" GTW
 SG_ APP_sw071_activationType m71 : 55|2@1+ (1,0) [0|3] "" GTW
 SG_ APP_sw072_vehicleX m72 : 16|10@1+ (0.05,-25.6) [-25.6|25.5] "m" GTW
 SG_ APP_sw072_vehicleY m72 : 26|10@1+ (0.05,-25.6) [-25.6|25.5] "m" GTW
 SG_ APP_sw072_vehicleHeading m72 : 36|10@1+ (0.005,-2.56) [-2.56|2.55] "rad" GTW
 SG_ APP_sw072_endDistance m72 : 46|8@1+ (1,0) [0|255] "cm" GTW
 SG_ APP_sw072_guidanceComplete m72 : 54|1@1+ (1,0) [0|1] "" GTW
 SG_ APP_sw072_guidanceRunaway m72 : 55|1@1+ (1,0) [0|1] "" GTW
 SG_ APP_sw072_guidanceTimer m72 : 56|1@1+ (1,0) [0|1] "" GTW
 SG_ APP_sw072_handlePress m72 : 57|1@1+ (1,0) [0|1] "" GTW
 SG_ APP_sw072_keyfobPress m72 : 58|1@1+ (1,0) [0|1] "" GTW
 SG_ APP_sw072_garageOpened m72 : 59|1@1+ (1,0) [0|1] "" GTW
 SG_ APP_sw072_userTimeout m72 : 60|1@1+ (1,0) [0|1] "" GTW
 SG_ APP_sw073_escalateLDWs m73 : 16|1@1+ (1,0) [0|1] "" GTW
 SG_ APP_sw073_silentEscalatedLDW m73 : 17|1@1+ (1,0) [0|1] "" GTW
 SG_ APP_sw073_escalateLDWreason m73 : 18|2@1+ (1,0) [0|3] "" GTW
 SG_ APP_sw073_rawMobileyeLDW m73 : 20|2@1+ (1,0) [0|3] "" GTW
 SG_ APP_sw073_freespaceLDW m73 : 22|2@1+ (1,0) [0|3] "" GTW
 SG_ APP_sw073_freespaceLeftC0 m73 : 24|8@1+ (0.1,-12.8) [-12.8|12.7] "m" GTW
 SG_ APP_sw073_freespaceRightC0 m73 : 32|8@1+ (0.1,-12.8) [-12.8|12.7] "m" GTW
 SG_ APP_sw073_freespaceLeftC1 m73 : 40|8@1+ (0.0016,-0.2) [-0.2|0.2] "rad" GTW
 SG_ APP_sw073_freespaceRightC1 m73 : 48|8@1+ (0.0016,-0.2) [-0.2|0.2] "rad" GTW
 SG_ APP_sw073_freespaceLeftFarZ m73 : 56|4@1+ (4,0) [0|60] "m" GTW
 SG_ APP_sw073_freespaceRightFarZ m73 : 60|4@1+ (4,0) [0|60] "m" GTW
 SG_ APP_sw074_ipsoDx m74 : 16|6@1+ (2,0) [0|126] "m" GTW
 SG_ APP_sw074_ipsoDy m74 : 22|6@1+ (0.1,-3.2) [-3.2|3.1] "m" GTW
 SG_ APP_sw074_ipsoDz m74 : 28|6@1+ (0.2,-6.4) [-6.4|6.2] "m" GTW
 SG_ APP_sw074_ipsoRCS m74 : 34|8@1+ (1,0) [0|255] "db" GTW
 SG_ APP_sw074_ipsoConfidence m74 : 42|6@1+ (2,0) [0|126] "percent" GTW
 SG_ APP_sw074_ipsowExist m74 : 48|5@1+ (1,0) [0|31] "" GTW
 SG_ APP_sw074_roadClass m74 : 54|3@1+ (1,0) [0|7] "" GTW
 SG_ APP_sw074_cruiseActive m74 : 57|1@1+ (1,0) [0|1] "" GTW
 SG_ APP_sw074_autopilotActive m74 : 58|1@1+ (1,0) [0|1] "" GTW
 SG_ APP_sw075_scMia m75 : 16|8@1+ (1,0) [0|255] "" GTW
 SG_ APP_sw075_unusedByte m75 : 24|8@1+ (1,0) [0|0] "" GTW
 SG_ APP_sw075_status m75 : 32|1@1+ (1,0) [0|0] "" GTW
 SG_ APP_sw076_targetDist m76 : 16|9@1+ (0.2,0) [0|102.2] "m" GTW
 SG_ APP_sw076_targetRelSpeed m76 : 25|9@1+ (0.0625,-31) [-31|0.9375] "m/s" GTW
 SG_ APP_sw076_targetOverlap m76 : 34|6@1+ (0.1,0) [0|6.3] "m" GTW
 SG_ APP_sw076_hostSpeed m76 : 40|8@1+ (1,0) [0|255] "kph" GTW
 SG_ APP_sw076_hostLongAccel m76 : 48|7@1+ (0.15625,-10) [-10|10] "m/s^2" GTW
 SG_ APP_sw076_driverPressedAccelPed m76 : 55|1@1+ (1,0) [0|1] "" GTW
 SG_ APP_sw076_driverPressedBrakePed m76 : 56|1@1+ (1,0) [0|1] "" GTW
 SG_ APP_sw076_overrideAccelPed m76 : 57|1@1+ (1,0) [0|1] "" GTW
 SG_ APP_sw076_overrideBlinker m76 : 58|1@1+ (1,0) [0|1] "" GTW
 SG_ APP_sw076_overrideBrake m76 : 59|1@1+ (1,0) [0|1] "" GTW
 SG_ APP_sw076_overrideSteer m76 : 60|1@1+ (1,0) [0|1] "" GTW
 SG_ APP_sw076_fcmModeAtEvent m76 : 61|2@1+ (1,0) [0|3] "" GTW
 SG_ APP_sw076_accActive m76 : 63|1@1+ (1,0) [0|1] "" GTW
 SG_ APP_sw077_oocDistance m77 : 16|9@1+ (1,0) [0|512] "cm" GTW
 SG_ APP_sw077_oocConfidence m77 : 25|7@1+ (1,0) [0|100] "%" GTW
 SG_ APP_sw077_oocCollisionSide m77 : 32|3@1+ (1,0) [0|7] "" GTW
 SG_ APP_sw077_oocHeight m77 : 35|2@1+ (1,0) [0|4] "" GTW
 SG_ APP_sw077_vehicleSpeed m77 : 37|10@1+ (0.05,-25) [-25|26.15] "MPH" GTW
 SG_ APP_sw077_oocUntrackedTime m77 : 48|6@1+ (0.1,0) [0|6.3] "s" GTW
 SG_ APP_sw077_oocOffCourseDist_cm m77 : 54|10@1- (1,0) [-512|511] "" GTW
 SG_ APP_sw078_camCipv_dx m78 : 16|8@1+ (0.2,0) [0|51] "m" GTW
 SG_ APP_sw078_ttc m78 : 24|8@1+ (0.02,0) [0|5.11] "seconds" GTW
 SG_ APP_sw078_radarTarg5_dx m78 : 32|8@1+ (0.0625,0) [0|15.9375] "m" GTW
 SG_ APP_sw078_radarTarg5_VxRel m78 : 40|8@1+ (0.2,-25.6) [-25.6|25.4] "m/s" GTW
 SG_ APP_sw078_radarTarg1_dx m78 : 48|8@1+ (0.0625,0) [0|15.9375] "m" GTW
 SG_ APP_sw078_radarTarg1_VxRel m78 : 56|8@1+ (0.2,-25.6) [-25.6|25.4] "m/s" GTW
 SG_ APP_sw080_sensors_healty_check m80 : 16|1@1+ (1,0) [0|1] "" GTW
 SG_ APP_sw080_dist_travelled_check m80 : 17|1@1+ (1,0) [0|1] "" GTW
 SG_ APP_sw080_road_class_check m80 : 18|1@1+ (1,0) [0|1] "" GTW
 SG_ APP_sw080_stw_angle_check m80 : 19|1@1+ (1,0) [0|1] "" GTW
 SG_ APP_sw080_rad_tar_5_check m80 : 20|1@1+ (1,0) [0|1] "" GTW
 SG_ APP_sw080_ultrasonic_obs_check m80 : 21|1@1+ (1,0) [0|1] "" GTW
 SG_ APP_sw080_freespace_check m80 : 22|1@1+ (1,0) [0|1] "" GTW
 SG_ APP_sw080_pedestrian_check m80 : 23|1@1+ (1,0) [0|1] "" GTW
 SG_ APP_sw080_rad_tar_5_dist m80 : 24|6@1+ (1,0) [0|63] "m" GTW
 SG_ APP_sw080_stw_angle_deg m80 : 32|8@1+ (1,0) [0|255] "deg" GTW
 SG_ APP_sw080_road_class m80 : 40|3@1+ (1,0) [0|7] "" GTW
 SG_ APP_sw080_ego_speed m80 : 43|5@1+ (1,0) [0|31] "mph" GTW
 SG_ APP_sw080_cipv_valid m80 : 48|1@1+ (1,0) [0|1] "" GTW
 SG_ APP_sw080_min_speed_check m80 : 49|1@1+ (1,0) [0|1] "" GTW
 SG_ APP_sw080_cruise_lever_state m80 : 50|3@1+ (1,0) [0|7] "" GTW
 SG_ APP_sw080_cruise_speed_check m80 : 53|1@1+ (1,0) [0|1] "" GTW
 SG_ APP_sw081_radarDistance m81 : 16|8@1+ (0.0625,0) [0|15.9375] "m" GTW
 SG_ APP_sw081_radarTTC m81 : 24|8@1+ (0.02,0) [0|5.11] "seconds" GTW
 SG_ APP_sw081_cameraDistance m81 : 32|8@1+ (0.0625,0) [0|15.9375] "m" GTW
 SG_ APP_sw081_cameraTTC m81 : 40|8@1+ (0.02,0) [0|5.11] "seconds" GTW
 SG_ APP_sw081_pedalPosition m81 : 48|7@1+ (1,0) [0|127] "%" GTW
 SG_ APP_sw082_L_VL m82 : 16|8@1+ (0.05,-6.4) [-6.4|6.35] "m" GTW
 SG_ APP_sw082_R_VL m82 : 24|8@1+ (0.05,-6.4) [-6.4|6.35] "m" GTW
 SG_ APP_sw082_L_Lane m82 : 32|8@1+ (0.05,-6.4) [-6.4|6.35] "m" GTW
 SG_ APP_sw082_R_Lane m82 : 40|8@1+ (0.05,-6.4) [-6.4|6.35] "m" GTW
 SG_ APP_sw082_road_class m82 : 48|3@1+ (1,0) [0|7] "" GTW
 SG_ APP_sw083_Targ5_RCS m83 : 16|16@1+ (0.0039063096,0) [0|256] "dB" GTW
 SG_ APP_sw083_Targ5_dx m83 : 32|12@1+ (0.0625,0) [0|255.9375] "m" GTW
 SG_ APP_sw083_Targ5_dz m83 : 44|6@1+ (0.25,-5) [-5|10.75] "m" GTW
 SG_ APP_sw083_Targ5_wObj m83 : 50|5@1+ (0.03125,0) [0|0.96875] "%" GTW
 SG_ APP_sw083_Targ5_wNonObj m83 : 55|5@1+ (0.03125,0) [0|0.96875] "%" GTW
 SG_ APP_sw084_ipsoTTC m84 : 16|8@1+ (0.02,0) [0|5.11] "seconds" GTW
 SG_ APP_sw084_ipsoDx m84 : 24|8@1+ (0.1,0) [0|25.5] "m" GTW
 SG_ APP_sw084_ipsoRCS m84 : 32|8@1+ (1,0) [0|255] "" GTW
 SG_ APP_sw084_ipsoDy m84 : 40|8@1+ (0.1,-12.6) [-12.6|12.8] "m" GTW
 SG_ APP_sw085_radarDistance m85 : 16|8@1+ (0.0625,0) [0|15.9375] "m" GTW
 SG_ APP_sw085_radarTTC m85 : 24|8@1+ (0.02,0) [0|5.11] "seconds" GTW
 SG_ APP_sw085_roadClass m85 : 32|3@1+ (1,0) [0|7] "" GTW
 SG_ APP_sw085_leftLaneExist m85 : 36|6@1+ (2,0) [0|128] "%" GTW
 SG_ APP_sw085_rightLaneExist m85 : 42|6@1+ (2,0) [0|128] "%" GTW
 SG_ APP_sw085_averageSpeedHist m85 : 48|6@1+ (0.25,0) [0|16] "mps" GTW
 SG_ APP_sw085_freeSpaceC0Left m85 : 54|5@1+ (1,-15) [-15|16] "m" GTW
 SG_ APP_sw085_freeSpaceC0Right m85 : 59|5@1+ (1,-15) [-15|16] "m" GTW
 SG_ APP_sw086_distanceException m86 : 16|8@1+ (1,-90) [90|165] "m" GTW
 SG_ APP_sw086_distanceEllipse m86 : 24|8@1+ (0.5,0) [0|127.5] "m" GTW
 SG_ APP_sw086_ellipseWidth m86 : 32|8@1+ (0.1,0) [0|25.5] "m" GTW
 SG_ APP_sw086_ellipseOverlap m86 : 40|8@1+ (0.1,-12.5) [-12.5|12.5] "m" GTW
 SG_ APP_sw086_ellipseAge m86 : 48|3@1+ (1,0) [0|7] "" GTW
 SG_ APP_sw086_activeBraking m86 : 51|1@1+ (1,0) [0|1] "" GTW
 SG_ APP_sw086_cipvValid m86 : 52|1@1+ (1,0) [0|1] "" GTW
 SG_ APP_sw086_mcvlValid m86 : 53|1@1+ (1,0) [0|1] "" GTW
 SG_ APP_sw086_mcvrValid m86 : 54|1@1+ (1,0) [0|1] "" GTW
 SG_ APP_sw086_roadClass m86 : 55|3@1+ (1,0) [0|7] "" GTW
 SG_ APP_sw086_ipsoApproved m86 : 58|1@1+ (1,0) [0|1] "" GTW
 SG_ APP_sw086_controlledAccess m86 : 59|1@1+ (1,0) [0|1] "" GTW
 SG_ APP_sw086_driverHandsOn m86 : 60|1@1+ (1,0) [0|1] "" GTW
 SG_ APP_sw103_objectDx m103 : 16|8@1+ (0.5,0) [0|127.5] "m" GTW
 SG_ APP_sw103_objectRCS m103 : 24|8@1+ (1,0) [0|255] "" GTW
 SG_ APP_sw103_objectDy m103 : 32|8@1+ (0.5,-15.5) [-15.5|16] "m" GTW
 SG_ APP_sw103_objectDz m103 : 40|8@1+ (0.25,-5) [-5|10.75] "m" GTW
 SG_ APP_sw103_distanceEllipse m103 : 48|8@1+ (0.5,0) [0|127.5] "m" GTW
 SG_ APP_sw103_ipsoApproved m103 : 56|1@1+ (1,0) [0|1] "" GTW
 SG_ APP_sw103_constArea m103 : 57|2@1+ (1,0) [0|3] "" GTW
 SG_ APP_sw103_radAlignment m103 : 59|5@1+ (0.015625,-0.2343) [-0.2343|0.25] "rad" GTW
 SG_ APP_sw106_torsionBarOffset m106 : 16|8@1+ (0.005,-0.64) [-0.64|0.63] "Nm" GTW
 SG_ APP_sw129_mainCamExtNoCalFile m129 : 16|1@1+ (1,0) [0|1] "" GTW,MCU
 SG_ APP_sw129_unusedW0 m129 : 32|16@1+ (1,0) [0|0] "" GTW
 SG_ APP_sw129_unusedW1 m129 : 48|16@1+ (1,0) [0|0] "" GTW
 SG_ APP_sw130_narrowCamExtNoCalFile m130 : 16|1@1+ (1,0) [0|1] "" GTW,MCU
 SG_ APP_sw130_unusedW0 m130 : 32|16@1+ (1,0) [0|0] "" GTW
 SG_ APP_sw130_unusedW1 m130 : 48|16@1+ (1,0) [0|0] "" GTW
 SG_ APP_sw131_mainCamExtPitchCal m131 : 16|9@1- (0.05,0) [-12.5|12.5] "deg" GTW
 SG_ APP_sw131_mainCamExtYawCal m131 : 25|9@1- (0.05,0) [-12.5|12.5] "deg" GTW
 SG_ APP_sw131_mainCamExtRollCal m131 : 34|9@1- (0.05,0) [-12.5|12.5] "deg" GTW
 SG_ APP_sw132_narrowCamExtPitchCal m132 : 16|9@1- (0.05,0) [-12.5|12.5] "deg" GTW
 SG_ APP_sw132_narrowCamExtYawCal m132 : 25|9@1- (0.05,0) [-12.5|12.5] "deg" GTW
 SG_ APP_sw132_narrowCamExtRollCal m132 : 34|9@1- (0.05,0) [-12.5|12.5] "deg" GTW
 SG_ APP_sw133_mainCamI2CbusFault m133 : 16|1@1+ (1,0) [0|1] "" GTW
 SG_ APP_sw133_mainCamDeserFault m133 : 17|3@1+ (1,0) [0|7] "" GTW
 SG_ APP_sw133_mainCamSerFault m133 : 21|3@1+ (1,0) [0|7] "" GTW
 SG_ APP_sw133_mainCamSensorFault m133 : 24|3@1+ (1,0) [0|7] "" GTW
 SG_ APP_sw134_narrowCamI2CbusFault m134 : 16|1@1+ (1,0) [0|1] "" GTW
 SG_ APP_sw134_narrowCamDeserFault m134 : 17|3@1+ (1,0) [0|7] "" GTW
 SG_ APP_sw134_narrowCamSerFault m134 : 21|3@1+ (1,0) [0|7] "" GTW
 SG_ APP_sw134_narrowCamSensorFault m134 : 24|3@1+ (1,0) [0|7] "" GTW
 SG_ APP_sw135_fisheyeCamI2CbusFault m135 : 16|1@1+ (1,0) [0|1] "" GTW
 SG_ APP_sw135_fisheyeCamDeserFault m135 : 17|3@1+ (1,0) [0|7] "" GTW
 SG_ APP_sw135_fisheyeCamSerFault m135 : 21|3@1+ (1,0) [0|7] "" GTW
 SG_ APP_sw135_fisheyeCamSensorFault m135 : 24|3@1+ (1,0) [0|7] "" GTW
 SG_ APP_sw136_lPillarCamI2CbusFault m136 : 16|1@1+ (1,0) [0|1] "" GTW
 SG_ APP_sw136_lPillarCamDeserFault m136 : 17|3@1+ (1,0) [0|7] "" GTW
 SG_ APP_sw136_lPillarCamSerFault m136 : 21|3@1+ (1,0) [0|7] "" GTW
 SG_ APP_sw136_lPillarCamSensorFault m136 : 24|3@1+ (1,0) [0|7] "" GTW
 SG_ APP_sw137_rPillarCamI2CbusFault m137 : 16|1@1+ (1,0) [0|1] "" GTW
 SG_ APP_sw137_rPillarCamDeserFault m137 : 17|3@1+ (1,0) [0|7] "" GTW
 SG_ APP_sw137_rPillarCamSerFault m137 : 21|3@1+ (1,0) [0|7] "" GTW
 SG_ APP_sw137_rPillarCamSensorFault m137 : 24|3@1+ (1,0) [0|7] "" GTW
 SG_ APP_sw138_lRepeatCamI2CbusFault m138 : 16|1@1+ (1,0) [0|1] "" GTW
 SG_ APP_sw138_lRepeatCamDeserFault m138 : 17|3@1+ (1,0) [0|7] "" GTW
 SG_ APP_sw138_lRepeatCamSerFault m138 : 21|3@1+ (1,0) [0|7] "" GTW
 SG_ APP_sw138_lRepeatCamSensorFault m138 : 24|3@1+ (1,0) [0|7] "" GTW
 SG_ APP_sw139_rRepeatCamI2CbusFault m139 : 16|1@1+ (1,0) [0|1] "" GTW
 SG_ APP_sw139_rRepeatCamDeserFault m139 : 17|3@1+ (1,0) [0|7] "" GTW
 SG_ APP_sw139_rRepeatCamSerFault m139 : 21|3@1+ (1,0) [0|7] "" GTW
 SG_ APP_sw139_rRepeatCamSensorFault m139 : 24|3@1+ (1,0) [0|7] "" GTW
 SG_ APP_sw140_backupCamUARTbusFault m140 : 16|1@1+ (1,0) [0|1] "" GTW
 SG_ APP_sw140_backupCamDeserFault m140 : 17|3@1+ (1,0) [0|7] "" GTW
 SG_ APP_sw140_backupCamI2CbusFault m140 : 20|1@1+ (1,0) [0|1] "" GTW
 SG_ APP_sw140_backupCamCSIBridgeFlt m140 : 21|3@1+ (1,0) [0|7] "" GTW
 SG_ APP_sw140_backupCamSensorFault m140 : 24|3@1+ (1,0) [0|7] "" GTW
 SG_ APP_sw140_backupCamSXDeserFailed m140 : 27|1@1+ (1,0) [0|1] "" GTW
 SG_ APP_sw140_backupCamDeserLock m140 : 28|2@1+ (1,0) [0|2] "" GTW
 SG_ APP_sw140_backupCamSerFault m140 : 30|3@1+ (1,0) [0|7] "" GTW
 SG_ APP_sw140_backupCamSpBrdInitFail m140 : 33|1@1+ (1,0) [0|1] "" GTW
 SG_ APP_sw140_backupCamHDMISerFault m140 : 34|1@1+ (1,0) [0|1] "" GTW
 SG_ APP_sw141_tempSensorId m141 : 16|8@1+ (1,0) [0|4] "" GTW
 SG_ APP_sw141_minThreshold m141 : 24|8@1- (1,0) [-128|127] "degC" GTW
 SG_ APP_sw141_maxThreshold m141 : 32|8@1- (1,0) [-128|127] "degC" GTW
 SG_ APP_sw141_temperature m141 : 40|8@1- (1,0) [-128|127] "degC" GTW
 SG_ APP_sw142_pitchOffsetAtmptVal m142 : 16|9@1+ (1,-256) [-256|255] "pixels" GTW
 SG_ APP_sw142_camExtPitchCal m142 : 25|9@1+ (0.05,-12.5) [-12.5|12.5] "deg" GTW
 SG_ APP_sw142_problemCamPosition m142 : 34|4@1+ (1,0) [0|9] "" GTW
 SG_ APP_sw142_unused1 m142 : 38|26@1+ (1,0) [0|0] "" GTW
 SG_ APP_sw143_timeToImpact m143 : 16|9@1+ (1,0) [0|511] "ms" GTW
 SG_ APP_sw143_predImpactVelocity m143 : 25|7@1+ (0.5,0) [0|63.5] "m/s" GTW
 SG_ APP_sw143_targetDistance m143 : 32|7@1+ (0.1,0) [0|12.7] "m" GTW
 SG_ APP_sw143_targetRelVelocity m143 : 39|6@1+ (0.5,0) [0|31.5] "m/s" GTW
 SG_ APP_sw143_targetRelAcceleration m143 : 45|8@1+ (0.1,-12.8) [-12.8|12.7] "m/s2" GTW
 SG_ APP_sw143_targetIsACar m143 : 53|1@1+ (1,0) [0|0] "" GTW
 SG_ APP_sw143_egoVehicleSpeed m143 : 54|5@1+ (5,0) [0|155] "kph" GTW
 SG_ APP_sw143_steeringOverride m143 : 59|1@1+ (1,0) [0|1] "kph" GTW
 SG_ APP_sw143_predOverlap m143 : 60|4@1+ (10,0) [0|150] "%" GTW

CM_ "Chassis CAN";
CM_ BU_ APB "Autopilot Backup ECU";
CM_ BU_ APP "Autopilot Primary ECU";
CM_ BU_ APS "Autopilot Secondary ECU";
CM_ BU_ EPAS "Electronic Power Assisted Steering";
CM_ BU_ IBST "iBooster - Electric brake assist module.";
CM_ BU_ IC "Instrument Cluster";
CM_ BU_ MCU "Media Control Unit - not on CH bus but needed as receiver for autogeneration tools";
CM_ BU_ OCS "Occupant Classification System";
CM_ BU_ SCCM "Steering Column Control Module";
CM_ BU_ SEC "Security Controller";
CM_ BU_ TAS "Tesla Air Suspension Controller";
CM_ BU_ TAS2DBG "Tesla Adaptive Suspension Controller Debug";
CM_ BU_ TPMS "Tire Pressure Management System";
CM_ SG_ 543 ALDW_MsgDisp_Rq "ALDW message display request";
CM_ SG_ 543 ALDW_Menu_Enbl_Rq "ALDW menu enable request";
CM_ SG_ 543 ALDW_IndLmp_On_Rq "ALDW indication lamp on request";
CM_ SG_ 543 ALDW_PulseTm_Rq "ALDW pulse time request";
CM_ SG_ 543 ALDW_Warn_Rq "ALDW warning request";
CM_ SG_ 543 ALDW_VibTm_Rq "ALDW vibration time request";
CM_ SG_ 543 ALDW_LaneMarkWidth_Lt "ALDW lane marking width left";
CM_ SG_ 543 ALDW_WarnMd_Rq "ALDW warning mode request";
CM_ SG_ 543 ALDW_LaneMarkWidth_Rt "ALDW lane marking width right";
CM_ SG_ 543 ALDW_OnCal_Stat "ALDW online calibration state";
CM_ SG_ 543 ALDW_OnCalExecDist "ALDW online calibration execution distance";
CM_ SG_ 543 ALDW_BrkMsgDisp_Rq "ALDW brake message display request";
CM_ SG_ 543 ALDW_LaneMark_DtctDist "ALDW detection distance of lane marking detection";
CM_ SG_ 543 ALDW_ImgSyncNum "ALDW image synchronisation number";
CM_ SG_ 543 MC_ALDW_A1 "Message counter";
CM_ SG_ 543 CRC_ALDW_A1 "CRC-checksum byte 1 to 7 according to SAE J1850";
CM_ SG_ 1572 APPL_SG_SCCM "External application to ECU";
CM_ SG_ 1513 APP_sw019_numFreeBytes "A positive value denotes the number of bytes remaining in the stack before it will overflow. A negative value indicates that the stack has overflown by those many bytes. Any overflow beyond 191 bytes is snapped back and reported as -191 byte overflow.";
CM_ SG_ 1513 APP_sw019_timeStamp "Time stamp in milliseconds after the ECU health monitor gets initialized.";
CM_ SG_ 1513 APP_sw027_Clock_Monitor_0_Low "External crystal oscillator, PLL 0 or Internal RC oscillator  under the rated frequency limits.";
CM_ SG_ 1513 APP_sw027_Clock_Monitor_0_Off "External crystal oscillator, PLL 0 or Internal RC oscillator either over or under the rated frequency limits.";
CM_ SG_ 1513 APP_sw027_f_PLL_1_Off "PLL 1 frequency over or under allowable limits.";

BA_DEF_ "Baudrate" INT 0 1000000;
BA_DEF_ "BusID" INT 0 255;
BA_DEF_ "BusType" STRING ;
BA_DEF_ "DBName" STRING ;
BA_DEF_ "Manufacturer" STRING ;
BA_DEF_ "NBTMax" INT 0 255;
BA_DEF_ "NBTMin" INT 0 255;
BA_DEF_ "NWID" HEX 0 255;
BA_DEF_ "NWMTyp" ENUM "zentral (MB-W210)","dezentral (MB-OSAN)","keines","VAG-OSEK","BMW-OSEK","PAG-OSEK","DBAG-OSEK";
BA_DEF_ "NetworkName" STRING ;
BA_DEF_ "NmBaseAddress" INT 0 0;
BA_DEF_ "NmMessageCount" INT 0 64;
BA_DEF_ "NmType" STRING ;
BA_DEF_ "PektronFilterBits" INT 0 0;
BA_DEF_ "PektronNSamples" INT 0 0;
BA_DEF_ "PektronPhaseSeg1" INT 0 0;
BA_DEF_ "PektronPhaseSeg2" INT 0 0;
BA_DEF_ "PektronPrescale" INT 0 0;
BA_DEF_ "PektronPriorityBits" INT 0 0;
BA_DEF_ "PektronPropSeg" INT 0 0;
BA_DEF_ "PektronProtocol" STRING ;
BA_DEF_ "PektronSJW" INT 0 0;
BA_DEF_ "SamplePointMax" FLOAT 0 100;
BA_DEF_ "SamplePointMin" FLOAT 0 100;
BA_DEF_ "Version" HEX 0 255;
BA_DEF_ "VersionWeek" INT 0 53;
BA_DEF_ "VersionYear" INT 0 99;
BA_DEF_ BO_ "AlertLogSubSystemId" INT 0 0;
BA_DEF_ BO_ "AlertType" INT 0 4;
BA_DEF_ BO_ "AppBotschaft" ENUM "nein","ja";
BA_DEF_ BO_ "DiagRequest" ENUM "No","Yes";
BA_DEF_ BO_ "DiagResponse" ENUM "No","Yes";
BA_DEF_ BO_ "ETHGatewayMessageSendType" ENUM "UseGenMsgSendType","onWrite","noAutoCode";
BA_DEF_ BO_ "ETHId" STRING ;
BA_DEF_ BO_ "GatewayHandlerEnum" ENUM "noHandler","uds","alertLog","messageLogOnReception","udsClient";
BA_DEF_ BO_ "GatewayMessageAtomic" ENUM "No","Yes";
BA_DEF_ BO_ "GatewayMessageSendType" ENUM "UseGenMsgSendType","onWrite","noAutoCode";
BA_DEF_ BO_ "GenMsgCycleTime" INT 0 0;
BA_DEF_ BO_ "GenMsgCycleTimeFast" INT 0 0;
BA_DEF_ BO_ "GenMsgDelayTime" INT 0 0;
BA_DEF_ BO_ "GenMsgForceMiaCheck" ENUM "No","Yes";
BA_DEF_ BO_ "GenMsgGatewayNotification" STRING ;
BA_DEF_ BO_ "GenMsgILSupport" ENUM "No","Yes";
BA_DEF_ BO_ "GenMsgSaltingFunction" ENUM "No","Yes";
BA_DEF_ BO_ "GenMsgSendType" ENUM "Cyclic","NotUsed","NotUsed","NotUsed","NotUsed","NotUsed","NotUsed","IfActive","NoMsgSendType","Sporadic";
BA_DEF_ BO_ "GenMsgStartValue" STRING ;
BA_DEF_ BO_ "GenMsgTimeOut" INT 0 0;
BA_DEF_ BO_ "MessageIdType" ENUM "normal","udsRequest","udsResponse","udsReserved","udsFunctionalRequest","networkManagement","bootloader","xcp","dtc","diagnostic","vendorExempt";
BA_DEF_ BO_ "NWMBotschaft" ENUM "nein","ja";
BA_DEF_ BO_ "NmMessage" ENUM "No","Yes";
BA_DEF_ BO_ "SubSystemId" INT 0 256;
BA_DEF_ BO_ "UsesChecksum" ENUM "No","Yes";
BA_DEF_ SG_ "FieldType" STRING ;
BA_DEF_ SG_ "FlexKomComment" STRING ;
BA_DEF_ SG_ "FlexKomIsMotorola" ENUM "nein","ja";
BA_DEF_ SG_ "FlexKomSID" INT 0 2147483647;
BA_DEF_ SG_ "FlexKomSigLaenge" INT 0 64;
BA_DEF_ SG_ "FlexKomSigName" STRING ;
BA_DEF_ SG_ "FlexKomSigStartPos" INT 0 63;
BA_DEF_ SG_ "FlexKomSigStartValue" STRING ;
BA_DEF_ SG_ "Gatewaysignal" INT 0 1;
BA_DEF_ SG_ "GenSigCycleTime" INT 0 0;
BA_DEF_ SG_ "GenSigCycleTimeActive" INT 0 0;
BA_DEF_ SG_ "GenSigPersistent" ENUM "No","Yes";
BA_DEF_ SG_ "GenSigSNA" STRING ;
BA_DEF_ SG_ "GenSigSendType" ENUM "Cyclic","OnWrite","OnWriteWithRepetition","OnChange","OnChangeWithRepetition","IfActive","IfActiveWithRepetition","NoSigSendType","NotUsed","NotUsed","NotUsed","NotUsed","NotUsed";
BA_DEF_ SG_ "GenSigStartValue" INT 0 0;
BA_DEF_ SG_ "GenSigTimeout_CGW" INT 0 65535;
BA_DEF_ SG_ "GenSigTimeout_DRVU" INT 0 65535;
BA_DEF_ SG_ "GenSigTimeout_ECM" INT 0 65535;
BA_DEF_ SG_ "GenSigTimeout_EIS" INT 0 65535;
BA_DEF_ SG_ "GenSigTimeout_EPS" INT 0 65535;
BA_DEF_ SG_ "GenSigTimeout_ESP_ABR" INT 0 65535;
BA_DEF_ SG_ "GenSigTimeout_IC" INT 0 65535;
BA_DEF_ SG_ "GenSigTimeout_MPC" INT 0 65535;
BA_DEF_ SG_ "GenSigTimeout_NV" INT 0 65535;
BA_DEF_ SG_ "GenSigTimeout_ORC" INT 0 65535;
BA_DEF_ SG_ "GenSigTimeout_PTS" INT 0 65535;
BA_DEF_ SG_ "GenSigTimeout_RBTM_FL" INT 0 65535;
BA_DEF_ SG_ "GenSigTimeout_RBTM_FR" INT 0 65535;
BA_DEF_ SG_ "GenSigTimeout_RDU" INT 0 65535;
BA_DEF_ SG_ "GenSigTimeout_SCCM" INT 0 65535;
BA_DEF_ SG_ "GenSigTimeout_SPC" INT 0 65535;
BA_DEF_ SG_ "GenSigTimeout_TPM" INT 0 65535;
BA_DEF_ SG_ "LogSignal" STRING ;
BA_DEF_ SG_ "PektronUpdateBitType" ENUM "Not used","Has update bit","Is update bit";
BA_DEF_REL_ BU_SG_REL_ "GenSigTimeoutTime" INT 0 0;

BA_DEF_DEF_ "AlertLogSubSystemId" 0;
BA_DEF_DEF_ "AlertType" 4;
BA_DEF_DEF_ "AppBotschaft" "nein";
BA_DEF_DEF_ "Baudrate" 500000;
BA_DEF_DEF_ "BusID" 0;
BA_DEF_DEF_ "BusType" "";
BA_DEF_DEF_ "DBName" "";
BA_DEF_DEF_ "DiagRequest" "No";
BA_DEF_DEF_ "DiagResponse" "No";
BA_DEF_DEF_ "ETHGatewayMessageSendType" "UseGenMsgSendType";
BA_DEF_DEF_ "ETHId" "";
BA_DEF_DEF_ "FieldType" "";
BA_DEF_DEF_ "FlexKomComment" "";
BA_DEF_DEF_ "FlexKomIsMotorola" "";
BA_DEF_DEF_ "FlexKomSID" 0;
BA_DEF_DEF_ "FlexKomSigLaenge" 0;
BA_DEF_DEF_ "FlexKomSigName" "";
BA_DEF_DEF_ "FlexKomSigStartPos" 0;
BA_DEF_DEF_ "FlexKomSigStartValue" "";
BA_DEF_DEF_ "GatewayHandlerEnum" "noHandler";
BA_DEF_DEF_ "GatewayMessageAtomic" "No";
BA_DEF_DEF_ "GatewayMessageSendType" "UseGenMsgSendType";
BA_DEF_DEF_ "Gatewaysignal" 0;
BA_DEF_DEF_ "GenMsgCycleTime" 0;
BA_DEF_DEF_ "GenMsgCycleTimeFast" 0;
BA_DEF_DEF_ "GenMsgDelayTime" 0;
BA_DEF_DEF_ "GenMsgForceMiaCheck" "No";
BA_DEF_DEF_ "GenMsgGatewayNotification" "";
BA_DEF_DEF_ "GenMsgILSupport" "Yes";
BA_DEF_DEF_ "GenMsgSaltingFunction" "No";
BA_DEF_DEF_ "GenMsgSendType" "Cyclic";
BA_DEF_DEF_ "GenMsgStartValue" "";
BA_DEF_DEF_ "GenMsgTimeOut" 0;
BA_DEF_DEF_ "GenSigCycleTime" 0;
BA_DEF_DEF_ "GenSigCycleTimeActive" 0;
BA_DEF_DEF_ "GenSigPersistent" "No";
BA_DEF_DEF_ "GenSigSNA" "";
BA_DEF_DEF_ "GenSigSendType" "Cyclic";
BA_DEF_DEF_ "GenSigStartValue" 0;
BA_DEF_DEF_ "GenSigTimeout_CGW" 0;
BA_DEF_DEF_ "GenSigTimeout_DRVU" 0;
BA_DEF_DEF_ "GenSigTimeout_ECM" 0;
BA_DEF_DEF_ "GenSigTimeout_EIS" 0;
BA_DEF_DEF_ "GenSigTimeout_EPS" 0;
BA_DEF_DEF_ "GenSigTimeout_ESP_ABR" 0;
BA_DEF_DEF_ "GenSigTimeout_IC" 0;
BA_DEF_DEF_ "GenSigTimeout_MPC" 0;
BA_DEF_DEF_ "GenSigTimeout_NV" 0;
BA_DEF_DEF_ "GenSigTimeout_ORC" 0;
BA_DEF_DEF_ "GenSigTimeout_PTS" 0;
BA_DEF_DEF_ "GenSigTimeout_RBTM_FL" 0;
BA_DEF_DEF_ "GenSigTimeout_RBTM_FR" 0;
BA_DEF_DEF_ "GenSigTimeout_RDU" 0;
BA_DEF_DEF_ "GenSigTimeout_SCCM" 0;
BA_DEF_DEF_ "GenSigTimeout_SPC" 0;
BA_DEF_DEF_ "GenSigTimeout_TPM" 0;
BA_DEF_DEF_ "LogSignal" "";
BA_DEF_DEF_ "Manufacturer" "Bosch_JLR";
BA_DEF_DEF_ "MessageIdType" "normal";
BA_DEF_DEF_ "NBTMax" 20;
BA_DEF_DEF_ "NBTMin" 10;
BA_DEF_DEF_ "NWID" 2;
BA_DEF_DEF_ "NWMBotschaft" "nein";
BA_DEF_DEF_ "NWMTyp" "keines";
BA_DEF_DEF_ "NetworkName" "";
BA_DEF_DEF_ "NmBaseAddress" 1024;
BA_DEF_DEF_ "NmMessage" "No";
BA_DEF_DEF_ "NmMessageCount" 64;
BA_DEF_DEF_ "NmType" "";
BA_DEF_DEF_ "PektronFilterBits" 0;
BA_DEF_DEF_ "PektronNSamples" 1;
BA_DEF_DEF_ "PektronPhaseSeg1" 3;
BA_DEF_DEF_ "PektronPhaseSeg2" 3;
BA_DEF_DEF_ "PektronPrescale" 1;
BA_DEF_DEF_ "PektronPriorityBits" 11;
BA_DEF_DEF_ "PektronPropSeg" 1;
BA_DEF_DEF_ "PektronProtocol" "CAN11";
BA_DEF_DEF_ "PektronSJW" 3;
BA_DEF_DEF_ "PektronUpdateBitType" "Not used";
BA_DEF_DEF_ "SamplePointMax" 81.25;
BA_DEF_DEF_ "SamplePointMin" 75.0;
BA_DEF_DEF_ "SubSystemId" 0;
BA_DEF_DEF_ "UsesChecksum" "No";
BA_DEF_DEF_ "Version" 160;
BA_DEF_DEF_ "VersionWeek" 32;
BA_DEF_DEF_ "VersionYear" 9;
BA_DEF_DEF_REL_ "GenSigTimeoutTime" 0;

BA_ "BusID" 5;
BA_ "BusType" "CAN";
BA_ "DBName" "ModelS_CH";
BA_ "Manufacturer" "Tesla";
BA_ "NBTMin" 0;
BA_ "NetworkName" "CH";
BA_ "NmBaseAddress" 1030;
BA_ "NmMessageCount" 8;
BA_ "NmType" "Vector";
BA_ "Version" 11;
BA_ "GenMsgSendType" BO_ 543 8;
BA_ "GenMsgStartValue" BO_ 543 "37077F7FFFFF0FFFh";
BA_ "MessageIdType" BO_ 543 10;
BA_ "GenMsgCycleTime" BO_ 1352 1000;
BA_ "GenMsgTimeOut" BO_ 1352 1000;
BA_ "GenMsgCycleTime" BO_ 600 100;
BA_ "AppBotschaft" BO_ 1572 1;
BA_ "GenMsgSendType" BO_ 1572 8;
BA_ "GenMsgStartValue" BO_ 1572 "0000000000000000h";
BA_ "MessageIdType" BO_ 1572 10;
BA_ "AlertLogSubSystemId" BO_ 1513 239;
BA_ "GatewayHandlerEnum" BO_ 1513 2;
BA_ "GenMsgSendType" BO_ 1513 8;
BA_ "FlexKomComment" SG_ 543 ALDW_MsgDisp_Rq "Advanced lane departure warning request";
BA_ "FlexKomIsMotorola" SG_ 543 ALDW_MsgDisp_Rq 1;
BA_ "FlexKomSID" SG_ 543 ALDW_MsgDisp_Rq 117443736;
BA_ "FlexKomSigLaenge" SG_ 543 ALDW_MsgDisp_Rq 64;
BA_ "FlexKomSigName" SG_ 543 ALDW_MsgDisp_Rq "ALDW_Rq";
BA_ "FlexKomSigStartPos" SG_ 543 ALDW_MsgDisp_Rq 7;
BA_ "FlexKomSigStartValue" SG_ 543 ALDW_MsgDisp_Rq "37077F7FFFFF0FFFh";
BA_ "GenSigCycleTime" SG_ 543 ALDW_MsgDisp_Rq 20;
BA_ "GenSigSNA" SG_ 543 ALDW_MsgDisp_Rq "7";
BA_ "GenSigSendType" SG_ 543 ALDW_MsgDisp_Rq 7;
BA_ "GenSigStartValue" SG_ 543 ALDW_MsgDisp_Rq 7;
BA_ "GenSigTimeout_IC" SG_ 543 ALDW_MsgDisp_Rq 210;
BA_ "FlexKomComment" SG_ 543 ALDW_Menu_Enbl_Rq "Advanced lane departure warning request";
BA_ "FlexKomIsMotorola" SG_ 543 ALDW_Menu_Enbl_Rq 1;
BA_ "FlexKomSID" SG_ 543 ALDW_Menu_Enbl_Rq 117443736;
BA_ "FlexKomSigLaenge" SG_ 543 ALDW_Menu_Enbl_Rq 64;
BA_ "FlexKomSigName" SG_ 543 ALDW_Menu_Enbl_Rq "ALDW_Rq";
BA_ "FlexKomSigStartPos" SG_ 543 ALDW_Menu_Enbl_Rq 7;
BA_ "FlexKomSigStartValue" SG_ 543 ALDW_Menu_Enbl_Rq "37077F7FFFFF0FFFh";
BA_ "GenSigCycleTime" SG_ 543 ALDW_Menu_Enbl_Rq 20;
BA_ "GenSigSendType" SG_ 543 ALDW_Menu_Enbl_Rq 7;
BA_ "GenSigTimeout_IC" SG_ 543 ALDW_Menu_Enbl_Rq 210;
BA_ "FlexKomComment" SG_ 543 ALDW_IndLmp_On_Rq "Advanced lane departure warning request";
BA_ "FlexKomIsMotorola" SG_ 543 ALDW_IndLmp_On_Rq 1;
BA_ "FlexKomSID" SG_ 543 ALDW_IndLmp_On_Rq 117443736;
BA_ "FlexKomSigLaenge" SG_ 543 ALDW_IndLmp_On_Rq 64;
BA_ "FlexKomSigName" SG_ 543 ALDW_IndLmp_On_Rq "ALDW_Rq";
BA_ "FlexKomSigStartPos" SG_ 543 ALDW_IndLmp_On_Rq 7;
BA_ "FlexKomSigStartValue" SG_ 543 ALDW_IndLmp_On_Rq "37077F7FFFFF0FFFh";
BA_ "GenSigCycleTime" SG_ 543 ALDW_IndLmp_On_Rq 20;
BA_ "GenSigSNA" SG_ 543 ALDW_IndLmp_On_Rq "3";
BA_ "GenSigSendType" SG_ 543 ALDW_IndLmp_On_Rq 7;
BA_ "GenSigStartValue" SG_ 543 ALDW_IndLmp_On_Rq 3;
BA_ "GenSigTimeout_IC" SG_ 543 ALDW_IndLmp_On_Rq 210;
BA_ "FlexKomComment" SG_ 543 ALDW_PulseTm_Rq "Advanced lane departure warning request";
BA_ "FlexKomIsMotorola" SG_ 543 ALDW_PulseTm_Rq 1;
BA_ "FlexKomSID" SG_ 543 ALDW_PulseTm_Rq 117443736;
BA_ "FlexKomSigLaenge" SG_ 543 ALDW_PulseTm_Rq 64;
BA_ "FlexKomSigName" SG_ 543 ALDW_PulseTm_Rq "ALDW_Rq";
BA_ "FlexKomSigStartPos" SG_ 543 ALDW_PulseTm_Rq 7;
BA_ "FlexKomSigStartValue" SG_ 543 ALDW_PulseTm_Rq "37077F7FFFFF0FFFh";
BA_ "GenSigCycleTime" SG_ 543 ALDW_PulseTm_Rq 20;
BA_ "GenSigSendType" SG_ 543 ALDW_PulseTm_Rq 7;
BA_ "FlexKomComment" SG_ 543 ALDW_Warn_Rq "Advanced lane departure warning request";
BA_ "FlexKomIsMotorola" SG_ 543 ALDW_Warn_Rq 1;
BA_ "FlexKomSID" SG_ 543 ALDW_Warn_Rq 117443736;
BA_ "FlexKomSigLaenge" SG_ 543 ALDW_Warn_Rq 64;
BA_ "FlexKomSigName" SG_ 543 ALDW_Warn_Rq "ALDW_Rq";
BA_ "FlexKomSigStartPos" SG_ 543 ALDW_Warn_Rq 7;
BA_ "FlexKomSigStartValue" SG_ 543 ALDW_Warn_Rq "37077F7FFFFF0FFFh";
BA_ "GenSigCycleTime" SG_ 543 ALDW_Warn_Rq 20;
BA_ "GenSigSNA" SG_ 543 ALDW_Warn_Rq "7";
BA_ "GenSigSendType" SG_ 543 ALDW_Warn_Rq 7;
BA_ "GenSigStartValue" SG_ 543 ALDW_Warn_Rq 7;
BA_ "GenSigTimeout_ESP_ABR" SG_ 543 ALDW_Warn_Rq 610;
BA_ "GenSigTimeout_IC" SG_ 543 ALDW_Warn_Rq 210;
BA_ "FlexKomComment" SG_ 543 ALDW_VibTm_Rq "Advanced lane departure warning request";
BA_ "FlexKomIsMotorola" SG_ 543 ALDW_VibTm_Rq 1;
BA_ "FlexKomSID" SG_ 543 ALDW_VibTm_Rq 117443736;
BA_ "FlexKomSigLaenge" SG_ 543 ALDW_VibTm_Rq 64;
BA_ "FlexKomSigName" SG_ 543 ALDW_VibTm_Rq "ALDW_Rq";
BA_ "FlexKomSigStartPos" SG_ 543 ALDW_VibTm_Rq 7;
BA_ "FlexKomSigStartValue" SG_ 543 ALDW_VibTm_Rq "37077F7FFFFF0FFFh";
BA_ "GenSigCycleTime" SG_ 543 ALDW_VibTm_Rq 20;
BA_ "GenSigSNA" SG_ 543 ALDW_VibTm_Rq "31";
BA_ "GenSigSendType" SG_ 543 ALDW_VibTm_Rq 7;
BA_ "GenSigTimeout_SCCM" SG_ 543 ALDW_VibTm_Rq 210;
BA_ "FlexKomComment" SG_ 543 ALDW_LaneMarkWidth_Lt "Advanced lane departure warning request";
BA_ "FlexKomIsMotorola" SG_ 543 ALDW_LaneMarkWidth_Lt 1;
BA_ "FlexKomSID" SG_ 543 ALDW_LaneMarkWidth_Lt 117443736;
BA_ "FlexKomSigLaenge" SG_ 543 ALDW_LaneMarkWidth_Lt 64;
BA_ "FlexKomSigName" SG_ 543 ALDW_LaneMarkWidth_Lt "ALDW_Rq";
BA_ "FlexKomSigStartPos" SG_ 543 ALDW_LaneMarkWidth_Lt 7;
BA_ "FlexKomSigStartValue" SG_ 543 ALDW_LaneMarkWidth_Lt "37077F7FFFFF0FFFh";
BA_ "GenSigCycleTime" SG_ 543 ALDW_LaneMarkWidth_Lt 20;
BA_ "GenSigSNA" SG_ 543 ALDW_LaneMarkWidth_Lt "127";
BA_ "GenSigSendType" SG_ 543 ALDW_LaneMarkWidth_Lt 7;
BA_ "GenSigStartValue" SG_ 543 ALDW_LaneMarkWidth_Lt 127;
BA_ "GenSigTimeout_ESP_ABR" SG_ 543 ALDW_LaneMarkWidth_Lt 610;
BA_ "FlexKomComment" SG_ 543 ALDW_WarnMd_Rq "Advanced lane departure warning request";
BA_ "FlexKomIsMotorola" SG_ 543 ALDW_WarnMd_Rq 1;
BA_ "FlexKomSID" SG_ 543 ALDW_WarnMd_Rq 117443736;
BA_ "FlexKomSigLaenge" SG_ 543 ALDW_WarnMd_Rq 64;
BA_ "FlexKomSigName" SG_ 543 ALDW_WarnMd_Rq "ALDW_Rq";
BA_ "FlexKomSigStartPos" SG_ 543 ALDW_WarnMd_Rq 7;
BA_ "FlexKomSigStartValue" SG_ 543 ALDW_WarnMd_Rq "37077F7FFFFF0FFFh";
BA_ "GenSigCycleTime" SG_ 543 ALDW_WarnMd_Rq 20;
BA_ "GenSigSendType" SG_ 543 ALDW_WarnMd_Rq 7;
BA_ "FlexKomComment" SG_ 543 ALDW_LaneMarkWidth_Rt "Advanced lane departure warning request";
BA_ "FlexKomIsMotorola" SG_ 543 ALDW_LaneMarkWidth_Rt 1;
BA_ "FlexKomSID" SG_ 543 ALDW_LaneMarkWidth_Rt 117443736;
BA_ "FlexKomSigLaenge" SG_ 543 ALDW_LaneMarkWidth_Rt 64;
BA_ "FlexKomSigName" SG_ 543 ALDW_LaneMarkWidth_Rt "ALDW_Rq";
BA_ "FlexKomSigStartPos" SG_ 543 ALDW_LaneMarkWidth_Rt 7;
BA_ "FlexKomSigStartValue" SG_ 543 ALDW_LaneMarkWidth_Rt "37077F7FFFFF0FFFh";
BA_ "GenSigCycleTime" SG_ 543 ALDW_LaneMarkWidth_Rt 20;
BA_ "GenSigSNA" SG_ 543 ALDW_LaneMarkWidth_Rt "127";
BA_ "GenSigSendType" SG_ 543 ALDW_LaneMarkWidth_Rt 7;
BA_ "GenSigStartValue" SG_ 543 ALDW_LaneMarkWidth_Rt 127;
BA_ "GenSigTimeout_ESP_ABR" SG_ 543 ALDW_LaneMarkWidth_Rt 610;
BA_ "FlexKomComment" SG_ 543 ALDW_OnCal_Stat "Advanced lane departure warning request";
BA_ "FlexKomIsMotorola" SG_ 543 ALDW_OnCal_Stat 1;
BA_ "FlexKomSID" SG_ 543 ALDW_OnCal_Stat 117443736;
BA_ "FlexKomSigLaenge" SG_ 543 ALDW_OnCal_Stat 64;
BA_ "FlexKomSigName" SG_ 543 ALDW_OnCal_Stat "ALDW_Rq";
BA_ "FlexKomSigStartPos" SG_ 543 ALDW_OnCal_Stat 7;
BA_ "FlexKomSigStartValue" SG_ 543 ALDW_OnCal_Stat "37077F7FFFFF0FFFh";
BA_ "GenSigCycleTime" SG_ 543 ALDW_OnCal_Stat 20;
BA_ "GenSigSNA" SG_ 543 ALDW_OnCal_Stat "3";
BA_ "GenSigSendType" SG_ 543 ALDW_OnCal_Stat 7;
BA_ "GenSigStartValue" SG_ 543 ALDW_OnCal_Stat 3;
BA_ "FlexKomComment" SG_ 543 ALDW_OnCalExecDist "Advanced lane departure warning request";
BA_ "FlexKomIsMotorola" SG_ 543 ALDW_OnCalExecDist 1;
BA_ "FlexKomSID" SG_ 543 ALDW_OnCalExecDist 117443736;
BA_ "FlexKomSigLaenge" SG_ 543 ALDW_OnCalExecDist 64;
BA_ "FlexKomSigName" SG_ 543 ALDW_OnCalExecDist "ALDW_Rq";
BA_ "FlexKomSigStartPos" SG_ 543 ALDW_OnCalExecDist 7;
BA_ "FlexKomSigStartValue" SG_ 543 ALDW_OnCalExecDist "37077F7FFFFF0FFFh";
BA_ "GenSigCycleTime" SG_ 543 ALDW_OnCalExecDist 20;
BA_ "GenSigSNA" SG_ 543 ALDW_OnCalExecDist "7";
BA_ "GenSigSendType" SG_ 543 ALDW_OnCalExecDist 7;
BA_ "GenSigStartValue" SG_ 543 ALDW_OnCalExecDist 7;
BA_ "FlexKomComment" SG_ 543 ALDW_BrkMsgDisp_Rq "Advanced lane departure warning request";
BA_ "FlexKomIsMotorola" SG_ 543 ALDW_BrkMsgDisp_Rq 1;
BA_ "FlexKomSID" SG_ 543 ALDW_BrkMsgDisp_Rq 117443736;
BA_ "FlexKomSigLaenge" SG_ 543 ALDW_BrkMsgDisp_Rq 64;
BA_ "FlexKomSigName" SG_ 543 ALDW_BrkMsgDisp_Rq "ALDW_Rq";
BA_ "FlexKomSigStartPos" SG_ 543 ALDW_BrkMsgDisp_Rq 7;
BA_ "FlexKomSigStartValue" SG_ 543 ALDW_BrkMsgDisp_Rq "37077F7FFFFF0FFFh";
BA_ "GenSigSNA" SG_ 543 ALDW_BrkMsgDisp_Rq "7";
BA_ "GenSigSendType" SG_ 543 ALDW_BrkMsgDisp_Rq 7;
BA_ "GenSigStartValue" SG_ 543 ALDW_BrkMsgDisp_Rq 7;
BA_ "GenSigTimeout_IC" SG_ 543 ALDW_BrkMsgDisp_Rq 210;
BA_ "FlexKomComment" SG_ 543 ALDW_LaneMark_DtctDist "Advanced lane departure warning request";
BA_ "FlexKomIsMotorola" SG_ 543 ALDW_LaneMark_DtctDist 1;
BA_ "FlexKomSID" SG_ 543 ALDW_LaneMark_DtctDist 117443736;
BA_ "FlexKomSigLaenge" SG_ 543 ALDW_LaneMark_DtctDist 64;
BA_ "FlexKomSigName" SG_ 543 ALDW_LaneMark_DtctDist "ALDW_Rq";
BA_ "FlexKomSigStartPos" SG_ 543 ALDW_LaneMark_DtctDist 7;
BA_ "FlexKomSigStartValue" SG_ 543 ALDW_LaneMark_DtctDist "37077F7FFFFF0FFFh";
BA_ "GenSigCycleTime" SG_ 543 ALDW_LaneMark_DtctDist 20;
BA_ "GenSigSNA" SG_ 543 ALDW_LaneMark_DtctDist "255";
BA_ "GenSigSendType" SG_ 543 ALDW_LaneMark_DtctDist 7;
BA_ "GenSigStartValue" SG_ 543 ALDW_LaneMark_DtctDist 255;
BA_ "FlexKomComment" SG_ 543 ALDW_ImgSyncNum "Advanced lane departure warning request";
BA_ "FlexKomIsMotorola" SG_ 543 ALDW_ImgSyncNum 1;
BA_ "FlexKomSID" SG_ 543 ALDW_ImgSyncNum 117443736;
BA_ "FlexKomSigLaenge" SG_ 543 ALDW_ImgSyncNum 64;
BA_ "FlexKomSigName" SG_ 543 ALDW_ImgSyncNum "ALDW_Rq";
BA_ "FlexKomSigStartPos" SG_ 543 ALDW_ImgSyncNum 7;
BA_ "FlexKomSigStartValue" SG_ 543 ALDW_ImgSyncNum "37077F7FFFFF0FFFh";
BA_ "GenSigCycleTime" SG_ 543 ALDW_ImgSyncNum 20;
BA_ "GenSigSNA" SG_ 543 ALDW_ImgSyncNum "15";
BA_ "GenSigSendType" SG_ 543 ALDW_ImgSyncNum 7;
BA_ "GenSigStartValue" SG_ 543 ALDW_ImgSyncNum 15;
BA_ "FlexKomComment" SG_ 543 MC_ALDW_A1 "Advanced lane departure warning request";
BA_ "FlexKomIsMotorola" SG_ 543 MC_ALDW_A1 1;
BA_ "FlexKomSID" SG_ 543 MC_ALDW_A1 117443736;
BA_ "FlexKomSigLaenge" SG_ 543 MC_ALDW_A1 64;
BA_ "FlexKomSigName" SG_ 543 MC_ALDW_A1 "ALDW_Rq";
BA_ "FlexKomSigStartPos" SG_ 543 MC_ALDW_A1 7;
BA_ "FlexKomSigStartValue" SG_ 543 MC_ALDW_A1 "37077F7FFFFF0FFFh";
BA_ "GenSigCycleTime" SG_ 543 MC_ALDW_A1 20;
BA_ "GenSigSendType" SG_ 543 MC_ALDW_A1 7;
BA_ "GenSigTimeout_ESP_ABR" SG_ 543 MC_ALDW_A1 610;
BA_ "FlexKomComment" SG_ 543 CRC_ALDW_A1 "Advanced lane departure warning request";
BA_ "FlexKomIsMotorola" SG_ 543 CRC_ALDW_A1 1;
BA_ "FlexKomSID" SG_ 543 CRC_ALDW_A1 117443736;
BA_ "FlexKomSigLaenge" SG_ 543 CRC_ALDW_A1 64;
BA_ "FlexKomSigName" SG_ 543 CRC_ALDW_A1 "ALDW_Rq";
BA_ "FlexKomSigStartPos" SG_ 543 CRC_ALDW_A1 7;
BA_ "FlexKomSigStartValue" SG_ 543 CRC_ALDW_A1 "37077F7FFFFF0FFFh";
BA_ "GenSigCycleTime" SG_ 543 CRC_ALDW_A1 20;
BA_ "GenSigSendType" SG_ 543 CRC_ALDW_A1 7;
BA_ "GenSigStartValue" SG_ 543 CRC_ALDW_A1 255;
BA_ "GenSigTimeout_ESP_ABR" SG_ 543 CRC_ALDW_A1 610;
BA_ "FieldType" SG_ 1352 APB_infoIndex "AP_infoIndex";
BA_ "GenSigCycleTime" SG_ 1352 APB_infoIndex 1000;
BA_ "FieldType" SG_ 1352 APB_buildType "AP_buildType";
BA_ "FieldType" SG_ 600 APB_watchdogState "AP_watchdogState";
BA_ "GenSigSNA" SG_ 600 APB_watchdogState "7";
BA_ "LogSignal" SG_ 600 APB_watchdogState "onChange";
BA_ "FlexKomComment" SG_ 1572 APPL_SG_SCCM "External application to ECU";
BA_ "FlexKomIsMotorola" SG_ 1572 APPL_SG_SCCM 1;
BA_ "FlexKomSID" SG_ 1572 APPL_SG_SCCM 117441588;
BA_ "FlexKomSigLaenge" SG_ 1572 APPL_SG_SCCM 64;
BA_ "FlexKomSigName" SG_ 1572 APPL_SG_SCCM "APPL_SG_SCCM";
BA_ "FlexKomSigStartPos" SG_ 1572 APPL_SG_SCCM 7;
BA_ "FlexKomSigStartValue" SG_ 1572 APPL_SG_SCCM "0000000000000000h";
BA_ "GenSigSendType" SG_ 1572 APPL_SG_SCCM 1;
BA_ "FieldType" SG_ 1513 APP_alertID "APP_alertID";
BA_ "GenSigStartValue" SG_ 1513 APP_sw018_maxThreshold 50;
BA_ "GenSigStartValue" SG_ 1513 APP_sw019_numFreeBytes 191;
BA_ "FieldType" SG_ 1513 APP_sw024_currentVehicleApp "APP_vehicleApp";
BA_ "GenSigSNA" SG_ 1513 APP_sw042_health_state "7";
BA_ "GenSigSNA" SG_ 1513 APP_sw042_epas_error_code "15";
BA_ "FieldType" SG_ 1513 APP_sw060_collisionWarningSource "FCM_collisionWarningSource";
BA_ "GenSigStartValue" SG_ 1513 APP_sw062_HorizontalMisalignment 32767.3084205;
BA_ "GenSigStartValue" SG_ 1513 APP_sw062_VerticalMisalignment 511.497323164;
BA_ "GenSigSNA" SG_ 1513 APP_sw069_diAPState "15";
BA_ "GenSigSNA" SG_ 1513 APP_sw070_currTireFitment "3";
BA_ "GenSigSNA" SG_ 1513 APP_sw070_lastTireFitment "3";
BA_ "GenSigSNA" SG_ 1513 APP_sw070_diGear "7";
BA_ "GenSigSNA" SG_ 1513 APP_sw071_selfParkType "7";
BA_ "GenSigSNA" SG_ 1513 APP_sw071_roadClass "0";
BA_ "FieldType" SG_ 1513 APP_sw073_escalateLDWreason "LC_escalateLDWreason";
BA_ "GenSigSNA" SG_ 1513 APP_sw074_roadClass "0";
BA_ "FieldType" SG_ 1513 APP_sw133_mainCamDeserFault "I2C_fault";
BA_ "FieldType" SG_ 1513 APP_sw133_mainCamSerFault "I2C_fault";
BA_ "FieldType" SG_ 1513 APP_sw133_mainCamSensorFault "I2C_fault";
BA_ "FieldType" SG_ 1513 APP_sw134_narrowCamDeserFault "I2C_fault";
BA_ "FieldType" SG_ 1513 APP_sw134_narrowCamSerFault "I2C_fault";
BA_ "FieldType" SG_ 1513 APP_sw134_narrowCamSensorFault "I2C_fault";
BA_ "FieldType" SG_ 1513 APP_sw135_fisheyeCamDeserFault "I2C_fault";
BA_ "FieldType" SG_ 1513 APP_sw135_fisheyeCamSerFault "I2C_fault";
BA_ "FieldType" SG_ 1513 APP_sw135_fisheyeCamSensorFault "I2C_fault";
BA_ "FieldType" SG_ 1513 APP_sw136_lPillarCamDeserFault "I2C_fault";
BA_ "FieldType" SG_ 1513 APP_sw136_lPillarCamSerFault "I2C_fault";
BA_ "FieldType" SG_ 1513 APP_sw136_lPillarCamSensorFault "I2C_fault";
BA_ "FieldType" SG_ 1513 APP_sw137_rPillarCamDeserFault "I2C_fault";
BA_ "FieldType" SG_ 1513 APP_sw137_rPillarCamSerFault "I2C_fault";
BA_ "FieldType" SG_ 1513 APP_sw137_rPillarCamSensorFault "I2C_fault";
BA_ "FieldType" SG_ 1513 APP_sw138_lRepeatCamDeserFault "I2C_fault";
BA_ "FieldType" SG_ 1513 APP_sw138_lRepeatCamSerFault "I2C_fault";
BA_ "FieldType" SG_ 1513 APP_sw138_lRepeatCamSensorFault "I2C_fault";
BA_ "FieldType" SG_ 1513 APP_sw139_rRepeatCamDeserFault "I2C_fault";
BA_ "FieldType" SG_ 1513 APP_sw139_rRepeatCamSerFault "I2C_fault";
BA_ "FieldType" SG_ 1513 APP_sw139_rRepeatCamSensorFault "I2C_fault";
BA_ "FieldType" SG_ 1513 APP_sw140_backupCamDeserFault "I2C_fault";
BA_ "FieldType" SG_ 1513 APP_sw140_backupCamCSIBridgeFlt "I2C_fault";
BA_ "FieldType" SG_ 1513 APP_sw140_backupCamSensorFault "I2C_fault";
BA_ "FieldType" SG_ 1513 APP_sw140_backupCamDeserLock "APP_sw140_backupCamDeserLock";
BA_ "FieldType" SG_ 1513 APP_sw140_backupCamSerFault "I2C_fault";
BA_ "FieldType" SG_ 1513 APP_sw142_problemCamPosition "APP_cameraPosition";

VAL_ 543 ALDW_MsgDisp_Rq 7 "SNA" 4 "LDP_NA" 3 "LDP_TEMP_NA" 2 "ALDW_NA" 1 "ALDW_TEMP_NA" 0 "IDLE" ;
VAL_ 543 ALDW_IndLmp_On_Rq 3 "SNA" 2 "READY" 1 "ON" 0 "OFF" ;
VAL_ 543 ALDW_PulseTm_Rq 3 "TM200" 2 "TM300" 1 "TM400" 0 "TM500" ;
VAL_ 543 ALDW_Warn_Rq 7 "SNA" 2 "WARN_RT" 1 "WARN_LT" 0 "IDLE" ;
VAL_ 543 ALDW_VibTm_Rq 31 "SNA" 0 "IDLE" ;
VAL_ 543 ALDW_LaneMarkWidth_Lt 127 "SNA" ;
VAL_ 543 ALDW_WarnMd_Rq 1 "CONT" 0 "PLS" ;
VAL_ 543 ALDW_LaneMarkWidth_Rt 127 "SNA" ;
VAL_ 543 ALDW_OnCal_Stat 3 "SNA" 2 "FINISH" 1 "ACTIVE" 0 "INACTIVE" ;
VAL_ 543 ALDW_OnCalExecDist 7 "SNA" 6 "NDEF6" 5 "KM_50_PLUS" 4 "KM_10_TO_50" 3 "KM_5_TO_10" 2 "KM_1_TO_5" 1 "KM_0_TO_1" 0 "KM_0" ;
VAL_ 543 ALDW_BrkMsgDisp_Rq 7 "SNA" 2 "BRK_RT" 1 "BRK_LT" 0 "IDLE" ;
VAL_ 543 ALDW_LaneMark_DtctDist 255 "SNA" ;
VAL_ 543 ALDW_ImgSyncNum 15 "SNA" ;
VAL_ 1352 APB_infoIndex 2 "AP_GITHASH" 1 "FW_GITHASH" 0 "AP_BUILD_TYPE" ;
VAL_ 1352 APB_buildType 3 "AP_BUILDTYPE_REPO" 1 "AP_BUILDTYPE_LOCAL" 0 "AP_BUILDTYPE_SIGNED" ;
VAL_ 600 APB_watchdogState 7 "AP_WDOG_STATE_SNA" 3 "AP_WDOG_STATE_HEALTHY" 2 "AP_WDOG_STATE_CRITICAL" 1 "AP_WDOG_STATE_DEGRADED" 0 "AP_WDOG_STATE_UNKNOWN" ;
VAL_ 1513 APP_alertID 320 "APP_w320_selfieCamTypeMismatch" 319 "APP_w319_backupCamTypeMismatch" 318 "APP_w318_rRepeatCamTypeMismatch" 317 "APP_w317_lRepeatCamTypeMismatch" 316 "APP_w316_rPillarCamTypeMismatch" 315 "APP_w315_lPillarCamTypeMismatch" 314 "APP_w314_fisheyeCamTypeMismatch" 313 "APP_w313_narrowCamTypeMismatch" 312 "APP_w312_mainCamTypeMismatch" 311 "APP_w311_eth1FrameErrors" 310 "APP_w310_eth0FrameErrors" 309 "APP_w309_selfieDisabledOnCar" 307 "APP_w307_lssTurnSignalFault" 306 "APP_w306_lssUltrasonicsBlocked" 305 "APP_w305_lssCamStreamExit" 304 "APP_w304_lssCamBlockedStatus" 303 "APP_w303_imuIrational" 301 "APP_w301_selfieCameraSyncFailed" 300 "APP_w300_backupCameraSyncFailed" 299 "APP_w299_rRepeatCameraSyncFailed" 298 "APP_w298_lRepeatCameraSyncFailed" 297 "APP_w297_rPillarCameraSyncFailed" 296 "APP_w296_lPillarCameraSyncFailed" 295 "APP_w295_fisheyeCameraSyncFailed" 294 "APP_w294_narrowCameraSyncFailed" 293 "APP_w293_mainCameraSyncFailed" 292 "APP_w292_vcseatMIA" 291 "APP_w291_stopSignWarning" 290 "APP_w290_dramUncorrEccErrors" 289 "APP_w289_dramCorrEccErrors" 288 "APP_w288_trafficLightWarning" 287 "APP_w287_gpsFusionStatus" 286 "APP_w286_gpsComIssue" 285 "APP_w285_gpsFaultReset" 284 "APP_w284_gpsAntennaDisconnected" 283 "APP_w283_enhancedSummonAbort" 282 "APP_w282_selfieCameraStreamErr" 281 "APP_w281_backupCameraStreamErr" 280 "APP_w280_rRepeatCameraStreamErr" 279 "APP_w279_lRepeatCameraStreamErr" 278 "APP_w278_rPillarCameraStreamErr" 277 "APP_w277_lPillarCameraStreamErr" 276 "APP_w276_fisheyeCameraStreamErr" 275 "APP_w275_narrowCameraStreamErr" 274 "APP_w274_mainCameraStreamErr" 273 "APP_w273_lssEvent" 272 "APP_w272_laneChangeUnavailable" 271 "APP_w271_laneChangeAborted" 270 "APP_w270_blindspotRestricted" 269 "APP_w269_autopilotLimited" 268 "APP_w268_backupCamExtNotCal" 267 "APP_w267_benchtopEcu" 266 "APP_w266_visionScheduleFallback" 265 "APP_w265_drvOnNavUnavailable" 264 "APP_w264_lssFault" 263 "APP_w263_lssAbort" 262 "APP_w262_apeCalibMode" 261 "APP_w261_pcieHardwareErrors" 260 "APP_w260_collisionWarningEvent" 259 "APP_w259_aebOverrideEvent" 258 "APP_w258_aebEvent" 257 "APP_w257_brakeJerkEvent" 233 "APP_w233_laneChangeCancelled" 232 "APP_w232_laneChangeRequested" 231 "APP_w231_idfEvent" 230 "APP_w230_alcUltrasoundBlocked" 229 "APP_w229_alcUltrasoundDamaged" 227 "APP_w227_virtualWallBlocked" 226 "APP_w226_lcCamCalNeededSpeedLmt" 225 "APP_w225_lcDegradedVisSpeedLmt" 224 "APP_w224_accCameraCalibration" 223 "APP_w223_accObjectInPath" 222 "APP_w222_accCameraBlind" 221 "APP_w221_accRadarBlind" 220 "APP_w220_lcTempUnavailableRoad" 219 "APP_w219_lcTempUnavailableSpeed" 218 "APP_w218_lcSpeedExceededLimit" 217 "APP_w217_lcUnavailableSpeeding" 216 "APP_w216_driverOverriding" 215 "APP_w215_contDriverNotIntracting" 214 "APP_w214_driverNotIntracting" 213 "APP_w213_autosteerStruckOut" 212 "APP_w212_lcUnavailableStrikeOut" 211 "APP_w211_accNoSeatBelt" 210 "APP_w210_camObstrcted" 209 "APP_w209_autoSummonRequest" 208 "APP_w208_rackDetected" 207 "APP_w207_autosteerUnavailable" 206 "APP_w206_autosteerNotEnabled" 205 "APP_w205_apcFinalRear" 204 "APP_w204_apcFinalFront" 203 "APP_w203_apcActivation" 202 "APP_w202_scwNoisyEnvironment" 201 "APP_w201_lcAborting" 200 "APP_w200_lcSlowdown" 199 "APP_w199_apcAbort" 198 "APP_w198_tsrUnavailable" 197 "APP_w197_redLightWarning" 196 "APP_w196_stopSignWarning" 195 "APP_w195_scwUnavailable" 194 "APP_w194_accDriverResumeRqrd" 193 "APP_w193_camWindshieldUnclean" 192 "APP_w192_emergencySpeakerFail" 191 "APP_w191_autopilotAborting" 190 "APP_w190_selfieCameraStreamExit" 189 "APP_w189_backupCameraStreamExit" 188 "APP_w188_rRepeatCameraStreamExit" 187 "APP_w187_lRepeatCameraStreamExit" 186 "APP_w186_rPillarCameraStreamExit" 185 "APP_w185_lPillarCameraStreamExit" 184 "APP_w184_fisheyeCameraStreamExit" 183 "APP_w183_narrowCameraStreamExit" 182 "APP_w182_mainCameraStreamExit" 181 "APP_w181_rRepeatCamCalSaved" 180 "APP_w180_lRepeatCamCalSaved" 179 "APP_w179_rPillarCamCalSaved" 178 "APP_w178_lPillarCamCalSaved" 177 "APP_w177_fisheyeCamCalSaved" 176 "APP_w176_rRepeatCamExtNotCal" 175 "APP_w175_lRepeatCamExtNotCal" 174 "APP_w174_rPillarCamExtNotCal" 173 "APP_w173_lPillarCamExtNotCal" 172 "APP_w172_fisheyeCamExtNotCal" 170 "APP_w170_selfieCameraTypeError" 169 "APP_w169_backupCameraTypeError" 168 "APP_w168_rRepeatCameraTypeError" 167 "APP_w167_lRepeatCameraTypeError" 166 "APP_w166_rPillarCameraTypeError" 165 "APP_w165_lPillarCameraTypeError" 164 "APP_w164_fisheyeCameraTypeError" 163 "APP_w163_narrowCameraTypeError" 162 "APP_w162_mainCameraTypeError" 161 "APP_w161_backupCameraUnavailable" 149 "APP_w149_diskFull" 148 "APP_w148_overlayActive" 147 "APP_w147_selfieCamInitFault" 146 "APP_w146_telemetryProblem" 145 "APP_w145_camSelfCalIssue" 144 "APP_w144_fanctrldError" 143 "APP_w143_IDF_event" 142 "APP_w142_fwdCamPitchProblem" 141 "APP_w141_ECU_Thermal_Issue" 140 "APP_w140_backupCamInitFault" 139 "APP_w139_rRepeatCamInitFault" 138 "APP_w138_lRepeatCamInitFault" 137 "APP_w137_rPillarCamInitFault" 136 "APP_w136_lPillarCamInitFault" 135 "APP_w135_fisheyeCamInitFault" 134 "APP_w134_narrowCamInitFault" 133 "APP_w133_mainCamInitFault" 132 "APP_w132_narrowCamCalSaved" 131 "APP_w131_mainCamCalSaved" 130 "APP_w130_narrowCamExtNotCal" 129 "APP_w129_mainCamExtNotCal" 106 "APP_w106_torsionBarCalibrated" 103 "APP_w103_robExperimentalAEB" 86 "APP_w086_robCollision" 85 "APP_w085_pmmSteering" 84 "APP_w084_pmmIPSO" 83 "APP_w083_inPathRADObject" 82 "APP_w082_inPathFSviolation" 81 "APP_w081_pmmActiveBraking" 80 "APP_w080_accFailedActivation" 79 "APP_w079_edrAvailable" 78 "APP_w078_pmmActive2" 77 "APP_w077_pmmActive" 76 "APP_w076_mobilEyeSetC" 75 "APP_w075_scMia" 74 "APP_w074_inPathStationaryObst" 73 "APP_w073_issueEscalatedLDW" 72 "APP_w072_selfparkComplete" 71 "APP_w071_selfparkStarted" 70 "APP_w070_apcIncompleteCal" 69 "APP_w069_apcSpaceMasked" 68 "APP_w068_vlInconsistency" 67 "APP_w067_steeringAlignment" 66 "APP_w066_deserializerLockLost" 65 "APP_w065_deserializerOvercurrent" 64 "APP_w064_epasMia" 63 "APP_w063_parkVersionMismatch" 62 "APP_w062_radcAlignment" 61 "APP_w061_airSuspensionMia" 60 "APP_w060_fcw_event" 59 "APP_w059_parkMia" 58 "APP_w058_epbMia" 57 "APP_w057_mcuMia" 56 "APP_w056_diMia" 55 "APP_w055_radcVersionMismatch" 54 "APP_w054_camAutofix" 53 "APP_w053_radcCommIssue" 52 "APP_w052_radcSensorIssue" 51 "APP_w051_radcEcuIssue" 50 "APP_w050_aeb_event" 49 "APP_w049_eyeqVersionMismatch" 48 "APP_w048_APP_Features_Disabled" 47 "APP_w047_edrEvent" 46 "APP_w046_eepromRecordAbsent" 45 "APP_w045_radMia" 44 "APP_w044_appMobileyeFailure" 43 "APP_w043_camLongRunTime" 42 "APP_w042_autopilotAborting" 41 "APP_w041_autopilotRateSaturated" 40 "APP_w040_autopilotAngleSaturated" 39 "APP_w039_sdm_rcm_Mia" 38 "APP_w038_camFailure" 37 "APP_w037_camTacIssue" 36 "APP_w036_bdyMia" 35 "APP_w035_espMia" 34 "APP_w034_sccmMia" 33 "APP_w033_gtwMia" 32 "APP_w032_canTxError" 31 "APP_w031_canRxError" 30 "APP_w030_Heater_Issue" 29 "APP_w029_spi_tx_error" 28 "APP_w028_spi_rx_error" 27 "APP_w027_ECU_Reset_Fault" 26 "APP_w026_ECU_timingIssue" 25 "APP_w025_LC_Steering_Override" 24 "APP_w024_ECU_Watchdog_Reset" 23 "APP_w023_ECU_Cam_Statemismatch" 22 "APP_w022_ECU_EEPROM_Failure" 21 "APP_w021_ECU_Temperature_Issue" 20 "APP_w020_ECU_checkstopError" 19 "APP_w019_ECU_Stack_Overflow" 18 "APP_w018_ECU_Power_Issue" 17 "APP_w017_Cam_Msg_MIA" 16 "APP_w016_aeb_e_event" 15 "APP_w015_Camera_Failsafes" 14 "APP_w014_swAssert" 13 "APP_w013_Cam_Watchdog" 12 "APP_w012_Cam_BootFailure" 11 "APP_w011_scaEvent" 10 "APP_w010_radcCalibIssue" 9 "APP_w009_aebFault" 8 "APP_w008_parkDisabled" 7 "APP_w007_ahlbDisabled" 6 "APP_w006_aebCancelled" 5 "APP_w005_fcwCancelled" 4 "APP_w004_accDisabled" 3 "APP_w003_isaDisabled" 2 "APP_w002_ldwDisabled" 0 "APP_w000_reserved" ;
VAL_ 1513 APP_sw004_accState 11 "CANCEL_OUT_OF_CALIBRATION" 10 "CANCEL_GENERIC_SILENT" 9 "CANCEL_PATH_NOT_CLEAR" 8 "FAULT" 7 "CANCEL_RADAR" 6 "CANCEL_CAMERA" 5 "CANCEL_GENERIC" 4 "READY_FOR_RESUME" 3 "HOLD" 2 "STANDSTILL" 1 "ACTIVE" 0 "IDLE" ;
VAL_ 1513 APP_sw004_appMobileyeStatus 24 "MOBILEYE_STATUS_UNDEFINED" 23 "MOBILEYE_STATUS_TEARDOWN_FLASH_ACCESS_MODE" 22 "MOBILEYE_STATUS_FLASH_READ_MODE" 21 "MOBILEYE_STATUS_SETUP_FLASH_ACCESS_MODE" 20 "MOBILEYE_STATUS_RUNNING_SPTAC_MODE" 19 "MOBILEYE_STATUS_SPTAC_INIT_SENT" 18 "MOBILEYE_STATUS_WAITING_FOR_SPTAC_INIT" 17 "MOBILEYE_STATUS_BURN_EDR_MODE" 16 "MOBILEYE_STATUS_SPC_INIT_SENT" 15 "MOBILEYE_STATUS_WAITING_FOR_SPC_INIT" 14 "MOBILEYE_STATUS_ERROR" 13 "MOBILEYE_STATUS_LATCHING_FAILURE" 12 "MOBILEYE_STATUS_UPDATING" 11 "MOBILEYE_STATUS_RUNNING_DV_MODE" 10 "MOBILEYE_STATUS_WAITING_FOR_DV" 9 "MOBILEYE_STATUS_RUNNING_TAC_MODE" 8 "MOBILEYE_STATUS_RUNNING_SPC_MODE" 7 "MOBILEYE_STATUS_RUNNING_VISION_MODE" 6 "MOBILEYE_STATUS_TAC_INIT_SENT" 5 "MOBILEYE_STATUS_WAITING_FOR_TAC_INIT" 4 "MOBILEYE_STATUS_VISION_INIT_SENT" 3 "MOBILEYE_STATUS_WAITING_FOR_VISION_INIT" 2 "MOBILEYE_STATUS_WAITING_FOR_BOOT" 1 "MOBILEYE_STATUS_POWER_OFF" 0 "MOBILEYE_STATUS_POWER_CYCLE" ;
VAL_ 1513 APP_sw006_timeOfDay 2 "TIME_DUSK" 1 "TIME_NIGHT" 0 "TIME_DAY" ;
VAL_ 1513 APP_sw010_a04calibNotDone 1 "True" 0 "False" ;
VAL_ 1513 APP_sw010_a05calibReqd 1 "True" 0 "False" ;
VAL_ 1513 APP_sw010_a06calibNotOK 1 "True" 0 "False" ;
VAL_ 1513 APP_sw010_a08PlantMode 1 "True" 0 "False" ;
VAL_ 1513 APP_sw011_scaState 4 "FAULT" 3 "AVOIDANCE" 2 "AVAILABLE" 1 "UNAVAILABLE" 0 "DISABLED" ;
VAL_ 1513 APP_sw012_bootDDRTempStatus 3 "SDRAM high temperature" 2 "temperature grater than 85 C" 1 "temperature less or equal to 85 C" 0 "SDRAM low temperatue" ;
VAL_ 1513 APP_sw012_mespDDRTempStatus 7 "Temperature error" 3 "Temperature above 85" 2 "Termperature above spec" 1 "Temperature below spec" 0 "Temperature ok" ;
VAL_ 1513 APP_sw013_stateBeforeWatchdog 24 "MOBILEYE_STATUS_UNDEFINED" 23 "MOBILEYE_STATUS_TEARDOWN_FLASH_ACCESS_MODE" 22 "MOBILEYE_STATUS_FLASH_READ_MODE" 21 "MOBILEYE_STATUS_SETUP_FLASH_ACCESS_MODE" 20 "MOBILEYE_STATUS_RUNNING_SPTAC_MODE" 19 "MOBILEYE_STATUS_SPTAC_INIT_SENT" 18 "MOBILEYE_STATUS_WAITING_FOR_SPTAC_INIT" 17 "MOBILEYE_STATUS_BURN_EDR_MODE" 16 "MOBILEYE_STATUS_SPC_INIT_SENT" 15 "MOBILEYE_STATUS_WAITING_FOR_SPC_INIT" 14 "MOBILEYE_STATUS_ERROR" 13 "MOBILEYE_STATUS_LATCHING_FAILURE" 12 "MOBILEYE_STATUS_UPDATING" 11 "MOBILEYE_STATUS_RUNNING_DV_MODE" 10 "MOBILEYE_STATUS_WAITING_FOR_DV" 9 "MOBILEYE_STATUS_RUNNING_TAC_MODE" 8 "MOBILEYE_STATUS_RUNNING_SPC_MODE" 7 "MOBILEYE_STATUS_RUNNING_VISION_MODE" 6 "MOBILEYE_STATUS_TAC_INIT_SENT" 5 "MOBILEYE_STATUS_WAITING_FOR_TAC_INIT" 4 "MOBILEYE_STATUS_VISION_INIT_SENT" 3 "MOBILEYE_STATUS_WAITING_FOR_VISION_INIT" 2 "MOBILEYE_STATUS_WAITING_FOR_BOOT" 1 "MOBILEYE_STATUS_POWER_OFF" 0 "MOBILEYE_STATUS_POWER_CYCLE" ;
VAL_ 1513 APP_sw014_fileNameHash 32617 "HW_GPIO_PAD.c" 32602 "UDS_FlowControl.c" 32601 "ACC_compute.c" 32576 "app_CAN.c" 32563 "IO_RGM.c" 32315 "IQmath.c" 32314 "HW_CGM.c" 32299 "HW_RGM.c" 32074 "trajectory_planner_main.c" 32054 "HW_ADC.c" 32006 "NVM_Manager_component_specific.c" 31862 "IO_queue_component_specific.c" 31831 "fixquat.c" 31790 "IO_ADC.c" 31784 "UDS_TP.c" 31764 "lib_UDS_EEPROM.c" 31604 "HW_GPIO_pad_definitions.c" 31348 "app_mobileye_version_matrix.c" 31343 "HW_ECSM.c" 31291 "UDS_RC.c" 31247 "fixvector2d.c" 31246 "fixvector3d.c" 31032 "IO_radar_alert.c" 31009 "IO_CAN.c" 30055 "UDS_TRD.c" 29810 "app_tsr.c" 29797 "IO_watchdog.c" 29787 "SCA_monitor.c" 29561 "UDS_ctrlDTC.c" 29531 "IO_Mobileye.c" 29280 "AlertManagerCfg.c" 29243 "Interpolate_IQ15.c" 29033 "app_ahb.c" 29024 "UDS_readDTC.c" 28726 "HW_LIN.c" 28722 "HW_SIU.c" 28720 "HW_PIT.c" 28519 "IO_PWMInput.c" 28465 "IO_PWM.c" 28459 "IO_SWT.c" 28211 "HW_SWT.c" 28197 "HW_APP_SIU.c" 27947 "HW_OTP.c" 27946 "HW_STM.c" 27914 "util_queue.c" 27750 "IO_mutex_component_specific.c" 27699 "IO_OTP.c" 27516 "IO_CAN_data.c" 27451 "UDS_CC.c" 27444 "HW_CRC.c" 27262 "HW_WKPU.c" 27233 "app_vehicle.c" 27179 "HW_MSR.c" 26995 "xcp_par.c" 26981 "app_ldw.c" 26926 "HW_SPI.c" 26232 "ACC_speed_limit.c" 25952 "das_app.c" 25866 "RTOS_interrupt.c" 25713 "ACC_fleet_speed.c" 25691 "ACC_monitor.c" 25190 "UDS_DSC.c" 25164 "road_furniture_main.c" 25154 "app_ECU.c" 24957 "CSA.c" 24907 "lib_HSD.c" 24678 "IO_UART.c" 24636 "HW_RGM_APP.c" 24145 "fix16_exp.c" 23589 "app_mobileye_country_codes.c" 22573 "utils_math.c" 22548 "IO_Vehicle.c" 22364 "util_codeDescriptor_ghs.c" 22082 "NVM_Manager.c" 21614 "LC_calculate_health.c" 21599 "watchdog_manager_component_specific.c" 21295 "app_heater.c" 21266 "IO_Environment.c" 21063 "lib_mobileye_mesp_utils.c" 20331 "util_ringBuffer.c" 20237 "UDS_SecurityAccess.c" 19731 "LC_follow_path.c" 19318 "fix16.c" 19037 "fix16_str.c" 18253 "Interpolate.c" 17980 "HW_interrupt_componentSpecific.c" 17972 "UDS_SendSM.c" 17933 "IO_quadDecoder.c" 17433 "util_crc_j1850.c" 17419 "UDS_RQ_ULDL_common.c" 17259 "util_codeDescriptor.c" 17168 "ACC_filter.c" 17016 "lib_mobileye_mesp_basic_service.c" 16910 "ACC_output.c" 16194 "UDS_SIDs.c" 16151 "IO_ECU_component_specific.c" 15973 "UDS_RQDL.c" 15965 "app_mobileye_EDR.c" 15928 "UDS_Processor.c" 15733 "UDS_WDBI.c" 15732 "UDS_WMBA.c" 15721 "profiler.c" 15678 "task_mobileye.c" 15616 "lib_mobileye_mesp.c" 15378 "HW_CAN_component_specific.c" 15375 "lib_NVRAM.c" 15211 "HW_EMIOS.c" 15197 "app_mobileye_TAC.c" 15181 "app_watchdog.c" 15121 "lib_mobileye_mesp_calibration_service.c" 14931 "lib_mobileye.c" 14684 "lib_math.c" 14453 "UDS_RDBI.c" 14452 "UDS_RMBA.c" 14448 "SCA_main.c" 14446 "UDS_ECUReset.c" 14425 "IO_reset.c" 14206 "PMM_main.c" 14185 "rijndael.c" 14180 "task_CAN.c" 14118 "util_counters.c" 13912 "utils_APP_assert.c" 13572 "virtual_wall_main.c" 13383 "IO_timer.c" 13130 "app_vehicle_driving_side.c" 12911 "task_UDS.c" 12645 "IO_Failsafes.c" 12596 "HW_ME.c" 12339 "LC_hands_on_detection.c" 12133 "UDS_RQUL.c" 12091 "IO_EEPROM.c" 11884 "UDS_RQTE.c" 11877 "world_model_main.c" 11811 "HW_EEPROM.c" 11615 "lib_mobileye_mesp_frame_data_service.c" 11568 "RTOS_time.c" 11525 "HW_SPI_component_specific.c" 11277 "virtual_lane_main.c" 11132 "CalcFilt.c" 11089 "lateral_control_angle_tables.c" 10860 "main.c" 10840 "LC_telemetry.c" 10530 "ACC_target_assessment.c" 10524 "app_system_health.c" 10352 "ACC_main.c" 10339 "APC_main.c" 10317 "IO_mutex.c" 10007 "IO_digOut.c" 10004 "lib_mobileye_mesp_edr_service.c" 9784 "UDS_IOCBI.c" 9750 "HW_LIN_processor_specific.c" 9729 "IO_board_test.c" 9546 "app_mobileye.c" 9257 "FCM_threat_assessment.c" 9082 "lib_mobileye_mesp_camera_service.c" 9056 "fixarray.c" 8801 "UDS_ECU_shim.c" 8716 "fract32.c" 8560 "FCM_main.c" 8537 "IO_MobileyeFlash.c" 8493 "UDS_ECU_Hooks.c" 8310 "util_bitManipulation.c" 8286 "IO_MobileyeFlashTestStub.c" 8274 "UDS_MasterSM.c" 8000 "AlertMap.c" 7969 "fixkalman.c" 7477 "TSR_telemetry.c" 7434 "FCM_state_machine.c" 7252 "HW_CAN_processorSpecific.c" 7223 "_xcp_appl.c" 7025 "fix16_trig.c" 6987 "AlertManager.c" 6941 "utils_ttc.c" 6209 "IO_digIn.c" 5924 "tasks.c" 5745 "task_vehicle.c" 5687 "fixmatrix.c" 5677 "IO_Heater.c" 5479 "UDS_ECU_Services.c" 5392 "UDS_ReceiveSM.c" 5158 "LC_health_monitor.c" 5145 "APC_state_machine.c" 5130 "ACC_state_machine.c" 4970 "Selfpark.c" 4950 "AlertManagerHeaderConfig.c" 4656 "SCA_angle.c" 4212 "watchdog_manager.c" 3931 "lib_IQ28QorivvaMathLib.c" 3666 "XcpBasic.c" 3145 "util_CRC32.c" 3113 "ACC_input.c" 2934 "ACC_target_selection.c" 2878 "HW_I2C.c" 2640 "app_mobileye_spi.c" 2632 "IO_ADC_componentSpecific.c" 2598 "IO_I2C.c" 2162 "UDS_clearDTC.c" 1889 "fix16_sqrt.c" 1612 "uint32.c" 1564 "IO_CAN_alerts.c" 1365 "LC_state_machine.c" 1151 "IO_EEPROM_component_specific.c" 1034 "SCA_state_machine.c" 605 "HW_EEPROM_common.c" 297 "CanReceiver_Generated.c" 48 "IO_edgeDetect.c" ;
VAL_ 1513 APP_sw015_RadarLowVisibility 3 "True_High_Severity" 2 "True_Medium_Severity" 1 "True_Low_Severity" 0 "False" ;
VAL_ 1513 APP_sw015_RadarMisalignment 3 "True_High_Severity" 2 "True_Medium_Severity" 1 "True_Low_Severity" 0 "False" ;
VAL_ 1513 APP_sw015_LowSun 3 "True_High_Severity" 2 "True_Medium_Severity" 1 "True_Low_Severity" 0 "False" ;
VAL_ 1513 APP_sw015_BlurredImage 3 "True_High_Severity" 2 "True_Medium_Severity" 1 "True_Low_Severity" 0 "False" ;
VAL_ 1513 APP_sw015_FullBlockage 3 "True_High_Severity" 2 "True_Medium_Severity" 1 "True_Low_Severity" 0 "False" ;
VAL_ 1513 APP_sw015_PartialBlockage 3 "True_High_Severity" 2 "True_Medium_Severity" 1 "True_Low_Severity" 0 "False" ;
VAL_ 1513 APP_sw015_AutofixOutOfCalib 3 "True_High_Severity" 2 "True_Medium_Severity" 1 "True_Low_Severity" 0 "False" ;
VAL_ 1513 APP_sw015_AutofixOutOfCalibYaw 3 "True_High_Severity" 2 "True_Medium_Severity" 1 "True_Low_Severity" 0 "False" ;
VAL_ 1513 APP_sw015_AutofixOOfCalibHorizon 3 "True_High_Severity" 2 "True_Medium_Severity" 1 "True_Low_Severity" 0 "False" ;
VAL_ 1513 APP_sw015_Splashes 3 "True_High_Severity" 2 "True_Medium_Severity" 1 "True_Low_Severity" 0 "False" ;
VAL_ 1513 APP_sw015_SmearedSpots 3 "True_High_Severity" 2 "True_Medium_Severity" 1 "True_Low_Severity" 0 "False" ;
VAL_ 1513 APP_sw015_SmearedHalos 3 "True_High_Severity" 2 "True_Medium_Severity" 1 "True_Low_Severity" 0 "False" ;
VAL_ 1513 APP_sw015_FoggyLights 3 "True_High_Severity" 2 "True_Medium_Severity" 1 "True_Low_Severity" 0 "False" ;
VAL_ 1513 APP_sw015_SunRay 3 "True_High_Severity" 2 "True_Medium_Severity" 1 "True_Low_Severity" 0 "False" ;
VAL_ 1513 APP_sw015_ImpairedVD 3 "True_High_Severity" 2 "True_Medium_Severity" 1 "True_Low_Severity" 0 "False" ;
VAL_ 1513 APP_sw015_SelfGlare 3 "True_High_Severity" 2 "True_Medium_Severity" 1 "True_Low_Severity" 0 "False" ;
VAL_ 1513 APP_sw015_OutOfFocusImage 3 "True_High_Severity" 2 "True_Medium_Severity" 1 "True_Low_Severity" 0 "False" ;
VAL_ 1513 APP_sw017_Camera_Msg_Lanes_MIA 1 "True" 0 "False" ;
VAL_ 1513 APP_sw017_Camera_Msg_Objects_MIA 1 "True" 0 "False" ;
VAL_ 1513 APP_sw017_Camera_Msg_Tsr_MIA 1 "True" 0 "False" ;
VAL_ 1513 APP_sw017_Camera_Msg_Hlb_MIA 1 "True" 0 "False" ;
VAL_ 1513 APP_sw017_Camera_Msg_Common_MIA 1 "True" 0 "False" ;
VAL_ 1513 APP_sw017_Camera_Msg_FCW_PCW_MIA 1 "True" 0 "False" ;
VAL_ 1513 APP_sw017_Camera_Msg_TFL_MIA 1 "True" 0 "False" ;
VAL_ 1513 APP_sw017_Any_Lanes_Msg_Recd 1 "True" 0 "False" ;
VAL_ 1513 APP_sw017_Any_Objects_Msg_Recd 1 "True" 0 "False" ;
VAL_ 1513 APP_sw017_Any_TFL_Msg_Recd 1 "True" 0 "False" ;
VAL_ 1513 APP_sw017_Any_Tsr_Msg_Recd 1 "True" 0 "False" ;
VAL_ 1513 APP_sw017_Any_Hlb_Msg_Recd 1 "True" 0 "False" ;
VAL_ 1513 APP_sw017_Any_Common_Msg_Recd 1 "True" 0 "False" ;
VAL_ 1513 APP_sw017_Any_FCW_PCW_Msg_Recd 1 "True" 0 "False" ;
VAL_ 1513 APP_sw018_railID 3 "1v2_rail" 2 "1v8_rail" 1 "3v3_rail" 0 "5v0_rail" ;
VAL_ 1513 APP_sw018_powerSequnceError 1 "True" 0 "False" ;
VAL_ 1513 APP_sw018_railControl 1 "RAIL_ENABLED" 0 "RAIL_DISABLED" ;
VAL_ 1513 APP_sw019_taskId 32 "MAX_TASK_ID" 31 "TASKS_ISOTERM_A72" 30 "TASKS_ISOTERM_SMS" 29 "TASKS_APP_1HZ" 28 "TASKS_APP_1KHZ" 27 "TASKS_SMS_SERIAL" 26 "TASKS_CAN_AP_RX" 25 "TASKS_CAN_AP_TX" 24 "TASKS_TMU" 23 "TASKS_WDG_TASK" 22 "TASKS_MBX_RELAY" 21 "TASKS_MBX_SCS_RX_HIGH" 20 "TASKS_MBX_SCS_RX_LOW" 19 "TASKS_MBX_SCS_TX_HIGH" 18 "TASKS_MBX_SCS_TX_LOW" 17 "TASKS_MBX_AP_RX_HIGH" 16 "TASKS_MBX_AP_RX_LOW" 15 "TASKS_MBX_AP_TX_HIGH" 14 "TASKS_MBX_AP_TX_LOW" 13 "TASKS_VEH_CAN" 12 "TASKS_RADAR_CAN" 11 "TASKS_CH_CAN" 10 "TASKS_PARTY_CAN" 9 "TASK_DEBUG_SMS_SERIAL_RX" 8 "TASK_DEBUG_SERIAL_TX" 7 "TASKS_SMS_SMS_UART_RX" 6 "TASKS_SMS_SMS_UART_TX" 5 "TASKS_VEHICLE" 4 "TASKS_MOBILEYE" 3 "TASKS_UDS" 2 "TASKS_CAN" 1 "TASKS_INIT" 0 "TASKS_RESERVED" ;
VAL_ 1513 APP_sw021_tempSensorId 4 "DDR_TEMP_SENSOR" 3 "CAMERA_TEMP_SENSOR" 2 "EYE_Q_TEMP_SENSOR_1" 1 "EYE_Q_TEMP_SENSOR_0" 0 "EXTERNAL_TEMP_SENSOR" ;
VAL_ 1513 APP_sw022_operation 4 "Erase All" 3 "Delete" 2 "Read" 1 "Write" 0 "Initialize" ;
VAL_ 1513 APP_sw024_currentVehicleApp 162 "APP_VA_LOC_MONITOR" 161 "APP_VA_EAC_MONITOR" 160 "APP_VA_VL_PROFILER" 159 "APP_VA_VL_GM_VEH_EXIT" 158 "APP_VA_VL_GM_MISC_END_VEH_ID5" 157 "APP_VA_VL_GM_MISC_END_VEH_ID4" 156 "APP_VA_VL_GM_MISC_END_VEH_ID3" 155 "APP_VA_VL_GM_MISC_END_VEH_ID2" 154 "APP_VA_VL_GM_MISC_END_VEH_ID1" 153 "APP_VA_VL_GM_MISC_END_VEH_ID0" 152 "APP_VA_VL_GM_HEADING_VEH_ID5" 151 "APP_VA_VL_GM_HEADING_VEH_ID4" 150 "APP_VA_VL_GM_HEADING_VEH_ID3" 149 "APP_VA_VL_GM_HEADING_VEH_ID2" 148 "APP_VA_VL_GM_HEADING_VEH_ID1" 147 "APP_VA_VL_GM_HEADING_VEH_ID0" 146 "APP_VA_VL_GM_NODP_LONG_VEH_ID5" 145 "APP_VA_VL_GM_NODP_LONG_VEH_ID4" 144 "APP_VA_VL_GM_NODP_LONG_VEH_ID3" 143 "APP_VA_VL_GM_NODP_LONG_VEH_ID2" 142 "APP_VA_VL_GM_NODP_LONG_VEH_ID1" 141 "APP_VA_VL_GM_NODP_LONG_VEH_ID0" 140 "APP_VA_VL_GM_NODP_LAT_VEH_ID5" 139 "APP_VA_VL_GM_NODP_LAT_VEH_ID4" 138 "APP_VA_VL_GM_NODP_LAT_VEH_ID3" 137 "APP_VA_VL_GM_NODP_LAT_VEH_ID2" 136 "APP_VA_VL_GM_NODP_LAT_VEH_ID1" 135 "APP_VA_VL_GM_NODP_LAT_VEH_ID0" 134 "APP_VA_VL_GM_NODP_FUSE_VEH_ID5" 133 "APP_VA_VL_GM_NODP_FUSE_VEH_ID4" 132 "APP_VA_VL_GM_NODP_FUSE_VEH_ID3" 131 "APP_VA_VL_GM_NODP_FUSE_VEH_ID2" 130 "APP_VA_VL_GM_NODP_FUSE_VEH_ID1" 129 "APP_VA_VL_GM_NODP_FUSE_VEH_ID0" 128 "APP_VA_VL_GM_DP_FUSE_VEH_ID5" 127 "APP_VA_VL_GM_DP_FUSE_VEH_ID4" 126 "APP_VA_VL_GM_DP_FUSE_VEH_ID3" 125 "APP_VA_VL_GM_DP_FUSE_VEH_ID2" 124 "APP_VA_VL_GM_DP_FUSE_VEH_ID1" 123 "APP_VA_VL_GM_DP_FUSE_VEH_ID0" 122 "APP_VA_VL_GM_DP_OLD_VEH_ID5" 121 "APP_VA_VL_GM_DP_OLD_VEH_ID4" 120 "APP_VA_VL_GM_DP_OLD_VEH_ID3" 119 "APP_VA_VL_GM_DP_OLD_VEH_ID2" 118 "APP_VA_VL_GM_DP_OLD_VEH_ID1" 117 "APP_VA_VL_GM_DP_OLD_VEH_ID0" 116 "APP_VA_VL_GM_DP_NEW_VEH_ID5" 115 "APP_VA_VL_GM_DP_NEW_VEH_ID4" 114 "APP_VA_VL_GM_DP_NEW_VEH_ID3" 113 "APP_VA_VL_GM_DP_NEW_VEH_ID2" 112 "APP_VA_VL_GM_DP_NEW_VEH_ID1" 111 "APP_VA_VL_GM_DP_NEW_VEH_ID0" 110 "APP_VA_VL_GM_DP_PRECHK_VEH_ID5" 109 "APP_VA_VL_GM_DP_PRECHK_VEH_ID4" 108 "APP_VA_VL_GM_DP_PRECHK_VEH_ID3" 107 "APP_VA_VL_GM_DP_PRECHK_VEH_ID2" 106 "APP_VA_VL_GM_DP_PRECHK_VEH_ID1" 105 "APP_VA_VL_GM_DP_PRECHK_VEH_ID0" 104 "APP_VA_VL_GM_INV_COV_VEH_ID5" 103 "APP_VA_VL_GM_INV_COV_VEH_ID4" 102 "APP_VA_VL_GM_INV_COV_VEH_ID3" 101 "APP_VA_VL_GM_INV_COV_VEH_ID2" 100 "APP_VA_VL_GM_INV_COV_VEH_ID1" 99 "APP_VA_VL_GM_INV_COV_VEH_ID0" 98 "APP_VA_VL_GM_OBS_XFM_VEH_ID5" 97 "APP_VA_VL_GM_OBS_XFM_VEH_ID4" 96 "APP_VA_VL_GM_OBS_XFM_VEH_ID3" 95 "APP_VA_VL_GM_OBS_XFM_VEH_ID2" 94 "APP_VA_VL_GM_OBS_XFM_VEH_ID1" 93 "APP_VA_VL_GM_OBS_XFM_VEH_ID0" 92 "APP_VA_VL_GM_COV_VEH_ID5" 91 "APP_VA_VL_GM_COV_VEH_ID4" 90 "APP_VA_VL_GM_COV_VEH_ID3" 89 "APP_VA_VL_GM_COV_VEH_ID2" 88 "APP_VA_VL_GM_COV_VEH_ID1" 87 "APP_VA_VL_GM_COV_VEH_ID0" 86 "APP_VA_VL_GM_CHK_LANE_VEH_ID5" 85 "APP_VA_VL_GM_CHK_LANE_VEH_ID4" 84 "APP_VA_VL_GM_CHK_LANE_VEH_ID3" 83 "APP_VA_VL_GM_CHK_LANE_VEH_ID2" 82 "APP_VA_VL_GM_CHK_LANE_VEH_ID1" 81 "APP_VA_VL_GM_CHK_LANE_VEH_ID0" 80 "APP_VA_VL_GM_CHK_ID_VEH_ID5" 79 "APP_VA_VL_GM_CHK_ID_VEH_ID4" 78 "APP_VA_VL_GM_CHK_ID_VEH_ID3" 77 "APP_VA_VL_GM_CHK_ID_VEH_ID2" 76 "APP_VA_VL_GM_CHK_ID_VEH_ID1" 75 "APP_VA_VL_GM_CHK_ID_VEH_ID0" 74 "APP_VA_ROB" 73 "APP_VA_VL_GM_EVAL_SAVE" 72 "APP_VA_VL_GM_EVAL_NEW_VEH_5" 71 "APP_VA_VL_GM_EVAL_NEW_VEH_4" 70 "APP_VA_VL_GM_EVAL_NEW_VEH_3" 69 "APP_VA_VL_GM_EVAL_NEW_VEH_2" 68 "APP_VA_VL_GM_EVAL_NEW_VEH_1" 67 "APP_VA_VL_GM_EVAL_NEW_VEH_0" 66 "APP_VA_VL_GM_EVAL_VEH_5" 65 "APP_VA_VL_GM_EVAL_VEH_4" 64 "APP_VA_VL_GM_EVAL_VEH_3" 63 "APP_VA_VL_GM_EVAL_VEH_2" 62 "APP_VA_VL_GM_EVAL_VEH_1" 61 "APP_VA_VL_GM_EVAL_VEH_0" 60 "APP_VA_VL_GM_EVAL_NAV" 59 "APP_VA_VL_GM_EVAL_HPP" 58 "APP_VA_VL_GM_EVAL_RL" 57 "APP_VA_VL_GM_EVAL_LL" 56 "APP_VA_VL_GM_EVAL_MODEL" 55 "APP_VA_VL_GM_EVAL_SETUP" 54 "APP_VA_VL_GM_EVAL" 53 "APP_VA_VL_GM_VEH_ID5" 52 "APP_VA_VL_GM_VEH_ID4" 51 "APP_VA_VL_GM_VEH_ID3" 50 "APP_VA_VL_GM_VEH_ID2" 49 "APP_VA_VL_GM_VEH_ID1" 48 "APP_VA_VL_GM_VEH_ID0" 47 "APP_VA_VL_GM_VEH_2" 46 "APP_VA_VL_GM_NAV_2" 45 "APP_VA_VL_GM_FS_2" 44 "APP_VA_VL_GM_HPP_2" 43 "APP_VA_VL_GM_LANE_2" 42 "APP_VA_VL_GM_NAV_1" 41 "APP_VA_VL_GM_VEH_1" 40 "APP_VA_VL_GM_FS_1" 39 "APP_VA_VL_GM_HPP_1" 38 "APP_VA_VL_GM_LANE_1" 37 "APP_VA_VL_GM_SETUP" 36 "APP_VA_VL_UU" 35 "APP_VA_VL_CDH" 34 "APP_VA_VL_MP" 33 "APP_VA_VL_ETC" 32 "APP_VA_VL_GM" 31 "APP_VA_VL_CMC" 30 "APP_VA_VL_CFELC" 29 "APP_VA_VL_UELP" 28 "APP_VA_VL_CCM" 27 "APP_VA_VL_CDE" 26 "APP_VA_VL_SM" 25 "APP_VA_VL_UFC" 24 "APP_VA_VL_FM" 23 "APP_VA_VL_UNO" 22 "APP_VA_VL_ULWE" 21 "APP_VA_VL_CFKO" 20 "APP_VA_VL_RLV" 19 "APP_VA_VL_SO" 18 "APP_VA_ROAD_FURNITURE" 17 "APP_VA_VIRTUAL_WALL" 16 "APP_VA_VIRTUAL_LANE" 15 "APP_VA_WORLD_MODEL" 14 "APP_VA_TRAJECTORY_PLANNER" 13 "APP_VA_CSA" 12 "APP_VA_TSR" 11 "APP_VA_LDW" 10 "APP_VA_ACC" 9 "APP_VA_FCM" 8 "APP_VA_LC" 7 "APP_VA_BSD" 6 "APP_VA_AHB" 5 "APP_VA_SCA" 4 "APP_VA_APC" 3 "APP_VA_PMM" 2 "APP_VA_VEHICLE" 1 "APP_VA_INIT" 0 "APP_VA_NONE" ;
VAL_ 1513 APP_sw025_state_before_override 14 "LC_INTERNAL_STATE_NUM_STATES" 13 "LC_INTERNAL_STATE_FULL_ABORTED" 12 "LC_INTERNAL_STATE_FULL_ABORTING" 11 "LC_INTERNAL_STATE_AUTOSTEER_ABORTED" 10 "LC_INTERNAL_STATE_AUTOSTEER_ABORTING" 9 "LC_INTERNAL_STATE_AUTOSTEER_CANCELING" 8 "LC_INTERNAL_STATE_AUTOSTEER_ACTIVE" 7 "LC_INTERNAL_STATE_AUTOSTEER_PREACTIVE" 6 "LC_INTERNAL_STATE_ACC_ACTIVE_AUTOSTEER_AVAILABLE" 5 "LC_INTERNAL_STATE_ACC_ACTIVE_AUTOSTEER_UNAVAILABLE" 4 "LC_INTERNAL_STATE_AUTOSTEER_AVAILABLE" 3 "LC_INTERNAL_STATE_ACC_AVAIALABLE" 2 "LC_INTERNAL_STATE_UNAVAILABLE" 1 "LC_INTERNAL_STATE_DISABLED" 0 "LC_INTERNAL_STATE_FAULT" ;
VAL_ 1513 APP_sw025_leftLaneUsage 3 "BLACKLISTED" 2 "FUSED" 1 "AVAILABLE" 0 "REJECTED_UNAVAILABLE" ;
VAL_ 1513 APP_sw025_rightLaneUsage 3 "BLACKLISTED" 2 "FUSED" 1 "AVAILABLE" 0 "REJECTED_UNAVAILABLE" ;
VAL_ 1513 APP_sw025_vehiclesUsage 3 "BLACKLISTED" 2 "FUSED" 1 "AVAILABLE" 0 "REJECTED_UNAVAILABLE" ;
VAL_ 1513 APP_sw025_hppUsage 3 "BLACKLISTED" 2 "FUSED" 1 "AVAILABLE" 0 "REJECTED_UNAVAILABLE" ;
VAL_ 1513 APP_sw025_navigationUsage 3 "BLACKLISTED" 2 "FUSED" 1 "AVAILABLE" 0 "REJECTED_UNAVAILABLE" ;
VAL_ 1513 APP_sw025_modelUsage 3 "BLACKLISTED" 2 "FUSED" 1 "AVAILABLE" 0 "REJECTED_UNAVAILABLE" ;
VAL_ 1513 APP_sw025_bottsDotsUsage 3 "BLACKLISTED" 2 "FUSED" 1 "AVAILABLE" 0 "REJECTED_UNAVAILABLE" ;
VAL_ 1513 APP_sw025_offsetSide 3 "OFFSET_BOTH_OBJECTS" 2 "OFFSET_LEFT_OBJECT" 1 "OFFSET_RIGHT_OBJECT" 0 "NO_OFFSET" ;
VAL_ 1513 APP_sw026_task_id 3 "Vehicle" 2 "Mobileye" 1 "UDS" 0 "CAN" ;
VAL_ 1513 APP_sw030_heaterState 3 "UNAVAILABLE" 2 "SHORT" 1 "OPEN" 0 "NORMAL" ;
VAL_ 1513 APP_sw031_canBus 7 "Unknown" 3 "PT" 2 "PARTY" 1 "RAD0" 0 "CH" ;
VAL_ 1513 APP_sw031_errorType 8 "Generic" 7 "CAN Bus" 6 "Mailbox" 5 "Overrun" 4 "Invalid Data" 3 "Sequence" 2 "Checksum" 1 "Length" 0 "None" ;
VAL_ 1513 APP_sw032_canBus 7 "Unknown" 3 "PT" 2 "PARTY" 1 "RAD0" 0 "CH" ;
VAL_ 1513 APP_sw032_errorType 2 "Generic" 1 "Overrun" 0 "None" ;
VAL_ 1513 APP_sw033_gtwMia 128 "CH_BC_status_MIA" 7 "CH_GTW_carConfig2_MIA" 6 "CH_VIP_405HS_MIA" 5 "CH_GTW_time_MIA" 4 "CH_GTW_status_MIA" 3 "CH_GTW_odo_MIA" 2 "CH_GTW_chNm_MIA" 1 "CH_GTW_carConfig_MIA" 0 "Nominal" ;
VAL_ 1513 APP_sw034_sccmMia 2 "CH_STW_ANGLHP_STAT_MIA" 1 "CH_STW_ACTN_RQ_MIA" 0 "Nominal" ;
VAL_ 1513 APP_sw035_espMia 9 "ESP_B_MIA" 8 "ESP_wheelSpeeds_MIA" 7 "ESP_115h_MIA" 6 "DISCONTINUED_ESP_E_MIA" 5 "ESP_C_MIA" 4 "DISCONTINUED_ESP_A_MIA" 3 "ESP_145h_MIA" 2 "ESP_135h_MIA" 1 "ESP_125h_MIA" 0 "Nominal" ;
VAL_ 1513 APP_sw036_bdyMia 130 "CH_BCS2C_restraintStatus_MIA" 129 "CH_BCS2L_restraintStatus_MIA" 128 "CH_BCS2R_restraintStatus_MIA" 1 "BDY_status_MIA" 0 "Nominal" ;
VAL_ 1513 APP_sw037_issue 1 "Invalid parameters" 0 "Failed to read" ;
VAL_ 1513 APP_sw038_RadarMisalignment 1 "True" 0 "False" ;
VAL_ 1513 APP_sw038_OutOfFocusImage 1 "True" 0 "False" ;
VAL_ 1513 APP_sw038_AutofixOutOfCalib 1 "True" 0 "False" ;
VAL_ 1513 APP_sw038_AutofixOutOfCalibHorzn 1 "True" 0 "False" ;
VAL_ 1513 APP_sw038_AutofixOutOfCalibYaw 1 "True" 0 "False" ;
VAL_ 1513 APP_sw038_FullBlockage 1 "True" 0 "False" ;
VAL_ 1513 APP_sw039_sdm_rcm_Mia 128 "CH_RCM_STATUS_MIA" 1 "CH_SDM1_MIA" 0 "Nominal" ;
VAL_ 1513 APP_sw042_health_state 7 "AP_HEALTH_SNA" 6 "AP_HEALTH_UNUSED" 5 "AP_HEALTH_FAULT" 4 "AP_HEALTH_ABORTING" 3 "AP_HEALTH_SEVERELY_DEGRADED" 2 "AP_HEALTH_DEGRADED" 1 "AP_HEALTH_NOMINAL" 0 "AP_HEALTH_UNAVAILABLE" ;
VAL_ 1513 APP_sw042_abort_reason 27 "LC_ABORT_USER_OVERRIDE_STRIKEOUT" 26 "LC_ABORT_SEATBELT_UNBUCKLED" 25 "LC_ABORT_AEB" 24 "LC_ABORT_DRIVE_ON_MAPS" 23 "LC_ABORT_ECU_THERMAL_ISSUE" 22 "LC_ABORT_CRUISE_WENT_UNAVAILABLE" 21 "RR_ABORT_CONTROL_NOT_ALLOWED" 20 "RR_ABORT_CONTROLLER_HEALTH" 19 "RR_ABORT_WATCHDOG_HEALTH_CRITICAL" 18 "LC_ABORT_APP_ME_STATE" 17 "LC_ABORT_ME_MAIN_STATE" 16 "LC_ABORT_CAMERA_MSG_MIA" 15 "LC_ABORT_CAMERA_WATCHDOG" 14 "LC_ABORT_TRAILER_MODE_ACTIVATION" 13 "LC_ABORT_SIDE_COLLISION_IMMINENT" 12 "LC_ABORT_ACC_CANCEL" 11 "LC_ABORT_CAMERA_FAILSAFES" 10 "LC_ABORT_EPAS_ERROR_CODE" 9 "LC_ABORT_PLANNER_OUTPUT_INVALID" 8 "LC_ABORT_FOLLOWER_OUTPUT_INVALID" 7 "LC_ABORT_VEHICLE_SPEED_ABOVE_MAX" 6 "LC_ABORT_HEALTH_MONITOR" 5 "LC_ABORT_DRIVING_OFF_NAV" 4 "LC_ABORT_CID_SWITCH_DISABLED" 3 "LC_ABORT_CRUISE_FAULT" 2 "LC_ABORT_COMPONENT_MIA" 1 "LC_ABORT_EPAS_EAC_DENIED" 0 "LC_ABORT_NONE" ;
VAL_ 1513 APP_sw042_state_before_abort 15 "LC_INTERNAL_STATE_PRECANCEL" 14 "LC_INTERNAL_STATE_DRIVER_STEERING_OVERRIDE" 13 "LC_INTERNAL_STATE_PREABORTED" 12 "LC_INTERNAL_STATE_FAULT" 11 "LC_INTERNAL_STATE_ABORTED" 10 "LC_INTERNAL_STATE_ABORTING" 9 "LC_INTERNAL_STATE_CHECK_ACTIVATION_WHILE_UNAVAILABLE" 8 "LC_INTERNAL_STATE_CHECK_ACTIVATION_WHILE_DISABLED" 7 "LC_INTERNAL_STATE_ACTIVE_RESTRICTED" 6 "LC_INTERNAL_STATE_ACTIVE_NOMINAL" 5 "LC_INTERNAL_STATE_PREACTIVATION" 4 "LC_INTERNAL_STATE_CHECK_FOR_ACTIVATION" 3 "LC_INTERNAL_STATE_AVAILABLE" 2 "LC_INTERNAL_STATE_UNAVAILABLE" 1 "LC_INTERNAL_STATE_DISABLED" 0 "LC_INTERNAL_STATE_NO_AUTOPILOT" ;
VAL_ 1513 APP_sw042_epas_error_code 15 "SNA" 13 "EAC_ERROR_PINION_VEL_DIFF" 12 "EAC_ERROR_LOW_ASSIST" 11 "EAC_ERROR_HIGH_TORSION_SAFETY" 10 "EAC_ERROR_HIGH_MMOT_SAFETY" 9 "EAC_ERROR_HIGH_ANGLE_RATE_SAFETY" 8 "EAC_ERROR_HIGH_ANGLE_SAFETY" 7 "EAC_ERROR_HIGH_ANGLE_RATE_REQ" 6 "EAC_ERROR_HIGH_ANGLE_REQ" 5 "EAR_ERROR_MAX_STEER_DELTA" 4 "EAC_ERROR_TMP_FAULT" 3 "EAC_ERROR_HANDS_ON" 2 "EAC_ERROR_MAX_SPEED" 1 "EAC_ERROR_MIN_SPEED" 0 "EAC_ERROR_IDLE" ;
VAL_ 1513 APP_sw043_mobileye_status 24 "MOBILEYE_STATUS_UNDEFINED" 23 "MOBILEYE_STATUS_TEARDOWN_FLASH_ACCESS_MODE" 22 "MOBILEYE_STATUS_FLASH_READ_MODE" 21 "MOBILEYE_STATUS_SETUP_FLASH_ACCESS_MODE" 20 "MOBILEYE_STATUS_RUNNING_SPTAC_MODE" 19 "MOBILEYE_STATUS_SPTAC_INIT_SENT" 18 "MOBILEYE_STATUS_WAITING_FOR_SPTAC_INIT" 17 "MOBILEYE_STATUS_BURN_EDR_MODE" 16 "MOBILEYE_STATUS_SPC_INIT_SENT" 15 "MOBILEYE_STATUS_WAITING_FOR_SPC_INIT" 14 "MOBILEYE_STATUS_ERROR" 13 "MOBILEYE_STATUS_LATCHING_FAILURE" 12 "MOBILEYE_STATUS_UPDATING" 11 "MOBILEYE_STATUS_RUNNING_DV_MODE" 10 "MOBILEYE_STATUS_WAITING_FOR_DV" 9 "MOBILEYE_STATUS_RUNNING_TAC_MODE" 8 "MOBILEYE_STATUS_RUNNING_SPC_MODE" 7 "MOBILEYE_STATUS_RUNNING_VISION_MODE" 6 "MOBILEYE_STATUS_TAC_INIT_SENT" 5 "MOBILEYE_STATUS_WAITING_FOR_TAC_INIT" 4 "MOBILEYE_STATUS_VISION_INIT_SENT" 3 "MOBILEYE_STATUS_WAITING_FOR_VISION_INIT" 2 "MOBILEYE_STATUS_WAITING_FOR_BOOT" 1 "MOBILEYE_STATUS_POWER_OFF" 0 "MOBILEYE_STATUS_POWER_CYCLE" ;
VAL_ 1513 APP_sw043_mesp_health_main_state 172 "EYEQ_MESP_MAIN_STATE_TAC2" 170 "EYEQ_MESP_MAIN_STATE_DV" 146 "EYEQ_MESP_MAIN_STATE_VISION_INIT_PENDING" 133 "EYEQ_MESP_MAIN_STATE_TAC2_INIT_PENDING" 130 "EYEQ_MESP_MAIN_STATE_SPC_INIT_PENDING" 129 "EYEQ_MESP_MAIN_STATE_SPTAC_INIT_PENDING" 34 "EYEQ_MESP_MAIN_STATE_SPC" 33 "EYEQ_MESP_MAIN_STATE_SPTAC" 2 "EYEQ_MESP_MAIN_STATE_VISION" ;
VAL_ 1513 APP_sw044_meMainState 8 "ERROR" 7 "DV" 6 "TAC2" 5 "TAC2_INIT_PENDING" 4 "SPC" 3 "SPC_INIT_PENDING" 2 "VISION" 1 "VISION_INIT_PENDING" 0 "NOT_INITIALIZED" ;
VAL_ 1513 APP_sw044_appStatus 24 "MOBILEYE_STATUS_UNDEFINED" 23 "MOBILEYE_STATUS_TEARDOWN_FLASH_ACCESS_MODE" 22 "MOBILEYE_STATUS_FLASH_READ_MODE" 21 "MOBILEYE_STATUS_SETUP_FLASH_ACCESS_MODE" 20 "MOBILEYE_STATUS_RUNNING_SPTAC_MODE" 19 "MOBILEYE_STATUS_SPTAC_INIT_SENT" 18 "MOBILEYE_STATUS_WAITING_FOR_SPTAC_INIT" 17 "MOBILEYE_STATUS_BURN_EDR_MODE" 16 "MOBILEYE_STATUS_SPC_INIT_SENT" 15 "MOBILEYE_STATUS_WAITING_FOR_SPC_INIT" 14 "MOBILEYE_STATUS_ERROR" 13 "MOBILEYE_STATUS_LATCHING_FAILURE" 12 "MOBILEYE_STATUS_UPDATING" 11 "MOBILEYE_STATUS_RUNNING_DV_MODE" 10 "MOBILEYE_STATUS_WAITING_FOR_DV" 9 "MOBILEYE_STATUS_RUNNING_TAC_MODE" 8 "MOBILEYE_STATUS_RUNNING_SPC_MODE" 7 "MOBILEYE_STATUS_RUNNING_VISION_MODE" 6 "MOBILEYE_STATUS_TAC_INIT_SENT" 5 "MOBILEYE_STATUS_WAITING_FOR_TAC_INIT" 4 "MOBILEYE_STATUS_VISION_INIT_SENT" 3 "MOBILEYE_STATUS_WAITING_FOR_VISION_INIT" 2 "MOBILEYE_STATUS_WAITING_FOR_BOOT" 1 "MOBILEYE_STATUS_POWER_OFF" 0 "MOBILEYE_STATUS_POWER_CYCLE" ;
VAL_ 1513 APP_sw045_radMia 21 "RAD0_RADC_TGU_info_MIA" 20 "RAD0_RADC_SGU_info_MIA" 19 "RAD0_RADC_ACCTargObj1_A_MIA" 18 "RAD0_RADC_ACCTargObj1_B_MIA" 17 "RAD0_RADC_ACCTargObj1_C_MIA" 16 "RAD0_RADC_ACCTargObj2_A_MIA" 15 "RAD0_RADC_ACCTargObj2_B_MIA" 14 "RAD0_RADC_ACCTargObj2_C_MIA" 13 "RAD0_RADC_ACCTargObj3_C_MIA" 12 "RAD0_RADC_ACCTargObj4_C_MIA" 11 "RAD0_RADC_ACCTargObj5_A_MIA" 10 "RAD0_RADC_ACCTargObj5_B_MIA" 9 "RAD0_RADC_ACCTargObj5_C_MIA" 8 "RAD0_RADC_FCWTargObj_A_MIA" 7 "RAD0_RADC_FCWTargObj_B_MIA" 6 "RAD0_RADC_FCWTargObj_C_MIA" 5 "RAD0_RADC_Packet_Ender_MIA" 4 "RAD0_RADC_Packet_Starter_MIA" 3 "RAD0_RADC_info_MIA" 2 "RAD0_RADRL_alertMatrix_MIA" 1 "RAD0_RADC_alertMatrix_MIA" 0 "Nominal" ;
VAL_ 1513 APP_sw047_edrStatus 6 "EVENT_TRIGGER_REJECTED" 5 "EVENT_SAVED_TO_FLASH" 4 "EVENT_SAVED_TO_LB" 3 "EVENT_TRIGGERED" 2 "EVENT_ERASED" 1 "FAULTED" 0 "EMPTY" ;
VAL_ 1513 APP_sw047_edrType 13 "PMM_IPSO_TYPE" 12 "ROB_SILENT_TYPE" 11 "ROB_ACTIVE_TYPE" 10 "FREESPACE_ELDW" 9 "AIRBAG_NEAR_DEPLOY" 8 "PMM" 7 "IN_PATH_STAT_OBJ" 6 "SILENT_AEB" 5 "UDS" 4 "FCW" 3 "HEAVY_BRAKING" 2 "AEB" 1 "AIRBAG_DEPLOY" 0 "UNDEFINED" ;
VAL_ 1513 APP_sw047_edrReturn 4000 "ERROR_EDR_MANAGER" 3000 "ERROR_DUMP_FAILED" 2000 "ERROR_LOG_DATA_FAILED" 1027 "ERROR_EDR_MANAGER_INVALID" 1026 "ERROR_POST_TRIGGER_NUM_TOO_LARGE" 1025 "ERROR_BB_NOT_FORMATTED" 1024 "ERROR_BB_VALIDATE_PROBLEM" 1023 "ERROR_FAILED_NO_DESC_AVALIABLE" 1022 "ERROR_NOT_ENOUGH_FRAMES_IN_LB" 1021 "ERROR_FAILED_WRITE_DATA_TO_BB" 1020 "ERROR_FAILED_NO_DATA_AVALIABLE" 1019 "ERROR_LB_CLIP_NOT_AVALIABLE" 1018 "ERROR_LB_ALREADY_CURRENT" 1017 "ERROR_WRONG_STATE" 1016 "ERROR_WRONG_LOGGER_BUFFER" 1015 "ERROR_FAILED_DUMP_LB_TO_BB" 1014 "ERROR_FAILED_FORMAT_BB" 1013 "ERROR_FAILED_TO_BURN_TO_REG_BB" 1012 "ERROR_NOTHING_TO_UPDATE" 1011 "ERROR_WRONG_CURR_TAG" 1010 "ERROR_BB_REG_ERROROR" 1009 "ERROR_DATA_SIZE_MISMATCH" 1008 "ERROR_FUNC_FAILED" 1006 "ERROR_PROCESS_OTHER_TASK" 1005 "ERROR_NO_DATA_TO_SAVE" 1004 "ERROR_FLASH_BB_LOCK" 1003 "ERROR_IMAGE_LOGGER_NOT_FOUND" 1002 "ERROR_BB_NOT_FOUND" 1001 "ERROR_INIT" 1000 "ERROR_UNDEFINED" 107 "ERROR_FUNC_NOT_EXIST" 0 "SUCCESS" ;
VAL_ 1513 APP_sw047_edrStateMachine 255 "EDR_FATAL_ERROR" 54 "PROCESS_EDR_NB_EXECUTE" 53 "PROCESS_EDR_EXECUTE_PART_2" 52 "PROCESS_EDR_EXECUTE_PART_1" 51 "PROCESS_EDR_MAP_LB_TO_BB" 34 "PROCESS_EDR_BB_CANCEL_FORMAT" 33 "PROCESS_EDR_BB_FORMAT" 32 "PROCESS_EDR_BB_GET_DESC" 30 "PROCESS_EDR_BB_QUERY" 16 "PROCESS_EDR_LB_SWITCH" 14 "PROCESS_EDR_LB_SET_DATA" 13 "PROCESS_EDR_LB_SET_DESC" 12 "PROCESS_EDR_LB_TRIGGER_EVENT" 11 "PROCESS_EDR_LB_QUERY" 10 "PROCESS_EDR_LB_GET_CURR" 4 "EDR_BURN_COMPLETE" 2 "EDR_TRIGGERED" 1 "RUNNING" 0 "IDLE" ;
VAL_ 1513 APP_sw049_boot_version_msw 65535 "FLASH_SECTION_EMPTY" 24589 "NO_MISMATCH" 0 "FLASH_READ_FAILURE" ;
VAL_ 1513 APP_sw049_app_version_msw 65535 "FLASH_SECTION_EMPTY" 24589 "NO_MISMATCH" 0 "FLASH_READ_FAILURE" ;
VAL_ 1513 APP_sw049_ffs_version_msw 65535 "FLASH_SECTION_EMPTY" 24589 "NO_MISMATCH" 0 "FLASH_READ_FAILURE" ;
VAL_ 1513 APP_sw051_a01ecuInternalPerf 1 "True" 0 "False" ;
VAL_ 1513 APP_sw051_a02flashPerformance 1 "True" 0 "False" ;
VAL_ 1513 APP_sw051_a03vBatHigh 1 "True" 0 "False" ;
VAL_ 1513 APP_sw051_a09configMismatch 1 "True" 0 "False" ;
VAL_ 1513 APP_sw051_a52radomeHtrInop 1 "True" 0 "False" ;
VAL_ 1513 APP_sw052_a07sensorBlinded 1 "True" 0 "False" ;
VAL_ 1513 APP_sw056_diMia 5 "CH_DI_state2_MIA" 4 "CH_DI_espControl_MIA" 3 "CH_DI_torque2_MIA" 2 "CH_DI_torque1_MIA" 1 "CH_DI_state_MIA" 0 "Nominal" ;
VAL_ 1513 APP_sw057_chCtrlMia 1 "TRUE" 0 "FALSE" ;
VAL_ 1513 APP_sw057_csaOfframpCurvMia 1 "TRUE" 0 "FALSE" ;
VAL_ 1513 APP_sw057_csaRoadCurvMia 1 "TRUE" 0 "FALSE" ;
VAL_ 1513 APP_sw057_dasControlMia 1 "TRUE" 0 "FALSE" ;
VAL_ 1513 APP_sw057_dasMapDataMia 1 "TRUE" 0 "FALSE" ;
VAL_ 1513 APP_sw057_gpsVehSpeedMia 1 "TRUE" 0 "FALSE" ;
VAL_ 1513 APP_sw057_locStatusMia 1 "TRUE" 0 "FALSE" ;
VAL_ 1513 APP_sw057_radarMapDataMia 1 "TRUE" 0 "FALSE" ;
VAL_ 1513 APP_sw057_roadCurvMia 1 "TRUE" 0 "FALSE" ;
VAL_ 1513 APP_sw057_solarDataMia 1 "TRUE" 0 "FALSE" ;
VAL_ 1513 APP_sw057_telemetryControlMia 1 "TRUE" 0 "FALSE" ;
VAL_ 1513 APP_sw057_statusMia 1 "TRUE" 0 "FALSE" ;
VAL_ 1513 APP_sw057_autopilotControlMia 1 "TRUE" 0 "FALSE" ;
VAL_ 1513 APP_sw058_epbMia 1 "CH_EPB_status_MIA" 0 "Nominal" ;
VAL_ 1513 APP_sw059_parkMia 11 "CH_PARK_pasRearMiddle_MIA" 10 "CH_PARK_sensorStatusRear_MIA" 9 "CH_PARK_oloDict_MIA" 8 "CH_PARK_status2_MIA" 7 "CH_PARK_pasFrontMiddle_MIA" 6 "CH_PARK_sensorStatusFront_MIA" 5 "CH_PARK_status_MIA" 4 "CH_PARK_oocStatus_MIA" 3 "CH_PARK_sdiRear_MIA" 2 "CH_PARK_pscStatus_MIA" 1 "CH_PARK_sdiFront_MIA" 0 "Nominal" ;
VAL_ 1513 APP_sw060_collisionWarningSource 7 "SOURCE_BCW_PEDESTRIAN" 6 "SOURCE_BCW_MCVLR" 5 "SOURCE_BCW_CIPV2" 4 "SOURCE_BCW_CIPV" 3 "SOURCE_BCW_CUTIN" 2 "SOURCE_STOPLINE" 1 "SOURCE_FCW_VEHICLE" 0 "SOURCE_FCW_PEDESTRIAN" ;
VAL_ 1513 APP_sw061_airSuspensionMia 128 "CH_TAS_STATES_MIA" 1 "CH_ASD_A2_MIA" 0 "Nominal" ;
VAL_ 1513 APP_sw064_epasMia 2 "PARTY_EPAS_sysStatus_MIA" 1 "CH_EPAS_sysStatus_MIA" 0 "Nominal" ;
VAL_ 1513 APP_sw065_app_mobileye_status 24 "MOBILEYE_STATUS_UNDEFINED" 23 "MOBILEYE_STATUS_TEARDOWN_FLASH_ACCESS_MODE" 22 "MOBILEYE_STATUS_FLASH_READ_MODE" 21 "MOBILEYE_STATUS_SETUP_FLASH_ACCESS_MODE" 20 "MOBILEYE_STATUS_RUNNING_SPTAC_MODE" 19 "MOBILEYE_STATUS_SPTAC_INIT_SENT" 18 "MOBILEYE_STATUS_WAITING_FOR_SPTAC_INIT" 17 "MOBILEYE_STATUS_BURN_EDR_MODE" 16 "MOBILEYE_STATUS_SPC_INIT_SENT" 15 "MOBILEYE_STATUS_WAITING_FOR_SPC_INIT" 14 "MOBILEYE_STATUS_ERROR" 13 "MOBILEYE_STATUS_LATCHING_FAILURE" 12 "MOBILEYE_STATUS_UPDATING" 11 "MOBILEYE_STATUS_RUNNING_DV_MODE" 10 "MOBILEYE_STATUS_WAITING_FOR_DV" 9 "MOBILEYE_STATUS_RUNNING_TAC_MODE" 8 "MOBILEYE_STATUS_RUNNING_SPC_MODE" 7 "MOBILEYE_STATUS_RUNNING_VISION_MODE" 6 "MOBILEYE_STATUS_TAC_INIT_SENT" 5 "MOBILEYE_STATUS_WAITING_FOR_TAC_INIT" 4 "MOBILEYE_STATUS_VISION_INIT_SENT" 3 "MOBILEYE_STATUS_WAITING_FOR_VISION_INIT" 2 "MOBILEYE_STATUS_WAITING_FOR_BOOT" 1 "MOBILEYE_STATUS_POWER_OFF" 0 "MOBILEYE_STATUS_POWER_CYCLE" ;
VAL_ 1513 APP_sw065_mobileye_main_state 255 "EYEQ_MESP_MAIN_STATE_UNDEFINED" 172 "EYEQ_MESP_MAIN_STATE_TAC2" 170 "EYEQ_MESP_MAIN_STATE_DV" 146 "EYEQ_MESP_MAIN_STATE_VISION_INIT_PENDING" 133 "EYEQ_MESP_MAIN_STATE_TAC2_INIT_PENDING" 130 "EYEQ_MESP_MAIN_STATE_SPC_INIT_PENDING" 129 "EYEQ_MESP_MAIN_STATE_SPTAC_INIT_PENDING" 34 "EYEQ_MESP_MAIN_STATE_SPC" 33 "EYEQ_MESP_MAIN_STATE_SPTAC" 2 "EYEQ_MESP_MAIN_STATE_VISION" ;
VAL_ 1513 APP_sw066_app_mobileye_status 24 "MOBILEYE_STATUS_UNDEFINED" 23 "MOBILEYE_STATUS_TEARDOWN_FLASH_ACCESS_MODE" 22 "MOBILEYE_STATUS_FLASH_READ_MODE" 21 "MOBILEYE_STATUS_SETUP_FLASH_ACCESS_MODE" 20 "MOBILEYE_STATUS_RUNNING_SPTAC_MODE" 19 "MOBILEYE_STATUS_SPTAC_INIT_SENT" 18 "MOBILEYE_STATUS_WAITING_FOR_SPTAC_INIT" 17 "MOBILEYE_STATUS_BURN_EDR_MODE" 16 "MOBILEYE_STATUS_SPC_INIT_SENT" 15 "MOBILEYE_STATUS_WAITING_FOR_SPC_INIT" 14 "MOBILEYE_STATUS_ERROR" 13 "MOBILEYE_STATUS_LATCHING_FAILURE" 12 "MOBILEYE_STATUS_UPDATING" 11 "MOBILEYE_STATUS_RUNNING_DV_MODE" 10 "MOBILEYE_STATUS_WAITING_FOR_DV" 9 "MOBILEYE_STATUS_RUNNING_TAC_MODE" 8 "MOBILEYE_STATUS_RUNNING_SPC_MODE" 7 "MOBILEYE_STATUS_RUNNING_VISION_MODE" 6 "MOBILEYE_STATUS_TAC_INIT_SENT" 5 "MOBILEYE_STATUS_WAITING_FOR_TAC_INIT" 4 "MOBILEYE_STATUS_VISION_INIT_SENT" 3 "MOBILEYE_STATUS_WAITING_FOR_VISION_INIT" 2 "MOBILEYE_STATUS_WAITING_FOR_BOOT" 1 "MOBILEYE_STATUS_POWER_OFF" 0 "MOBILEYE_STATUS_POWER_CYCLE" ;
VAL_ 1513 APP_sw066_mobileye_main_state 255 "EYEQ_MESP_MAIN_STATE_UNDEFINED" 172 "EYEQ_MESP_MAIN_STATE_TAC2" 170 "EYEQ_MESP_MAIN_STATE_DV" 146 "EYEQ_MESP_MAIN_STATE_VISION_INIT_PENDING" 133 "EYEQ_MESP_MAIN_STATE_TAC2_INIT_PENDING" 130 "EYEQ_MESP_MAIN_STATE_SPC_INIT_PENDING" 129 "EYEQ_MESP_MAIN_STATE_SPTAC_INIT_PENDING" 34 "EYEQ_MESP_MAIN_STATE_SPC" 33 "EYEQ_MESP_MAIN_STATE_SPTAC" 2 "EYEQ_MESP_MAIN_STATE_VISION" ;
VAL_ 1513 APP_sw069_epasMia 1 "EPAS_MIA" 0 "NO_EPAS_MIA" ;
VAL_ 1513 APP_sw069_espMia 1 "ESP_MIA" 0 "NO_ESP_MIA" ;
VAL_ 1513 APP_sw069_parkMia 1 "PARK_MIA" 0 "NO_PARK_MIA" ;
VAL_ 1513 APP_sw069_sccmMia 1 "SCCM_MIA" 0 "NO_SCCM_MIA" ;
VAL_ 1513 APP_sw069_parkMismatch 1 "PARK_VERSION_MISMATCH" 0 "NO_PARK_VERSION_MISMATCH" ;
VAL_ 1513 APP_sw069_eacStatus 7 "EAC_ELK_ACTIVE" 6 "EAC_ELK_AVAILABLE" 5 "EAC_LKA_ACTIVE" 4 "EAC_LKA_ELK_AVAILABLE" 3 "EAC_FAULT" 2 "EAC_ACTIVE" 1 "EAC_AVAILABLE" 0 "EAC_INHIBITED" ;
VAL_ 1513 APP_sw069_diAPState 15 "DI_APC_SNA" 8 "DI_APC_UNPARK_COMPLETE" 7 "DI_APC_RESUMED" 6 "DI_APC_ABORTED" 5 "DI_APC_PAUSED" 4 "DI_APC_COMPLETE" 3 "DI_APC_ACTIVE" 2 "DI_APC_STARTED" 1 "DI_APC_STANDBY" 0 "DI_APC_UNAVAILABLE" ;
VAL_ 1513 APP_sw069_parkCal 1 "COMPLETE" 0 "INCOMPLETE" ;
VAL_ 1513 APP_sw070_currTireFitment 3 "SNA" 1 "STAGGERED" 0 "SQUARE" ;
VAL_ 1513 APP_sw070_lastTireFitment 3 "SNA" 1 "STAGGERED" 0 "SQUARE" ;
VAL_ 1513 APP_sw070_diGear 7 "DI_GEAR_SNA" 4 "DI_GEAR_D" 3 "DI_GEAR_N" 2 "DI_GEAR_R" 1 "DI_GEAR_P" 0 "DI_GEAR_INVALID" ;
VAL_ 1513 APP_sw071_selfParkType 7 "SNA" 6 "SP_GUIDANCE_UNAVAILABLE" 5 "SP_GUIDANCE_FAULT" 4 "SP_GUIDANCE_ABORT" 3 "SP_GUIDANCE_COMPLETE" 2 "SP_GUIDANCE_UNPARK_ACTIVE" 1 "SP_GUIDANCE_PARK_ACTIVE" 0 "SP_GUIDANCE_STANDBY" ;
VAL_ 1513 APP_sw071_roadClass 6 "CLASS_6_MINOR" 5 "CLASS_5" 4 "CLASS_4" 3 "CLASS_3" 2 "CLASS_2" 1 "CLASS_1_MAJOR" 0 "UNKNOWN_INVALID_SNA" ;
VAL_ 1513 APP_sw071_driverPresent 1 "TRUE" 0 "FALSE" ;
VAL_ 1513 APP_sw071_airSuspension 6 "VERY_HIGH_LEVEL" 5 "HIGH_LEVEL" 4 "NORMAL_LEVEL" 3 "LOW_LEVEL" ;
VAL_ 1513 APP_sw071_activationType 2 "AUTOSUMMON" 1 "KEYFOB" 0 "CELL_PHONE" ;
VAL_ 1513 APP_sw073_escalateLDWreason 3 "LC_ELDW_REASON_STW_TAKEOVER" 2 "LC_ELDW_REASON_DOUBLE_PULL" 1 "LC_ELDW_REASON_SINGLE_PULL" 0 "LC_ELDW_REASON_NONE" ;
VAL_ 1513 APP_sw073_rawMobileyeLDW 3 "RESERVED" 2 "LDW_RIGHT" 1 "LDW_LEFT" 0 "NO_WARNING" ;
VAL_ 1513 APP_sw073_freespaceLDW 3 "RESERVED" 2 "LDW_RIGHT" 1 "LDW_LEFT" 0 "NO_WARNING" ;
VAL_ 1513 APP_sw074_roadClass 6 "CLASS_6_MINOR" 5 "CLASS_5" 4 "CLASS_4" 3 "CLASS_3" 2 "CLASS_2" 1 "CLASS_1_MAJOR" 0 "UNKNOWN_INVALID_SNA" ;
VAL_ 1513 APP_sw074_cruiseActive 1 "CRUISE_ACTIVE" 0 "CRUISE_INACTIVE" ;
VAL_ 1513 APP_sw074_autopilotActive 1 "AUTOPILOT_ACTIVE" 0 "AUTOPILOT_INACTIVE" ;
VAL_ 1513 APP_sw075_scMia 1 "CH_SC_Status_MIA" 0 "Nominal" ;
VAL_ 1513 APP_sw133_mainCamDeserFault 4 "I2C_UNKNOWN_IOCTL_ERR" 3 "I2C_DATA_NACK" 2 "I2C_SLAVE_ADDR_NACK" 1 "I2C_BUS_FAULT" 0 "NO_I2C_FAULT" ;
VAL_ 1513 APP_sw133_mainCamSerFault 4 "I2C_UNKNOWN_IOCTL_ERR" 3 "I2C_DATA_NACK" 2 "I2C_SLAVE_ADDR_NACK" 1 "I2C_BUS_FAULT" 0 "NO_I2C_FAULT" ;
VAL_ 1513 APP_sw133_mainCamSensorFault 4 "I2C_UNKNOWN_IOCTL_ERR" 3 "I2C_DATA_NACK" 2 "I2C_SLAVE_ADDR_NACK" 1 "I2C_BUS_FAULT" 0 "NO_I2C_FAULT" ;
VAL_ 1513 APP_sw134_narrowCamDeserFault 4 "I2C_UNKNOWN_IOCTL_ERR" 3 "I2C_DATA_NACK" 2 "I2C_SLAVE_ADDR_NACK" 1 "I2C_BUS_FAULT" 0 "NO_I2C_FAULT" ;
VAL_ 1513 APP_sw134_narrowCamSerFault 4 "I2C_UNKNOWN_IOCTL_ERR" 3 "I2C_DATA_NACK" 2 "I2C_SLAVE_ADDR_NACK" 1 "I2C_BUS_FAULT" 0 "NO_I2C_FAULT" ;
VAL_ 1513 APP_sw134_narrowCamSensorFault 4 "I2C_UNKNOWN_IOCTL_ERR" 3 "I2C_DATA_NACK" 2 "I2C_SLAVE_ADDR_NACK" 1 "I2C_BUS_FAULT" 0 "NO_I2C_FAULT" ;
VAL_ 1513 APP_sw135_fisheyeCamDeserFault 4 "I2C_UNKNOWN_IOCTL_ERR" 3 "I2C_DATA_NACK" 2 "I2C_SLAVE_ADDR_NACK" 1 "I2C_BUS_FAULT" 0 "NO_I2C_FAULT" ;
VAL_ 1513 APP_sw135_fisheyeCamSerFault 4 "I2C_UNKNOWN_IOCTL_ERR" 3 "I2C_DATA_NACK" 2 "I2C_SLAVE_ADDR_NACK" 1 "I2C_BUS_FAULT" 0 "NO_I2C_FAULT" ;
VAL_ 1513 APP_sw135_fisheyeCamSensorFault 4 "I2C_UNKNOWN_IOCTL_ERR" 3 "I2C_DATA_NACK" 2 "I2C_SLAVE_ADDR_NACK" 1 "I2C_BUS_FAULT" 0 "NO_I2C_FAULT" ;
VAL_ 1513 APP_sw136_lPillarCamDeserFault 4 "I2C_UNKNOWN_IOCTL_ERR" 3 "I2C_DATA_NACK" 2 "I2C_SLAVE_ADDR_NACK" 1 "I2C_BUS_FAULT" 0 "NO_I2C_FAULT" ;
VAL_ 1513 APP_sw136_lPillarCamSerFault 4 "I2C_UNKNOWN_IOCTL_ERR" 3 "I2C_DATA_NACK" 2 "I2C_SLAVE_ADDR_NACK" 1 "I2C_BUS_FAULT" 0 "NO_I2C_FAULT" ;
VAL_ 1513 APP_sw136_lPillarCamSensorFault 4 "I2C_UNKNOWN_IOCTL_ERR" 3 "I2C_DATA_NACK" 2 "I2C_SLAVE_ADDR_NACK" 1 "I2C_BUS_FAULT" 0 "NO_I2C_FAULT" ;
VAL_ 1513 APP_sw137_rPillarCamDeserFault 4 "I2C_UNKNOWN_IOCTL_ERR" 3 "I2C_DATA_NACK" 2 "I2C_SLAVE_ADDR_NACK" 1 "I2C_BUS_FAULT" 0 "NO_I2C_FAULT" ;
VAL_ 1513 APP_sw137_rPillarCamSerFault 4 "I2C_UNKNOWN_IOCTL_ERR" 3 "I2C_DATA_NACK" 2 "I2C_SLAVE_ADDR_NACK" 1 "I2C_BUS_FAULT" 0 "NO_I2C_FAULT" ;
VAL_ 1513 APP_sw137_rPillarCamSensorFault 4 "I2C_UNKNOWN_IOCTL_ERR" 3 "I2C_DATA_NACK" 2 "I2C_SLAVE_ADDR_NACK" 1 "I2C_BUS_FAULT" 0 "NO_I2C_FAULT" ;
VAL_ 1513 APP_sw138_lRepeatCamDeserFault 4 "I2C_UNKNOWN_IOCTL_ERR" 3 "I2C_DATA_NACK" 2 "I2C_SLAVE_ADDR_NACK" 1 "I2C_BUS_FAULT" 0 "NO_I2C_FAULT" ;
VAL_ 1513 APP_sw138_lRepeatCamSerFault 4 "I2C_UNKNOWN_IOCTL_ERR" 3 "I2C_DATA_NACK" 2 "I2C_SLAVE_ADDR_NACK" 1 "I2C_BUS_FAULT" 0 "NO_I2C_FAULT" ;
VAL_ 1513 APP_sw138_lRepeatCamSensorFault 4 "I2C_UNKNOWN_IOCTL_ERR" 3 "I2C_DATA_NACK" 2 "I2C_SLAVE_ADDR_NACK" 1 "I2C_BUS_FAULT" 0 "NO_I2C_FAULT" ;
VAL_ 1513 APP_sw139_rRepeatCamDeserFault 4 "I2C_UNKNOWN_IOCTL_ERR" 3 "I2C_DATA_NACK" 2 "I2C_SLAVE_ADDR_NACK" 1 "I2C_BUS_FAULT" 0 "NO_I2C_FAULT" ;
VAL_ 1513 APP_sw139_rRepeatCamSerFault 4 "I2C_UNKNOWN_IOCTL_ERR" 3 "I2C_DATA_NACK" 2 "I2C_SLAVE_ADDR_NACK" 1 "I2C_BUS_FAULT" 0 "NO_I2C_FAULT" ;
VAL_ 1513 APP_sw139_rRepeatCamSensorFault 4 "I2C_UNKNOWN_IOCTL_ERR" 3 "I2C_DATA_NACK" 2 "I2C_SLAVE_ADDR_NACK" 1 "I2C_BUS_FAULT" 0 "NO_I2C_FAULT" ;
VAL_ 1513 APP_sw140_backupCamDeserFault 4 "I2C_UNKNOWN_IOCTL_ERR" 3 "I2C_DATA_NACK" 2 "I2C_SLAVE_ADDR_NACK" 1 "I2C_BUS_FAULT" 0 "NO_I2C_FAULT" ;
VAL_ 1513 APP_sw140_backupCamCSIBridgeFlt 4 "I2C_UNKNOWN_IOCTL_ERR" 3 "I2C_DATA_NACK" 2 "I2C_SLAVE_ADDR_NACK" 1 "I2C_BUS_FAULT" 0 "NO_I2C_FAULT" ;
VAL_ 1513 APP_sw140_backupCamSensorFault 4 "I2C_UNKNOWN_IOCTL_ERR" 3 "I2C_DATA_NACK" 2 "I2C_SLAVE_ADDR_NACK" 1 "I2C_BUS_FAULT" 0 "NO_I2C_FAULT" ;
VAL_ 1513 APP_sw140_backupCamDeserLock 2 "LOCK_STATUS_UNKNOWN" 1 "LOCK_STATUS_LOST" 0 "LOCK_STATUS_LOCKED" ;
VAL_ 1513 APP_sw140_backupCamSerFault 4 "I2C_UNKNOWN_IOCTL_ERR" 3 "I2C_DATA_NACK" 2 "I2C_SLAVE_ADDR_NACK" 1 "I2C_BUS_FAULT" 0 "NO_I2C_FAULT" ;
VAL_ 1513 APP_sw142_problemCamPosition 9 "CAM_SELFIE" 8 "CAM_BACKUP" 7 "CAM_R_REPEATER" 6 "CAM_L_REPEATER" 5 "CAM_R_PILLAR" 4 "CAM_L_PILLAR" 3 "CAM_FISHEYE" 2 "CAM_NARROW" 1 "CAM_MAIN" 0 "CAM_INVALID" ;

SIG_GROUP_ 543 ALDW_Rq 1 : ALDW_BrkMsgDisp_Rq ALDW_ImgSyncNum ALDW_IndLmp_On_Rq ALDW_LaneMarkWidth_Lt ALDW_LaneMarkWidth_Rt ALDW_LaneMark_DtctDist ALDW_Menu_Enbl_Rq ALDW_MsgDisp_Rq ALDW_OnCalExecDist ALDW_OnCal_Stat ALDW_PulseTm_Rq ALDW_VibTm_Rq ALDW_WarnMd_Rq ALDW_Warn_Rq CRC_ALDW_A1 MC_ALDW_A1;
